VERSION ""

NS_ :

BS_:

BU_:

BO_ 2556493566 MG1IRP: 8 Vector__XXX
 SG_ MtrGnrtr1InvrtrLmtsRqstPwrCRC : 0|8@1+ (1,0) [0|255] "count" Vector__XXX
 SG_ MtrGnrtr1InvrtrLmtsRqstPwrCntr : 8|4@1+ (1,0) [0|15] "" Vector__XXX

BO_ 2556559102 PDI: 8 Vector__XXX
 SG_ PrsnnlDttAlrmRvStts : 0|3@1+ (1,0) [0|7] "" Vector__XXX
 SG_ PrsnnlDttSqnCntrEh : 8|8@1+ (1,0) [0|255] "count" Vector__XXX

BO_ 2556624638 ECCCF: 8 Vector__XXX
 SG_ CnfgrdEngnClndrMssFrtnBrndLtn1 : 0|8@1+ (0.4,0) [0|100] "%" Vector__XXX
 SG_ CnfgrdEngnClndrMssFrtnBrndLtn2 : 8|8@1+ (0.4,0) [0|100] "%" Vector__XXX

BO_ 2556690174 ECCC: 8 Vector__XXX
 SG_ EngnClndrMssFrtnBrndLtn1 : 0|8@1+ (0.4,0) [0|100] "%" Vector__XXX
 SG_ EngnClndrMssFrtnBrndLtn2 : 8|8@1+ (0.4,0) [0|100] "%" Vector__XXX

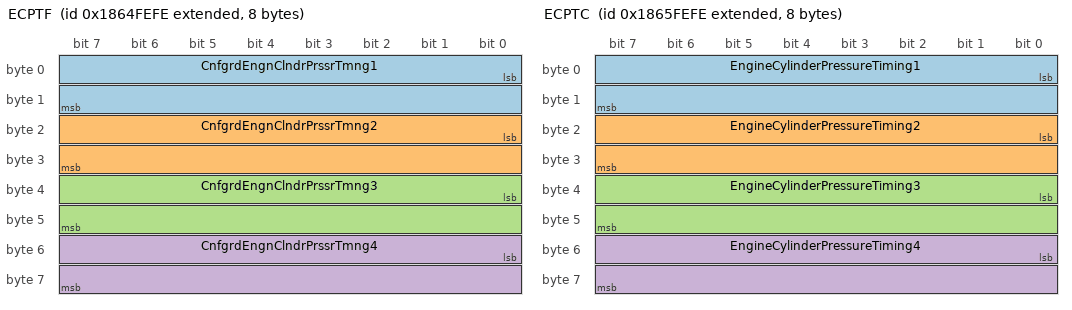
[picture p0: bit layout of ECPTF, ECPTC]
BO_ 2556755710 ECPTF: 8 Vector__XXX
 SG_ CnfgrdEngnClndrPrssrTmng1 : 0|16@1+ (0.0125,-360) [-360|443.1875] "deg" Vector__XXX
 SG_ CnfgrdEngnClndrPrssrTmng2 : 16|16@1+ (0.0125,-360) [-360|443.1875] "deg" Vector__XXX
 SG_ CnfgrdEngnClndrPrssrTmng3 : 32|16@1+ (0.0125,-360) [-360|443.1875] "deg" Vector__XXX
 SG_ CnfgrdEngnClndrPrssrTmng4 : 48|16@1+ (0.0125,-360) [-360|443.1875] "deg" Vector__XXX

BO_ 2556821246 ECPTC: 8 Vector__XXX
 SG_ EngineCylinderPressureTiming1 : 0|16@1+ (0.0125,-360) [-360|443.1875] "deg" Vector__XXX
 SG_ EngineCylinderPressureTiming2 : 16|16@1+ (0.0125,-360) [-360|443.1875] "deg" Vector__XXX
 SG_ EngineCylinderPressureTiming3 : 32|16@1+ (0.0125,-360) [-360|443.1875] "deg" Vector__XXX
 SG_ EngineCylinderPressureTiming4 : 48|16@1+ (0.0125,-360) [-360|443.1875] "deg" Vector__XXX

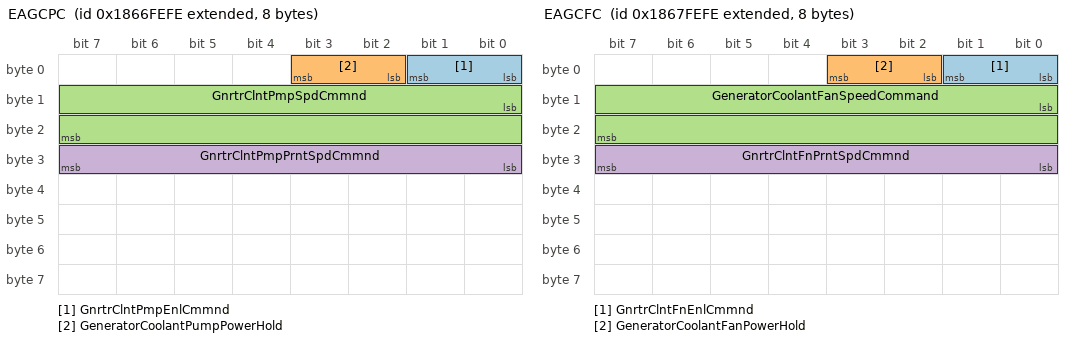
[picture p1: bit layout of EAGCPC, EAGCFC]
BO_ 2556886782 EAGCPC: 8 Vector__XXX
 SG_ GnrtrClntPmpEnlCmmnd : 0|2@1+ (1,0) [0|3] "" Vector__XXX
 SG_ GeneratorCoolantPumpPowerHold : 2|2@1+ (1,0) [0|3] "" Vector__XXX
 SG_ GnrtrClntPmpSpdCmmnd : 8|16@1+ (0.5,0) [0|32127.5] "rpm" Vector__XXX
 SG_ GnrtrClntPmpPrntSpdCmmnd : 24|8@1+ (0.5,0) [0|125] "%" Vector__XXX

BO_ 2556952318 EAGCFC: 8 Vector__XXX
 SG_ GnrtrClntFnEnlCmmnd : 0|2@1+ (1,0) [0|3] "" Vector__XXX
 SG_ GeneratorCoolantFanPowerHold : 2|2@1+ (1,0) [0|3] "" Vector__XXX
 SG_ GeneratorCoolantFanSpeedCommand : 8|16@1+ (0.5,0) [0|32127.5] "rpm" Vector__XXX
 SG_ GnrtrClntFnPrntSpdCmmnd : 24|8@1+ (0.5,0) [0|125] "%" Vector__XXX

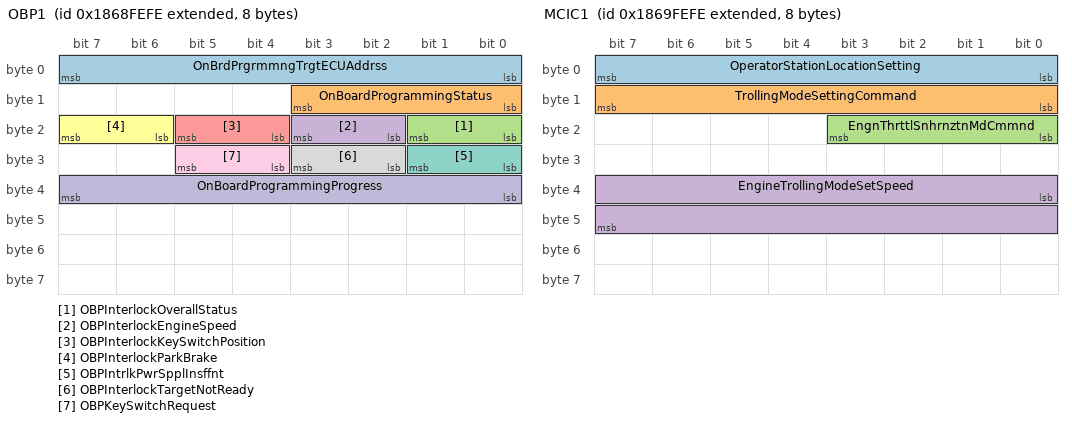
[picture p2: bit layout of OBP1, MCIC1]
BO_ 2557017854 OBP1: 8 Vector__XXX
 SG_ OnBrdPrgrmmngTrgtECUAddrss : 0|8@1+ (1,0) [0|255] "SA" Vector__XXX
 SG_ OnBoardProgrammingStatus : 8|4@1+ (1,0) [0|15] "" Vector__XXX
 SG_ OBPInterlockOverallStatus : 16|2@1+ (1,0) [0|3] "" Vector__XXX
 SG_ OBPInterlockEngineSpeed : 18|2@1+ (1,0) [0|3] "" Vector__XXX
 SG_ OBPInterlockKeySwitchPosition : 20|2@1+ (1,0) [0|3] "" Vector__XXX
 SG_ OBPInterlockParkBrake : 22|2@1+ (1,0) [0|3] "" Vector__XXX
 SG_ OBPIntrlkPwrSpplInsffnt : 24|2@1+ (1,0) [0|3] "" Vector__XXX
 SG_ OBPInterlockTargetNotReady : 26|2@1+ (1,0) [0|3] "" Vector__XXX
 SG_ OBPKeySwitchRequest : 28|2@1+ (1,0) [0|3] "" Vector__XXX
 SG_ OnBoardProgrammingProgress : 32|8@1+ (0.5,0) [0|125] "%" Vector__XXX

BO_ 2557083390 MCIC1: 8 Vector__XXX
 SG_ OperatorStationLocationSetting : 0|8@1+ (1,0) [0|250] "ID" Vector__XXX
 SG_ TrollingModeSettingCommand : 8|8@1+ (1,0) [0|255] "" Vector__XXX
 SG_ EngnThrttlSnhrnztnMdCmmnd : 16|4@1+ (1,0) [0|15] "" Vector__XXX
 SG_ EngineTrollingModeSetSpeed : 32|16@1+ (0.125,0) [0|8031.875] "rpm" Vector__XXX

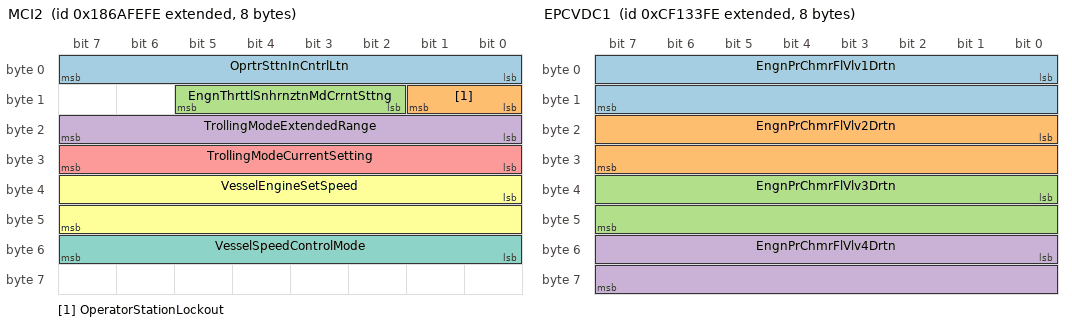
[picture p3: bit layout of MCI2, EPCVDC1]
BO_ 2557148926 MCI2: 8 Vector__XXX
 SG_ OprtrSttnInCntrlLtn : 0|8@1+ (1,0) [0|250] "ID" Vector__XXX
 SG_ OperatorStationLockout : 8|2@1+ (1,0) [0|3] "" Vector__XXX
 SG_ EngnThrttlSnhrnztnMdCrrntSttng : 10|4@1+ (1,0) [0|15] "" Vector__XXX
 SG_ TrollingModeExtendedRange : 16|8@1+ (1,0) [0|255] "" Vector__XXX
 SG_ TrollingModeCurrentSetting : 24|8@1+ (1,0) [0|255] "" Vector__XXX
 SG_ VesselEngineSetSpeed : 32|16@1+ (0.125,0) [0|8031.875] "rpm" Vector__XXX
 SG_ VesselSpeedControlMode : 48|8@1+ (1,0) [0|255] "" Vector__XXX

BO_ 2364617726 EPCVDC1: 8 Vector__XXX
 SG_ EngnPrChmrFlVlv1Drtn : 0|16@1+ (2,0) [0|128510] "micro s" Vector__XXX
 SG_ EngnPrChmrFlVlv2Drtn : 16|16@1+ (2,0) [0|128510] "micro s" Vector__XXX
 SG_ EngnPrChmrFlVlv3Drtn : 32|16@1+ (2,0) [0|128510] "micro s" Vector__XXX
 SG_ EngnPrChmrFlVlv4Drtn : 48|16@1+ (2,0) [0|128510] "micro s" Vector__XXX

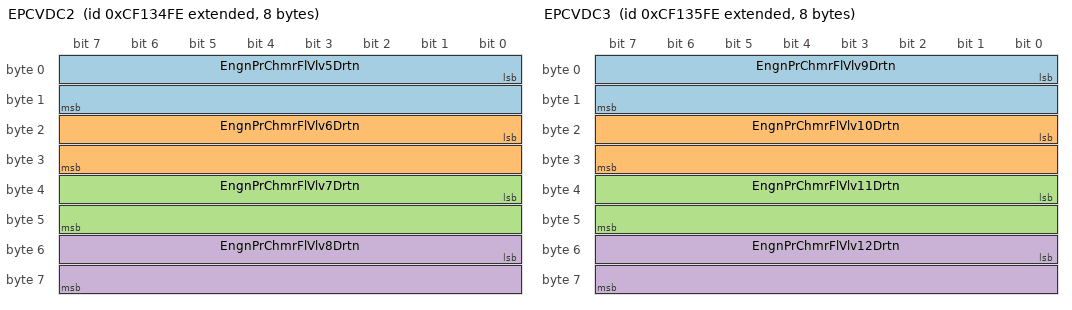
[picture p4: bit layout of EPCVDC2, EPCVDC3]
BO_ 2364617982 EPCVDC2: 8 Vector__XXX
 SG_ EngnPrChmrFlVlv5Drtn : 0|16@1+ (2,0) [0|128510] "micro s" Vector__XXX
 SG_ EngnPrChmrFlVlv6Drtn : 16|16@1+ (2,0) [0|128510] "micro s" Vector__XXX
 SG_ EngnPrChmrFlVlv7Drtn : 32|16@1+ (2,0) [0|128510] "micro s" Vector__XXX
 SG_ EngnPrChmrFlVlv8Drtn : 48|16@1+ (2,0) [0|128510] "micro s" Vector__XXX

BO_ 2364618238 EPCVDC3: 8 Vector__XXX
 SG_ EngnPrChmrFlVlv9Drtn : 0|16@1+ (2,0) [0|128510] "micro s" Vector__XXX
 SG_ EngnPrChmrFlVlv10Drtn : 16|16@1+ (2,0) [0|128510] "micro s" Vector__XXX
 SG_ EngnPrChmrFlVlv11Drtn : 32|16@1+ (2,0) [0|128510] "micro s" Vector__XXX
 SG_ EngnPrChmrFlVlv12Drtn : 48|16@1+ (2,0) [0|128510] "micro s" Vector__XXX

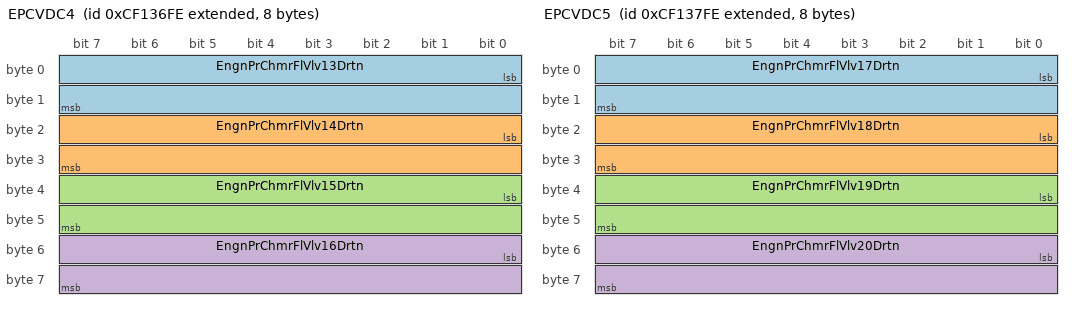
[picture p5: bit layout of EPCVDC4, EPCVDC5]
BO_ 2364618494 EPCVDC4: 8 Vector__XXX
 SG_ EngnPrChmrFlVlv13Drtn : 0|16@1+ (2,0) [0|128510] "micro s" Vector__XXX
 SG_ EngnPrChmrFlVlv14Drtn : 16|16@1+ (2,0) [0|128510] "micro s" Vector__XXX
 SG_ EngnPrChmrFlVlv15Drtn : 32|16@1+ (2,0) [0|128510] "micro s" Vector__XXX
 SG_ EngnPrChmrFlVlv16Drtn : 48|16@1+ (2,0) [0|128510] "micro s" Vector__XXX

BO_ 2364618750 EPCVDC5: 8 Vector__XXX
 SG_ EngnPrChmrFlVlv17Drtn : 0|16@1+ (2,0) [0|128510] "micro s" Vector__XXX
 SG_ EngnPrChmrFlVlv18Drtn : 16|16@1+ (2,0) [0|128510] "micro s" Vector__XXX
 SG_ EngnPrChmrFlVlv19Drtn : 32|16@1+ (2,0) [0|128510] "micro s" Vector__XXX
 SG_ EngnPrChmrFlVlv20Drtn : 48|16@1+ (2,0) [0|128510] "micro s" Vector__XXX

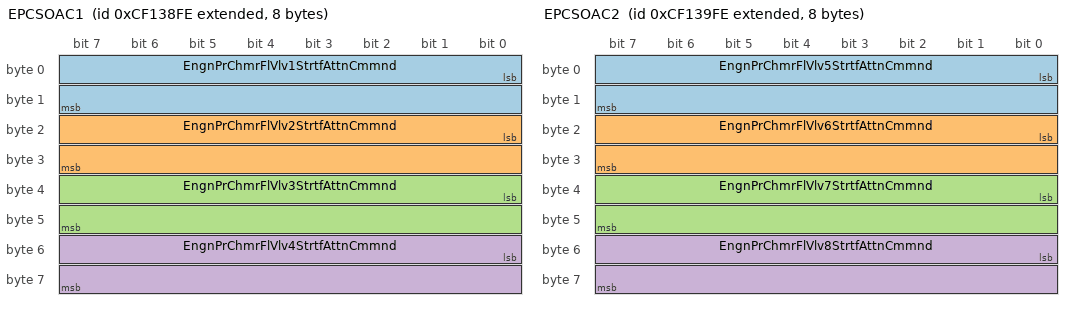
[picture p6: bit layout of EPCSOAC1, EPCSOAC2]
BO_ 2364619006 EPCSOAC1: 8 Vector__XXX
 SG_ EngnPrChmrFlVlv1StrtfAttnCmmnd : 0|16@1+ (0.0078125,-400) [-400|101.99] "deg" Vector__XXX
 SG_ EngnPrChmrFlVlv2StrtfAttnCmmnd : 16|16@1+ (0.0078125,-400) [-400|101.99] "deg" Vector__XXX
 SG_ EngnPrChmrFlVlv3StrtfAttnCmmnd : 32|16@1+ (0.0078125,-400) [-400|101.99] "deg" Vector__XXX
 SG_ EngnPrChmrFlVlv4StrtfAttnCmmnd : 48|16@1+ (0.0078125,-400) [-400|101.99] "deg" Vector__XXX

BO_ 2364619262 EPCSOAC2: 8 Vector__XXX
 SG_ EngnPrChmrFlVlv5StrtfAttnCmmnd : 0|16@1+ (0.0078125,-400) [-400|101.99] "deg" Vector__XXX
 SG_ EngnPrChmrFlVlv6StrtfAttnCmmnd : 16|16@1+ (0.0078125,-400) [-400|101.99] "deg" Vector__XXX
 SG_ EngnPrChmrFlVlv7StrtfAttnCmmnd : 32|16@1+ (0.0078125,-400) [-400|101.99] "deg" Vector__XXX
 SG_ EngnPrChmrFlVlv8StrtfAttnCmmnd : 48|16@1+ (0.0078125,-400) [-400|101.99] "deg" Vector__XXX

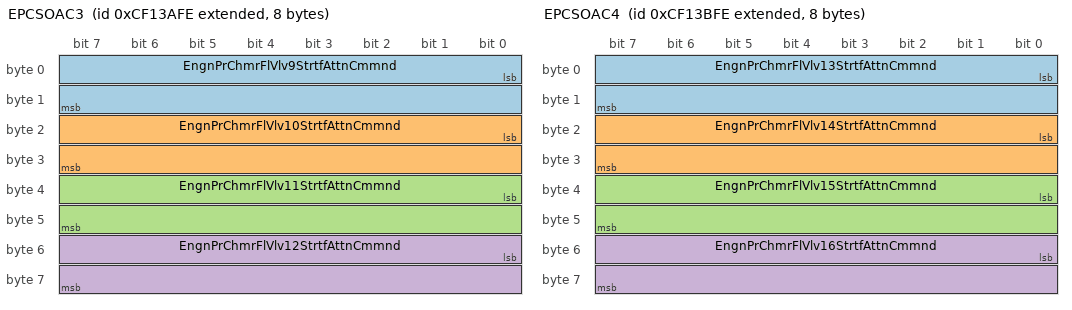
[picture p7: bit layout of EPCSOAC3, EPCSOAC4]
BO_ 2364619518 EPCSOAC3: 8 Vector__XXX
 SG_ EngnPrChmrFlVlv9StrtfAttnCmmnd : 0|16@1+ (0.0078125,-400) [-400|101.99] "deg" Vector__XXX
 SG_ EngnPrChmrFlVlv10StrtfAttnCmmnd : 16|16@1+ (0.0078125,-400) [-400|101.99] "deg" Vector__XXX
 SG_ EngnPrChmrFlVlv11StrtfAttnCmmnd : 32|16@1+ (0.0078125,-400) [-400|101.99] "deg" Vector__XXX
 SG_ EngnPrChmrFlVlv12StrtfAttnCmmnd : 48|16@1+ (0.0078125,-400) [-400|101.99] "deg" Vector__XXX

BO_ 2364619774 EPCSOAC4: 8 Vector__XXX
 SG_ EngnPrChmrFlVlv13StrtfAttnCmmnd : 0|16@1+ (0.0078125,-400) [-400|101.99] "deg" Vector__XXX
 SG_ EngnPrChmrFlVlv14StrtfAttnCmmnd : 16|16@1+ (0.0078125,-400) [-400|101.99] "deg" Vector__XXX
 SG_ EngnPrChmrFlVlv15StrtfAttnCmmnd : 32|16@1+ (0.0078125,-400) [-400|101.99] "deg" Vector__XXX
 SG_ EngnPrChmrFlVlv16StrtfAttnCmmnd : 48|16@1+ (0.0078125,-400) [-400|101.99] "deg" Vector__XXX

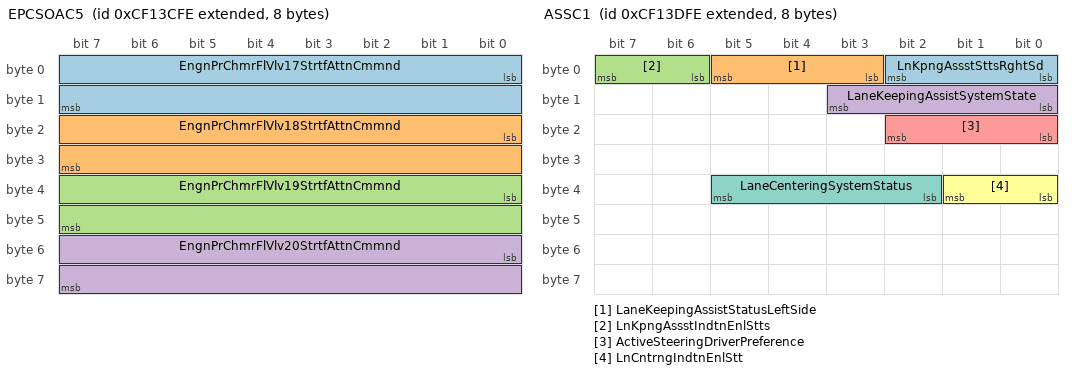
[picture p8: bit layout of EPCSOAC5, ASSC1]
BO_ 2364620030 EPCSOAC5: 8 Vector__XXX
 SG_ EngnPrChmrFlVlv17StrtfAttnCmmnd : 0|16@1+ (0.0078125,-400) [-400|101.99] "deg" Vector__XXX
 SG_ EngnPrChmrFlVlv18StrtfAttnCmmnd : 16|16@1+ (0.0078125,-400) [-400|101.99] "deg" Vector__XXX
 SG_ EngnPrChmrFlVlv19StrtfAttnCmmnd : 32|16@1+ (0.0078125,-400) [-400|101.99] "deg" Vector__XXX
 SG_ EngnPrChmrFlVlv20StrtfAttnCmmnd : 48|16@1+ (0.0078125,-400) [-400|101.99] "deg" Vector__XXX

BO_ 2364620286 ASSC1: 8 Vector__XXX
 SG_ LnKpngAssstSttsRghtSd : 0|3@1+ (1,0) [0|7] "" Vector__XXX
 SG_ LaneKeepingAssistStatusLeftSide : 3|3@1+ (1,0) [0|7] "" Vector__XXX
 SG_ LnKpngAssstIndtnEnlStts : 6|2@1+ (1,0) [0|3] "" Vector__XXX
 SG_ LaneKeepingAssistSystemState : 8|4@1+ (1,0) [0|15] "" Vector__XXX
 SG_ ActiveSteeringDriverPreference : 16|3@1+ (1,0) [0|7] "" Vector__XXX
 SG_ LnCntrngIndtnEnlStt : 32|2@1+ (1,0) [0|3] "" Vector__XXX
 SG_ LaneCenteringSystemStatus : 34|4@1+ (1,0) [0|15] "" Vector__XXX

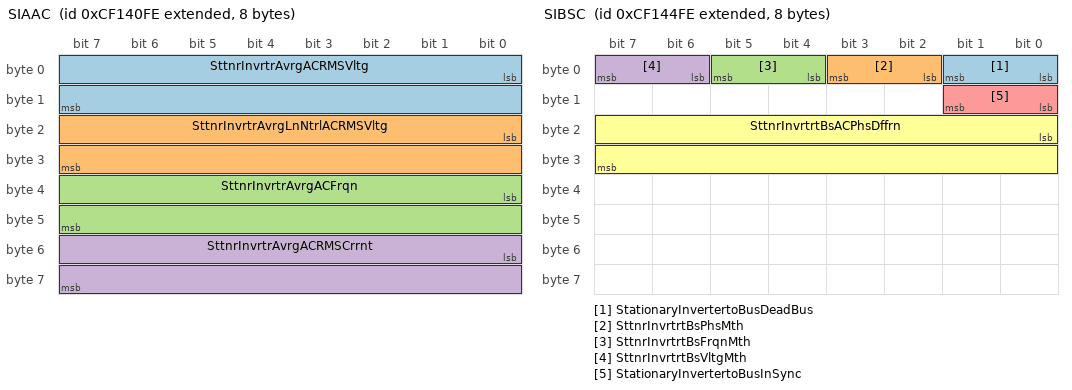
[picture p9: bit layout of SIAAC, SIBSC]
BO_ 2364621054 SIAAC: 8 Vector__XXX
 SG_ SttnrInvrtrAvrgACRMSVltg : 0|16@1+ (1,0) [0|64255] "V" Vector__XXX
 SG_ SttnrInvrtrAvrgLnNtrlACRMSVltg : 16|16@1+ (1,0) [0|64255] "V" Vector__XXX
 SG_ SttnrInvrtrAvrgACFrqn : 32|16@1+ (0.0078125,0) [0|501.9921875] "Hz" Vector__XXX
 SG_ SttnrInvrtrAvrgACRMSCrrnt : 48|16@1+ (1,0) [0|64255] "A" Vector__XXX

BO_ 2364621310 SITACR: 8 Vector__XXX
 SG_ SttnrInvrtrTtlRtvPwr : 0|32@1+ (1,-2000000000) [-2000000000|2.21108E+09] "VAr" Vector__XXX
 SG_ SttnrInvrtrOvrllPwrFtr : 32|16@1+ (0.00006103515625,-1) [-1|2.921814] "" Vector__XXX
 SG_ SttnrInvrtrOvrllPwrFtrLggng : 48|2@1+ (1,0) [0|3] "" Vector__XXX

BO_ 2364621566 SITACP: 8 Vector__XXX
 SG_ SttnrInvrtrTtlRlPwr : 0|32@1+ (1,-2000000000) [-2000000000|2.21108E+09] "W" Vector__XXX
 SG_ SttnrInvrtrTtlApprntPwr : 32|32@1+ (1,-2000000000) [-2000000000|2.21108E+09] "VA" Vector__XXX

BO_ 2364621822 SIC: 8 Vector__XXX
 SG_ SttnrInvrtrNtRdtAtmtllPrlllStt : 0|2@1+ (1,0) [0|3] "" Vector__XXX
 SG_ SttnrInvrtrAxlrShtdwnSwth : 2|2@1+ (1,0) [0|3] "" Vector__XXX

BO_ 2364622078 SIBSC: 8 Vector__XXX
 SG_ StationaryInvertertoBusDeadBus : 0|2@1+ (1,0) [0|3] "" Vector__XXX
 SG_ SttnrInvrtrtBsPhsMth : 2|2@1+ (1,0) [0|3] "" Vector__XXX
 SG_ SttnrInvrtrtBsFrqnMth : 4|2@1+ (1,0) [0|3] "" Vector__XXX
 SG_ SttnrInvrtrtBsVltgMth : 6|2@1+ (1,0) [0|3] "" Vector__XXX
 SG_ StationaryInvertertoBusInSync : 8|2@1+ (1,0) [0|3] "" Vector__XXX
 SG_ SttnrInvrtrtBsACPhsDffrn : 16|16@1+ (0.0078125,-200) [-200|301.99] "deg" Vector__XXX

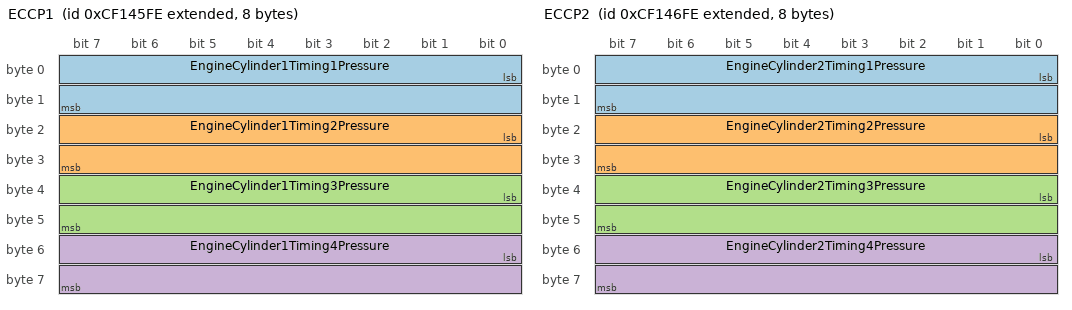
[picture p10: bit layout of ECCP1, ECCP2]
BO_ 2364622334 ECCP1: 8 Vector__XXX
 SG_ EngineCylinder1Timing1Pressure : 0|16@1+ (0.0009765625,0) [0|62.74902344] "MPa" Vector__XXX
 SG_ EngineCylinder1Timing2Pressure : 16|16@1+ (0.0009765625,0) [0|62.74902344] "MPa" Vector__XXX
 SG_ EngineCylinder1Timing3Pressure : 32|16@1+ (0.0009765625,0) [0|62.74902344] "MPa" Vector__XXX
 SG_ EngineCylinder1Timing4Pressure : 48|16@1+ (0.0009765625,0) [0|62.74902344] "MPa" Vector__XXX

BO_ 2364622590 ECCP2: 8 Vector__XXX
 SG_ EngineCylinder2Timing1Pressure : 0|16@1+ (0.0009765625,0) [0|62.74902344] "MPa" Vector__XXX
 SG_ EngineCylinder2Timing2Pressure : 16|16@1+ (0.0009765625,0) [0|62.74902344] "MPa" Vector__XXX
 SG_ EngineCylinder2Timing3Pressure : 32|16@1+ (0.0009765625,0) [0|62.74902344] "MPa" Vector__XXX
 SG_ EngineCylinder2Timing4Pressure : 48|16@1+ (0.0009765625,0) [0|62.74902344] "MPa" Vector__XXX

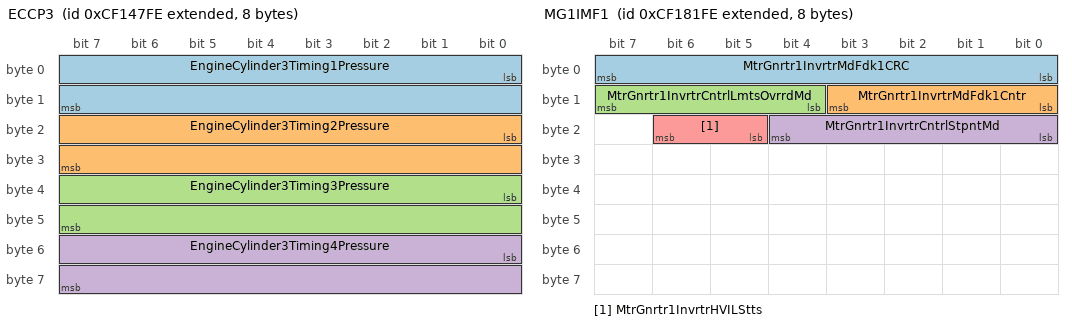
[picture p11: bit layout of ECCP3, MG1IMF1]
BO_ 2364622846 ECCP3: 8 Vector__XXX
 SG_ EngineCylinder3Timing1Pressure : 0|16@1+ (0.0009765625,0) [0|62.74902344] "MPa" Vector__XXX
 SG_ EngineCylinder3Timing2Pressure : 16|16@1+ (0.0009765625,0) [0|62.74902344] "MPa" Vector__XXX
 SG_ EngineCylinder3Timing3Pressure : 32|16@1+ (0.0009765625,0) [0|62.74902344] "MPa" Vector__XXX
 SG_ EngineCylinder3Timing4Pressure : 48|16@1+ (0.0009765625,0) [0|62.74902344] "MPa" Vector__XXX

BO_ 2364623102 ECCP4: 8 Vector__XXX
 SG_ EngineCylinder4Timing1Pressure : 0|16@1+ (0.0009765625,0) [0|62.74902344] "MPa" Vector__XXX
 SG_ EngineCylinder4Timing2Pressure : 16|16@1+ (0.0009765625,0) [0|62.74902344] "MPa" Vector__XXX
 SG_ EngineCylinder4Timing3Pressure : 32|16@1+ (0.0009765625,0) [0|62.74902344] "MPa" Vector__XXX
 SG_ EngineCylinder4Timing4Pressure : 48|16@1+ (0.0009765625,0) [0|62.74902344] "MPa" Vector__XXX

BO_ 2364623358 ECCP5: 8 Vector__XXX
 SG_ EngineCylinder5Timing1Pressure : 0|16@1+ (0.0009765625,0) [0|62.74902344] "MPa" Vector__XXX
 SG_ EngineCylinder5Timing2Pressure : 16|16@1+ (0.0009765625,0) [0|62.74902344] "MPa" Vector__XXX
 SG_ EngineCylinder5Timing3Pressure : 32|16@1+ (0.0009765625,0) [0|62.74902344] "MPa" Vector__XXX
 SG_ EngineCylinder5Timing4Pressure : 48|16@1+ (0.0009765625,0) [0|62.74902344] "MPa" Vector__XXX

BO_ 2364623614 ECCP6: 8 Vector__XXX
 SG_ EngineCylinder6Timing1Pressure : 0|16@1+ (0.0009765625,0) [0|62.74902344] "MPa" Vector__XXX
 SG_ EngineCylinder6Timing2Pressure : 16|16@1+ (0.0009765625,0) [0|62.74902344] "MPa" Vector__XXX
 SG_ EngineCylinder6Timing3Pressure : 32|16@1+ (0.0009765625,0) [0|62.74902344] "MPa" Vector__XXX
 SG_ EngineCylinder6Timing4Pressure : 48|16@1+ (0.0009765625,0) [0|62.74902344] "MPa" Vector__XXX

BO_ 2364623870 ECCP7: 8 Vector__XXX
 SG_ EngineCylinder7Timing1Pressure : 0|16@1+ (0.0009765625,0) [0|62.74902344] "MPa" Vector__XXX
 SG_ EngineCylinder7Timing2Pressure : 16|16@1+ (0.0009765625,0) [0|62.74902344] "MPa" Vector__XXX
 SG_ EngineCylinder7Timing3Pressure : 32|16@1+ (0.0009765625,0) [0|62.74902344] "MPa" Vector__XXX
 SG_ EngineCylinder7Timing4Pressure : 48|16@1+ (0.0009765625,0) [0|62.74902344] "MPa" Vector__XXX

BO_ 2364624126 ECCP8: 8 Vector__XXX
 SG_ EngineCylinder8Timing1Pressure : 0|16@1+ (0.0009765625,0) [0|62.74902344] "MPa" Vector__XXX
 SG_ EngineCylinder8Timing2Pressure : 16|16@1+ (0.0009765625,0) [0|62.74902344] "MPa" Vector__XXX
 SG_ EngineCylinder8Timing3Pressure : 32|16@1+ (0.0009765625,0) [0|62.74902344] "MPa" Vector__XXX
 SG_ EngineCylinder8Timing4Pressure : 48|16@1+ (0.0009765625,0) [0|62.74902344] "MPa" Vector__XXX

BO_ 2364624382 ECCP9: 8 Vector__XXX
 SG_ EngineCylinder9Timing1Pressure : 0|16@1+ (0.0009765625,0) [0|62.74902344] "MPa" Vector__XXX
 SG_ EngineCylinder9Timing2Pressure : 16|16@1+ (0.0009765625,0) [0|62.74902344] "MPa" Vector__XXX
 SG_ EngineCylinder9Timing3Pressure : 32|16@1+ (0.0009765625,0) [0|62.74902344] "MPa" Vector__XXX
 SG_ EngineCylinder9Timing4Pressure : 48|16@1+ (0.0009765625,0) [0|62.74902344] "MPa" Vector__XXX

BO_ 2364624638 ECCP10: 8 Vector__XXX
 SG_ EngineCylinder10Timing1Pressure : 0|16@1+ (0.0009765625,0) [0|62.74902344] "MPa" Vector__XXX
 SG_ EngineCylinder10Timing2Pressure : 16|16@1+ (0.0009765625,0) [0|62.74902344] "MPa" Vector__XXX
 SG_ EngineCylinder10Timing3Pressure : 32|16@1+ (0.0009765625,0) [0|62.74902344] "MPa" Vector__XXX
 SG_ EngineCylinder10Timing4Pressure : 48|16@1+ (0.0009765625,0) [0|62.74902344] "MPa" Vector__XXX

BO_ 2364624894 ECCP11: 8 Vector__XXX
 SG_ EngineCylinder11Timing1Pressure : 0|16@1+ (0.0009765625,0) [0|62.74902344] "MPa" Vector__XXX
 SG_ EngineCylinder11Timing2Pressure : 16|16@1+ (0.0009765625,0) [0|62.74902344] "MPa" Vector__XXX
 SG_ EngineCylinder11Timing3Pressure : 32|16@1+ (0.0009765625,0) [0|62.74902344] "MPa" Vector__XXX
 SG_ EngineCylinder11Timing4Pressure : 48|16@1+ (0.0009765625,0) [0|62.74902344] "MPa" Vector__XXX

BO_ 2364625150 ECCP12: 8 Vector__XXX
 SG_ EngineCylinder12Timing1Pressure : 0|16@1+ (0.0009765625,0) [0|62.74902344] "MPa" Vector__XXX
 SG_ EngineCylinder12Timing2Pressure : 16|16@1+ (0.0009765625,0) [0|62.74902344] "MPa" Vector__XXX
 SG_ EngineCylinder12Timing3Pressure : 32|16@1+ (0.0009765625,0) [0|62.74902344] "MPa" Vector__XXX
 SG_ EngineCylinder12Timing4Pressure : 48|16@1+ (0.0009765625,0) [0|62.74902344] "MPa" Vector__XXX

BO_ 2364625406 ECCP13: 8 Vector__XXX
 SG_ EngineCylinder13Timing1Pressure : 0|16@1+ (0.0009765625,0) [0|62.74902344] "MPa" Vector__XXX
 SG_ EngineCylinder13Timing2Pressure : 16|16@1+ (0.0009765625,0) [0|62.74902344] "MPa" Vector__XXX
 SG_ EngineCylinder13Timing3Pressure : 32|16@1+ (0.0009765625,0) [0|62.74902344] "MPa" Vector__XXX
 SG_ EngineCylinder13Timing4Pressure : 48|16@1+ (0.0009765625,0) [0|62.74902344] "MPa" Vector__XXX

BO_ 2364625662 ECCP14: 8 Vector__XXX
 SG_ EngineCylinder14Timing1Pressure : 0|16@1+ (0.0009765625,0) [0|62.74902344] "MPa" Vector__XXX
 SG_ EngineCylinder14Timing2Pressure : 16|16@1+ (0.0009765625,0) [0|62.74902344] "MPa" Vector__XXX
 SG_ EngineCylinder14Timing3Pressure : 32|16@1+ (0.0009765625,0) [0|62.74902344] "MPa" Vector__XXX
 SG_ EngineCylinder14Timing4Pressure : 48|16@1+ (0.0009765625,0) [0|62.74902344] "MPa" Vector__XXX

BO_ 2364625918 ECCP15: 8 Vector__XXX
 SG_ EngineCylinder15Timing1Pressure : 0|16@1+ (0.0009765625,0) [0|62.74902344] "MPa" Vector__XXX
 SG_ EngineCylinder15Timing2Pressure : 16|16@1+ (0.0009765625,0) [0|62.74902344] "MPa" Vector__XXX
 SG_ EngineCylinder15Timing3Pressure : 32|16@1+ (0.0009765625,0) [0|62.74902344] "MPa" Vector__XXX
 SG_ EngineCylinder15Timing4Pressure : 48|16@1+ (0.0009765625,0) [0|62.74902344] "MPa" Vector__XXX

BO_ 2364626174 ECCP16: 8 Vector__XXX
 SG_ EngineCylinder16Timing1Pressure : 0|16@1+ (0.0009765625,0) [0|62.74902344] "MPa" Vector__XXX
 SG_ EngineCylinder16Timing2Pressure : 16|16@1+ (0.0009765625,0) [0|62.74902344] "MPa" Vector__XXX
 SG_ EngineCylinder16Timing3Pressure : 32|16@1+ (0.0009765625,0) [0|62.74902344] "MPa" Vector__XXX
 SG_ EngineCylinder16Timing4Pressure : 48|16@1+ (0.0009765625,0) [0|62.74902344] "MPa" Vector__XXX

BO_ 2364626430 ECCP17: 8 Vector__XXX
 SG_ EngineCylinder17Timing1Pressure : 0|16@1+ (0.0009765625,0) [0|62.74902344] "MPa" Vector__XXX
 SG_ EngineCylinder17Timing2Pressure : 16|16@1+ (0.0009765625,0) [0|62.74902344] "MPa" Vector__XXX
 SG_ EngineCylinder17Timing3Pressure : 32|16@1+ (0.0009765625,0) [0|62.74902344] "MPa" Vector__XXX
 SG_ EngineCylinder17Timing4Pressure : 48|16@1+ (0.0009765625,0) [0|62.74902344] "MPa" Vector__XXX

BO_ 2364626686 ECCP18: 8 Vector__XXX
 SG_ EngineCylinder18Timing1Pressure : 0|16@1+ (0.0009765625,0) [0|62.74902344] "MPa" Vector__XXX
 SG_ EngineCylinder18Timing2Pressure : 16|16@1+ (0.0009765625,0) [0|62.74902344] "MPa" Vector__XXX
 SG_ EngineCylinder18Timing3Pressure : 32|16@1+ (0.0009765625,0) [0|62.74902344] "MPa" Vector__XXX
 SG_ EngineCylinder18Timing4Pressure : 48|16@1+ (0.0009765625,0) [0|62.74902344] "MPa" Vector__XXX

BO_ 2364626942 ECCP19: 8 Vector__XXX
 SG_ EngineCylinder19Timing1Pressure : 0|16@1+ (0.0009765625,0) [0|62.74902344] "MPa" Vector__XXX
 SG_ EngineCylinder19Timing2Pressure : 16|16@1+ (0.0009765625,0) [0|62.74902344] "MPa" Vector__XXX
 SG_ EngineCylinder19Timing3Pressure : 32|16@1+ (0.0009765625,0) [0|62.74902344] "MPa" Vector__XXX
 SG_ EngineCylinder19Timing4Pressure : 48|16@1+ (0.0009765625,0) [0|62.74902344] "MPa" Vector__XXX

BO_ 2364627198 ECCP20: 8 Vector__XXX
 SG_ EngineCylinder20Timing1Pressure : 0|16@1+ (0.0009765625,0) [0|62.74902344] "MPa" Vector__XXX
 SG_ EngineCylinder20Timing2Pressure : 16|16@1+ (0.0009765625,0) [0|62.74902344] "MPa" Vector__XXX
 SG_ EngineCylinder20Timing3Pressure : 32|16@1+ (0.0009765625,0) [0|62.74902344] "MPa" Vector__XXX
 SG_ EngineCylinder20Timing4Pressure : 48|16@1+ (0.0009765625,0) [0|62.74902344] "MPa" Vector__XXX

BO_ 2364627454 ECCT1: 8 Vector__XXX
 SG_ ECd1IsttsSttCstT : 0|16@1+ (0.00390625,-125) [-125|125] "deg" Vector__XXX
 SG_ ECd1IsttsCtCstT : 16|16@1+ (0.00390625,-125) [-125|125] "deg" Vector__XXX
 SG_ EngnClndr1InstntnsCmstnTmngPnt1 : 32|16@1+ (0.00390625,-125) [-125|125] "deg" Vector__XXX
 SG_ EngnClndr1InstntnsCmstnTmngPnt2 : 48|16@1+ (0.00390625,-125) [-125|125] "deg" Vector__XXX

BO_ 2364627710 ECCT2: 8 Vector__XXX
 SG_ ECd2IsttsSttCstT : 0|16@1+ (0.00390625,-125) [-125|125] "deg" Vector__XXX
 SG_ ECd2IsttsCtCstT : 16|16@1+ (0.00390625,-125) [-125|125] "deg" Vector__XXX
 SG_ EngnClndr2InstntnsCmstnTmngPnt1 : 32|16@1+ (0.00390625,-125) [-125|125] "deg" Vector__XXX
 SG_ EngnClndr2InstntnsCmstnTmngPnt2 : 48|16@1+ (0.00390625,-125) [-125|125] "deg" Vector__XXX

BO_ 2364627966 ECCT3: 8 Vector__XXX
 SG_ ECd3IsttsSttCstT : 0|16@1+ (0.00390625,-125) [-125|125] "deg" Vector__XXX
 SG_ ECd3IsttsCtCstT : 16|16@1+ (0.00390625,-125) [-125|125] "deg" Vector__XXX
 SG_ EngnClndr3InstntnsCmstnTmngPnt1 : 32|16@1+ (0.00390625,-125) [-125|125] "deg" Vector__XXX
 SG_ EngnClndr3InstntnsCmstnTmngPnt2 : 48|16@1+ (0.00390625,-125) [-125|125] "deg" Vector__XXX

BO_ 2364628222 ECCT4: 8 Vector__XXX
 SG_ ECd4IsttsSttCstT : 0|16@1+ (0.00390625,-125) [-125|125] "deg" Vector__XXX
 SG_ ECd4IsttsCtCstT : 16|16@1+ (0.00390625,-125) [-125|125] "deg" Vector__XXX
 SG_ EngnClndr4InstntnsCmstnTmngPnt1 : 32|16@1+ (0.00390625,-125) [-125|125] "deg" Vector__XXX
 SG_ EngnClndr4InstntnsCmstnTmngPnt2 : 48|16@1+ (0.00390625,-125) [-125|125] "deg" Vector__XXX

BO_ 2364628478 ECCT5: 8 Vector__XXX
 SG_ ECd5IsttsSttCstT : 0|16@1+ (0.00390625,-125) [-125|125] "deg" Vector__XXX
 SG_ ECd5IsttsCtCstT : 16|16@1+ (0.00390625,-125) [-125|125] "deg" Vector__XXX
 SG_ EngnClndr5InstntnsCmstnTmngPnt1 : 32|16@1+ (0.00390625,-125) [-125|125] "deg" Vector__XXX
 SG_ EngnClndr5InstntnsCmstnTmngPnt2 : 48|16@1+ (0.00390625,-125) [-125|125] "deg" Vector__XXX

BO_ 2364628734 ECCT6: 8 Vector__XXX
 SG_ ECd6IsttsSttCstT : 0|16@1+ (0.00390625,-125) [-125|125] "deg" Vector__XXX
 SG_ ECd6IsttsCtCstT : 16|16@1+ (0.00390625,-125) [-125|125] "deg" Vector__XXX
 SG_ EngnClndr6InstntnsCmstnTmngPnt1 : 32|16@1+ (0.00390625,-125) [-125|125] "deg" Vector__XXX
 SG_ EngnClndr6InstntnsCmstnTmngPnt2 : 48|16@1+ (0.00390625,-125) [-125|125] "deg" Vector__XXX

BO_ 2364628990 ECCT7: 8 Vector__XXX
 SG_ ECd7IsttsSttCstT : 0|16@1+ (0.00390625,-125) [-125|125] "deg" Vector__XXX
 SG_ ECd7IsttsCtCstT : 16|16@1+ (0.00390625,-125) [-125|125] "deg" Vector__XXX
 SG_ EngnClndr7InstntnsCmstnTmngPnt1 : 32|16@1+ (0.00390625,-125) [-125|125] "deg" Vector__XXX
 SG_ EngnClndr7InstntnsCmstnTmngPnt2 : 48|16@1+ (0.00390625,-125) [-125|125] "deg" Vector__XXX

BO_ 2364629246 ECCT8: 8 Vector__XXX
 SG_ ECd8IsttsSttCstT : 0|16@1+ (0.00390625,-125) [-125|125] "deg" Vector__XXX
 SG_ ECd8IsttsCtCstT : 16|16@1+ (0.00390625,-125) [-125|125] "deg" Vector__XXX
 SG_ EngnClndr8InstntnsCmstnTmngPnt1 : 32|16@1+ (0.00390625,-125) [-125|125] "deg" Vector__XXX
 SG_ EngnClndr8InstntnsCmstnTmngPnt2 : 48|16@1+ (0.00390625,-125) [-125|125] "deg" Vector__XXX

BO_ 2364629502 ECCT9: 8 Vector__XXX
 SG_ ECd9IsttsSttCstT : 0|16@1+ (0.00390625,-125) [-125|125] "deg" Vector__XXX
 SG_ ECd9IsttsCtCstT : 16|16@1+ (0.00390625,-125) [-125|125] "deg" Vector__XXX
 SG_ EngnClndr9InstntnsCmstnTmngPnt1 : 32|16@1+ (0.00390625,-125) [-125|125] "deg" Vector__XXX
 SG_ EngnClndr9InstntnsCmstnTmngPnt2 : 48|16@1+ (0.00390625,-125) [-125|125] "deg" Vector__XXX

BO_ 2364629758 ECCT10: 8 Vector__XXX
 SG_ ECd10IsttsSttCstT : 0|16@1+ (0.00390625,-125) [-125|125] "deg" Vector__XXX
 SG_ ECd10IsttsCtCstT : 16|16@1+ (0.00390625,-125) [-125|125] "deg" Vector__XXX
 SG_ ECd10IsttsCstTPt1 : 32|16@1+ (0.00390625,-125) [-125|125] "deg" Vector__XXX
 SG_ ECd10IsttsCstTPt2 : 48|16@1+ (0.00390625,-125) [-125|125] "deg" Vector__XXX

BO_ 2364630014 ECCT11: 8 Vector__XXX
 SG_ ECd11IsttsSttCstT : 0|16@1+ (0.00390625,-125) [-125|125] "deg" Vector__XXX
 SG_ ECd11IsttsCtCstT : 16|16@1+ (0.00390625,-125) [-125|125] "deg" Vector__XXX
 SG_ ECd11IsttsCstTPt1 : 32|16@1+ (0.00390625,-125) [-125|125] "deg" Vector__XXX
 SG_ ECd11IsttsCstTPt2 : 48|16@1+ (0.00390625,-125) [-125|125] "deg" Vector__XXX

BO_ 2364630270 ECCT12: 8 Vector__XXX
 SG_ ECd12IsttsSttCstT : 0|16@1+ (0.00390625,-125) [-125|125] "deg" Vector__XXX
 SG_ ECd12IsttsCtCstT : 16|16@1+ (0.00390625,-125) [-125|125] "deg" Vector__XXX
 SG_ ECd12IsttsCstTPt1 : 32|16@1+ (0.00390625,-125) [-125|125] "deg" Vector__XXX
 SG_ ECd12IsttsCstTPt2 : 48|16@1+ (0.00390625,-125) [-125|125] "deg" Vector__XXX

BO_ 2364630526 ECCT13: 8 Vector__XXX
 SG_ ECd13IsttsSttCstT : 0|16@1+ (0.00390625,-125) [-125|125] "deg" Vector__XXX
 SG_ ECd13IsttsCtCstT : 16|16@1+ (0.00390625,-125) [-125|125] "deg" Vector__XXX
 SG_ ECd13IsttsCstTPt1 : 32|16@1+ (0.00390625,-125) [-125|125] "deg" Vector__XXX
 SG_ ECd13IsttsCstTPt2 : 48|16@1+ (0.00390625,-125) [-125|125] "deg" Vector__XXX

BO_ 2364630782 ECCT14: 8 Vector__XXX
 SG_ ECd14IsttsSttCstT : 0|16@1+ (0.00390625,-125) [-125|125] "deg" Vector__XXX
 SG_ ECd14IsttsCtCstT : 16|16@1+ (0.00390625,-125) [-125|125] "deg" Vector__XXX
 SG_ ECd14IsttsCstTPt1 : 32|16@1+ (0.00390625,-125) [-125|125] "deg" Vector__XXX
 SG_ ECd14IsttsCstTPt2 : 48|16@1+ (0.00390625,-125) [-125|125] "deg" Vector__XXX

BO_ 2364631038 ECCT15: 8 Vector__XXX
 SG_ ECd15IsttsSttCstT : 0|16@1+ (0.00390625,-125) [-125|125] "deg" Vector__XXX
 SG_ ECd15IsttsCtCstT : 16|16@1+ (0.00390625,-125) [-125|125] "deg" Vector__XXX
 SG_ ECd15IsttsCstTPt1 : 32|16@1+ (0.00390625,-125) [-125|125] "deg" Vector__XXX
 SG_ ECd15IsttsCstTPt2 : 48|16@1+ (0.00390625,-125) [-125|125] "deg" Vector__XXX

BO_ 2364631294 ECCT16: 8 Vector__XXX
 SG_ ECd16IsttsSttCstT : 0|16@1+ (0.00390625,-125) [-125|125] "deg" Vector__XXX
 SG_ ECd16IsttsCtCstT : 16|16@1+ (0.00390625,-125) [-125|125] "deg" Vector__XXX
 SG_ ECd16IsttsCstTPt1 : 32|16@1+ (0.00390625,-125) [-125|125] "deg" Vector__XXX
 SG_ ECd16IsttsCstTPt2 : 48|16@1+ (0.00390625,-125) [-125|125] "deg" Vector__XXX

BO_ 2364631550 ECCT17: 8 Vector__XXX
 SG_ ECd17IsttsSttCstT : 0|16@1+ (0.00390625,-125) [-125|125] "deg" Vector__XXX
 SG_ ECd17IsttsCtCstT : 16|16@1+ (0.00390625,-125) [-125|125] "deg" Vector__XXX
 SG_ ECd17IsttsCstTPt1 : 32|16@1+ (0.00390625,-125) [-125|125] "deg" Vector__XXX
 SG_ ECd17IsttsCstTPt2 : 48|16@1+ (0.00390625,-125) [-125|125] "deg" Vector__XXX

BO_ 2364631806 ECCT18: 8 Vector__XXX
 SG_ ECd18IsttsSttCstT : 0|16@1+ (0.00390625,-125) [-125|125] "deg" Vector__XXX
 SG_ ECd18IsttsCtCstT : 16|16@1+ (0.00390625,-125) [-125|125] "deg" Vector__XXX
 SG_ ECd18IsttsCstTPt1 : 32|16@1+ (0.00390625,-125) [-125|125] "deg" Vector__XXX
 SG_ ECd18IsttsCstTPt2 : 48|16@1+ (0.00390625,-125) [-125|125] "deg" Vector__XXX

BO_ 2364632062 ECCT19: 8 Vector__XXX
 SG_ ECd19IsttsSttCstT : 0|16@1+ (0.00390625,-125) [-125|125] "deg" Vector__XXX
 SG_ ECd19IsttsCtCstT : 16|16@1+ (0.00390625,-125) [-125|125] "deg" Vector__XXX
 SG_ ECd19IsttsCstTPt1 : 32|16@1+ (0.00390625,-125) [-125|125] "deg" Vector__XXX
 SG_ ECd19IsttsCstTPt2 : 48|16@1+ (0.00390625,-125) [-125|125] "deg" Vector__XXX

BO_ 2364632318 ECCT20: 8 Vector__XXX
 SG_ ECd20IsttsSttCstT : 0|16@1+ (0.00390625,-125) [-125|125] "deg" Vector__XXX
 SG_ ECd20IsttsCtCstT : 16|16@1+ (0.00390625,-125) [-125|125] "deg" Vector__XXX
 SG_ ECd20IsttsCstTPt1 : 32|16@1+ (0.00390625,-125) [-125|125] "deg" Vector__XXX
 SG_ ECd20IsttsCstTPt2 : 48|16@1+ (0.00390625,-125) [-125|125] "deg" Vector__XXX

BO_ 2364632574 EECM1: 8 Vector__XXX
 SG_ ECd1IsttsPCstPssT : 0|16@1+ (0.00390625,-125) [-125|125] "deg" Vector__XXX
 SG_ ECd1IsttsIdtdMEtvPss : 16|16@1+ (0.0001220703125,-1) [-1|6.84362793] "MPa" Vector__XXX
 SG_ ECd1IdtdMEtvPssCtV : 32|8@1+ (0.04,0) [0|10] "%" Vector__XXX
 SG_ EngineCylinder1MisfireRate : 40|8@1+ (0.4,0) [0|100] "%" Vector__XXX

BO_ 2364632830 EECM2: 8 Vector__XXX
 SG_ ECd2IsttsPCstPssT : 0|16@1+ (0.00390625,-125) [-125|125] "deg" Vector__XXX
 SG_ ECd2IsttsIdtdMEtvPss : 16|16@1+ (0.0001220703125,-1) [-1|6.84362793] "MPa" Vector__XXX
 SG_ ECd2IdtdMEtvPssCtV : 32|8@1+ (0.04,0) [0|10] "%" Vector__XXX
 SG_ EngineCylinder2MisfireRate : 40|8@1+ (0.4,0) [0|100] "%" Vector__XXX

BO_ 2364633086 EECM3: 8 Vector__XXX
 SG_ ECd3IsttsPCstPssT : 0|16@1+ (0.00390625,-125) [-125|125] "deg" Vector__XXX
 SG_ ECd3IsttsIdtdMEtvPss : 16|16@1+ (0.0001220703125,-1) [-1|6.84362793] "MPa" Vector__XXX
 SG_ ECd3IdtdMEtvPssCtV : 32|8@1+ (0.04,0) [0|10] "%" Vector__XXX
 SG_ EngineCylinder3MisfireRate : 40|8@1+ (0.4,0) [0|100] "%" Vector__XXX

BO_ 2364633342 EECM4: 8 Vector__XXX
 SG_ ECd4IsttsPCstPssT : 0|16@1+ (0.00390625,-125) [-125|125] "deg" Vector__XXX
 SG_ ECd4IsttsIdtdMEtvPss : 16|16@1+ (0.0001220703125,-1) [-1|6.84362793] "MPa" Vector__XXX
 SG_ ECd4IdtdMEtvPssCtV : 32|8@1+ (0.04,0) [0|10] "%" Vector__XXX
 SG_ EngineCylinder4MisfireRate : 40|8@1+ (0.4,0) [0|100] "%" Vector__XXX

BO_ 2364633598 EECM5: 8 Vector__XXX
 SG_ ECd5IsttsPCstPssT : 0|16@1+ (0.00390625,-125) [-125|125] "deg" Vector__XXX
 SG_ ECd5IsttsIdtdMEtvPss : 16|16@1+ (0.0001220703125,-1) [-1|6.84362793] "MPa" Vector__XXX
 SG_ ECd5IdtdMEtvPssCtV : 32|8@1+ (0.04,0) [0|10] "%" Vector__XXX
 SG_ EngineCylinder5MisfireRate : 40|8@1+ (0.4,0) [0|100] "%" Vector__XXX

BO_ 2364633854 EECM6: 8 Vector__XXX
 SG_ ECd6IsttsPCstPssT : 0|16@1+ (0.00390625,-125) [-125|125] "deg" Vector__XXX
 SG_ ECd6IsttsIdtdMEtvPss : 16|16@1+ (0.0001220703125,-1) [-1|6.84362793] "MPa" Vector__XXX
 SG_ ECd6IdtdMEtvPssCtV : 32|8@1+ (0.04,0) [0|10] "%" Vector__XXX
 SG_ EngineCylinder6MisfireRate : 40|8@1+ (0.4,0) [0|100] "%" Vector__XXX

BO_ 2364634110 EECM7: 8 Vector__XXX
 SG_ ECd7IsttsPCstPssT : 0|16@1+ (0.00390625,-125) [-125|125] "deg" Vector__XXX
 SG_ ECd7IsttsIdtdMEtvPss : 16|16@1+ (0.0001220703125,-1) [-1|6.84362793] "MPa" Vector__XXX
 SG_ ECd7IdtdMEtvPssCtV : 32|8@1+ (0.04,0) [0|10] "%" Vector__XXX
 SG_ EngineCylinder7MisfireRate : 40|8@1+ (0.4,0) [0|100] "%" Vector__XXX

BO_ 2364634366 EECM8: 8 Vector__XXX
 SG_ ECd8IsttsPCstPssT : 0|16@1+ (0.00390625,-125) [-125|125] "deg" Vector__XXX
 SG_ ECd8IsttsIdtdMEtvPss : 16|16@1+ (0.0001220703125,-1) [-1|6.84362793] "MPa" Vector__XXX
 SG_ ECd8IdtdMEtvPssCtV : 32|8@1+ (0.04,0) [0|10] "%" Vector__XXX
 SG_ EngineCylinder8MisfireRate : 40|8@1+ (0.4,0) [0|100] "%" Vector__XXX

BO_ 2364634622 EECM9: 8 Vector__XXX
 SG_ ECd9IsttsPCstPssT : 0|16@1+ (0.00390625,-125) [-125|125] "deg" Vector__XXX
 SG_ ECd9IsttsIdtdMEtvPss : 16|16@1+ (0.0001220703125,-1) [-1|6.84362793] "MPa" Vector__XXX
 SG_ ECd9IdtdMEtvPssCtV : 32|8@1+ (0.04,0) [0|10] "%" Vector__XXX
 SG_ EngineCylinder9MisfireRate : 40|8@1+ (0.4,0) [0|100] "%" Vector__XXX

BO_ 2364634878 EECM10: 8 Vector__XXX
 SG_ ECd10IsttsPCstPssT : 0|16@1+ (0.00390625,-125) [-125|125] "deg" Vector__XXX
 SG_ ECd10IsttsIdtdMEtvPss : 16|16@1+ (0.0001220703125,-1) [-1|6.84362793] "MPa" Vector__XXX
 SG_ ECd10IdtdMEtvPssCtV : 32|8@1+ (0.04,0) [0|10] "%" Vector__XXX
 SG_ EngineCylinder10MisfireRate : 40|8@1+ (0.4,0) [0|100] "%" Vector__XXX

BO_ 2364635134 EECM11: 8 Vector__XXX
 SG_ ECd11IsttsPCstPssT : 0|16@1+ (0.00390625,-125) [-125|125] "deg" Vector__XXX
 SG_ ECd11IsttsIdtdMEtvPss : 16|16@1+ (0.0001220703125,-1) [-1|6.84362793] "MPa" Vector__XXX
 SG_ ECd11IdtdMEtvPssCtV : 32|8@1+ (0.04,0) [0|10] "%" Vector__XXX
 SG_ EngineCylinder11MisfireRate : 40|8@1+ (0.4,0) [0|100] "%" Vector__XXX

BO_ 2364635390 EECM12: 8 Vector__XXX
 SG_ ECd12IsttsPCstPssT : 0|16@1+ (0.00390625,-125) [-125|125] "deg" Vector__XXX
 SG_ ECd12IsttsIdtdMEtvPss : 16|16@1+ (0.0001220703125,-1) [-1|6.84362793] "MPa" Vector__XXX
 SG_ ECd12IdtdMEtvPssCtV : 32|8@1+ (0.04,0) [0|10] "%" Vector__XXX
 SG_ EngineCylinder12MisfireRate : 40|8@1+ (0.4,0) [0|100] "%" Vector__XXX

BO_ 2364635646 EECM13: 8 Vector__XXX
 SG_ ECd13IsttsPCstPssT : 0|16@1+ (0.00390625,-125) [-125|125] "deg" Vector__XXX
 SG_ ECd13IsttsIdtdMEtvPss : 16|16@1+ (0.0001220703125,-1) [-1|6.84362793] "MPa" Vector__XXX
 SG_ ECd13IdtdMEtvPssCtV : 32|8@1+ (0.04,0) [0|10] "%" Vector__XXX
 SG_ EngineCylinder13MisfireRate : 40|8@1+ (0.4,0) [0|100] "%" Vector__XXX

BO_ 2364635902 EECM14: 8 Vector__XXX
 SG_ ECd14IsttsPCstPssT : 0|16@1+ (0.00390625,-125) [-125|125] "deg" Vector__XXX
 SG_ ECd14IsttsIdtdMEtvPss : 16|16@1+ (0.0001220703125,-1) [-1|6.84362793] "MPa" Vector__XXX
 SG_ ECd14IdtdMEtvPssCtV : 32|8@1+ (0.04,0) [0|10] "%" Vector__XXX
 SG_ EngineCylinder14MisfireRate : 40|8@1+ (0.4,0) [0|100] "%" Vector__XXX

BO_ 2364636158 EECM15: 8 Vector__XXX
 SG_ ECd15IsttsPCstPssT : 0|16@1+ (0.00390625,-125) [-125|125] "deg" Vector__XXX
 SG_ ECd15IsttsIdtdMEtvPss : 16|16@1+ (0.0001220703125,-1) [-1|6.84362793] "MPa" Vector__XXX
 SG_ ECd15IdtdMEtvPssCtV : 32|8@1+ (0.04,0) [0|10] "%" Vector__XXX
 SG_ EngineCylinder15MisfireRate : 40|8@1+ (0.4,0) [0|100] "%" Vector__XXX

BO_ 2364636414 EECM16: 8 Vector__XXX
 SG_ ECd16IsttsPCstPssT : 0|16@1+ (0.00390625,-125) [-125|125] "deg" Vector__XXX
 SG_ ECd16IsttsIdtdMEtvPss : 16|16@1+ (0.0001220703125,-1) [-1|6.84362793] "MPa" Vector__XXX
 SG_ ECd16IdtdMEtvPssCtV : 32|8@1+ (0.04,0) [0|10] "%" Vector__XXX
 SG_ EngineCylinder16MisfireRate : 40|8@1+ (0.4,0) [0|100] "%" Vector__XXX

BO_ 2364636670 EECM17: 8 Vector__XXX
 SG_ ECd17IsttsPCstPssT : 0|16@1+ (0.00390625,-125) [-125|125] "deg" Vector__XXX
 SG_ ECd17IsttsIdtdMEtvPss : 16|16@1+ (0.0001220703125,-1) [-1|6.84362793] "MPa" Vector__XXX
 SG_ ECd17IdtdMEtvPssCtV : 32|8@1+ (0.04,0) [0|10] "%" Vector__XXX
 SG_ EngineCylinder17MisfireRate : 40|8@1+ (0.4,0) [0|100] "%" Vector__XXX

BO_ 2364636926 EECM18: 8 Vector__XXX
 SG_ ECd18IsttsPCstPssT : 0|16@1+ (0.00390625,-125) [-125|125] "deg" Vector__XXX
 SG_ ECd18IsttsIdtdMEtvPss : 16|16@1+ (0.0001220703125,-1) [-1|6.84362793] "MPa" Vector__XXX
 SG_ ECd18IdtdMEtvPssCtV : 32|8@1+ (0.04,0) [0|10] "%" Vector__XXX
 SG_ EngineCylinder18MisfireRate : 40|8@1+ (0.4,0) [0|100] "%" Vector__XXX

BO_ 2364637182 EECM19: 8 Vector__XXX
 SG_ ECd19IsttsPCstPssT : 0|16@1+ (0.00390625,-125) [-125|125] "deg" Vector__XXX
 SG_ ECd19IsttsIdtdMEtvPss : 16|16@1+ (0.0001220703125,-1) [-1|6.84362793] "MPa" Vector__XXX
 SG_ ECd19IdtdMEtvPssCtV : 32|8@1+ (0.04,0) [0|10] "%" Vector__XXX
 SG_ EngineCylinder19MisfireRate : 40|8@1+ (0.4,0) [0|100] "%" Vector__XXX

BO_ 2364637438 EECM20: 8 Vector__XXX
 SG_ ECd20IsttsPCstPssT : 0|16@1+ (0.00390625,-125) [-125|125] "deg" Vector__XXX
 SG_ ECd20IsttsIdtdMEtvPss : 16|16@1+ (0.0001220703125,-1) [-1|6.84362793] "MPa" Vector__XXX
 SG_ ECd20IdtdMEtvPssCtV : 32|8@1+ (0.04,0) [0|10] "%" Vector__XXX
 SG_ EngineCylinder20MisfireRate : 40|8@1+ (0.4,0) [0|100] "%" Vector__XXX

BO_ 2364637694 MG1IMF1: 8 Vector__XXX
 SG_ MtrGnrtr1InvrtrMdFdk1CRC : 0|8@1+ (1,0) [0|255] "count" Vector__XXX
 SG_ MtrGnrtr1InvrtrMdFdk1Cntr : 8|4@1+ (1,0) [0|15] "" Vector__XXX
 SG_ MtrGnrtr1InvrtrCntrlLmtsOvrrdMd : 12|4@1+ (1,0) [0|15] "" Vector__XXX
 SG_ MtrGnrtr1InvrtrCntrlStpntMd : 16|5@1+ (1,0) [0|31] "" Vector__XXX
 SG_ MtrGnrtr1InvrtrHVILStts : 21|2@1+ (1,0) [0|3] "" Vector__XXX

BO_ 2565964542 MG1ILAP: 8 Vector__XXX
 SG_ MtrGnrtr1InvrtrLmtsAtvPwrCRC : 0|8@1+ (1,0) [0|255] "count" Vector__XXX
 SG_ MtrGnrtr1InvrtrLmtsAtvPwrCntr : 8|4@1+ (1,0) [0|15] "" Vector__XXX

BO_ 2565964798 MG1ILAM: 8 Vector__XXX
 SG_ MtrGnrtr1InvrtrLmtsAtvMhnlCRC : 0|8@1+ (1,0) [0|255] "count" Vector__XXX
 SG_ MtrGnrtr1InvrtrLmtsAtvMhnlCntr : 8|4@1+ (1,0) [0|15] "" Vector__XXX

BO_ 2565965054 MG1ILADC: 8 Vector__XXX
 SG_ MtrGnrtr1InvrtrLmtsAtvDCSdCRC : 0|8@1+ (1,0) [0|255] "count" Vector__XXX
 SG_ MtrGnrtr1InvrtrLmtsAtvDCSdCntr : 8|4@1+ (1,0) [0|15] "" Vector__XXX

BO_ 2565965310 MG1ILV: 8 Vector__XXX
 SG_ MtrGnrtr1InvrtrSwthdIgntnVltg : 0|16@1+ (0.05,0) [0|3212.75] "V" Vector__XXX
 SG_ MtrGnrtr1InvrtrUnswthdSLIVltg : 16|16@1+ (0.05,0) [0|3212.75] "V" Vector__XXX

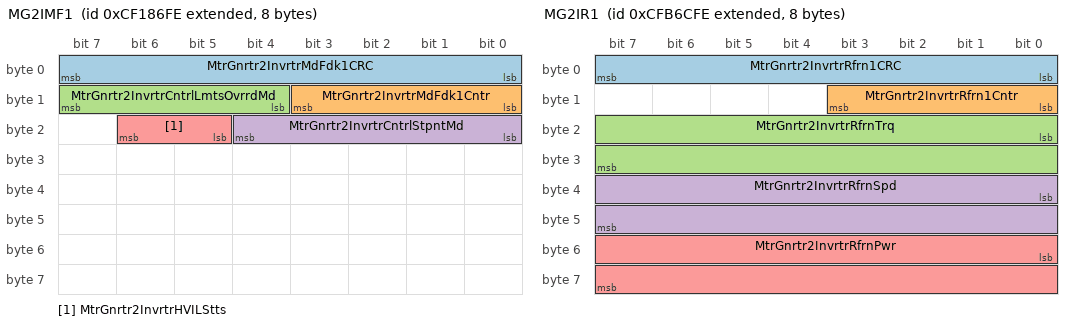
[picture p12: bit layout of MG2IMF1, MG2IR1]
BO_ 2364638974 MG2IMF1: 8 Vector__XXX
 SG_ MtrGnrtr2InvrtrMdFdk1CRC : 0|8@1+ (1,0) [0|255] "count" Vector__XXX
 SG_ MtrGnrtr2InvrtrMdFdk1Cntr : 8|4@1+ (1,0) [0|15] "" Vector__XXX
 SG_ MtrGnrtr2InvrtrCntrlLmtsOvrrdMd : 12|4@1+ (1,0) [0|15] "" Vector__XXX
 SG_ MtrGnrtr2InvrtrCntrlStpntMd : 16|5@1+ (1,0) [0|31] "" Vector__XXX
 SG_ MtrGnrtr2InvrtrHVILStts : 21|2@1+ (1,0) [0|3] "" Vector__XXX

BO_ 2565965822 MG2ILAP: 8 Vector__XXX
 SG_ MtrGnrtr2InvrtrLmtsAtvPwrCRC : 0|8@1+ (1,0) [0|255] "count" Vector__XXX
 SG_ MtrGnrtr2InvrtrLmtsAtvPwrCntr : 8|4@1+ (1,0) [0|15] "" Vector__XXX

BO_ 2565966078 MG2ILAM: 8 Vector__XXX
 SG_ MtrGnrtr2InvrtrLmtsAtvMhnlCRC : 0|8@1+ (1,0) [0|255] "count" Vector__XXX
 SG_ MtrGnrtr2InvrtrLmtsAtvMhnlCntr : 8|4@1+ (1,0) [0|15] "" Vector__XXX

BO_ 2565966334 MG2ILADC: 8 Vector__XXX
 SG_ MtrGnrtr2InvrtrLmtsAtvDCSdCRC : 0|8@1+ (1,0) [0|255] "count" Vector__XXX
 SG_ MtrGnrtr2InvrtrLmtsAtvDCSdCntr : 8|4@1+ (1,0) [0|15] "" Vector__XXX

BO_ 2565966590 MG2ILV: 8 Vector__XXX
 SG_ MtrGnrtr2InvrtrSwthdIgntnVltg : 0|16@1+ (0.05,0) [0|3212.75] "V" Vector__XXX
 SG_ MtrGnrtr2InvrtrUnswthdSLIVltg : 16|16@1+ (0.05,0) [0|3212.75] "V" Vector__XXX

BO_ 2365287678 MG2IR1: 8 Vector__XXX
 SG_ MtrGnrtr2InvrtrRfrn1CRC : 0|8@1+ (1,0) [0|255] "count" Vector__XXX
 SG_ MtrGnrtr2InvrtrRfrn1Cntr : 8|4@1+ (1,0) [0|15] "" Vector__XXX
 SG_ MtrGnrtr2InvrtrRfrnTrq : 16|16@1+ (0.5,0) [0|32127.5] "Nm" Vector__XXX
 SG_ MtrGnrtr2InvrtrRfrnSpd : 32|16@1+ (4,0) [0|257020] "rpm" Vector__XXX
 SG_ MtrGnrtr2InvrtrRfrnPwr : 48|16@1+ (0.0625,0) [0|4015.9375] "kW" Vector__XXX

BO_ 2365287934 MG2IS1: 8 Vector__XXX
 SG_ MtrGnrtr2InvrtrStts1CRC : 0|8@1+ (1,0) [0|255] "count" Vector__XXX
 SG_ MtrGnrtr2InvrtrStts1Cntr : 8|4@1+ (1,0) [0|15] "" Vector__XXX
 SG_ MotorGenerator2Speed : 24|16@1+ (0.00390625,-125) [-125|125.99609375] "%" Vector__XXX

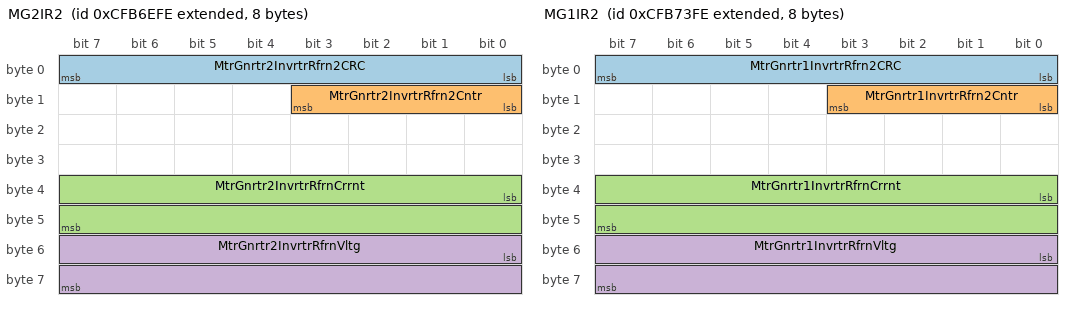
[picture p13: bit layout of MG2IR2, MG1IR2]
BO_ 2365288190 MG2IR2: 8 Vector__XXX
 SG_ MtrGnrtr2InvrtrRfrn2CRC : 0|8@1+ (1,0) [0|255] "count" Vector__XXX
 SG_ MtrGnrtr2InvrtrRfrn2Cntr : 8|4@1+ (1,0) [0|15] "" Vector__XXX
 SG_ MtrGnrtr2InvrtrRfrnCrrnt : 32|16@1+ (0.125,0) [0|8031.875] "A" Vector__XXX
 SG_ MtrGnrtr2InvrtrRfrnVltg : 48|16@1+ (0.125,0) [0|8031.875] "V" Vector__XXX

BO_ 2566615038 MG2IT: 8 Vector__XXX
 SG_ MtrGnrtr2InvrtrTmprtr1 : 0|8@1+ (1,-40) [-40|210] "degC" Vector__XXX
 SG_ MtrGnrtr2InvrtrTmprtr2 : 8|8@1+ (1,-40) [-40|210] "degC" Vector__XXX
 SG_ MtrGnrtr2InvrtrTmprtr3 : 16|8@1+ (1,-40) [-40|210] "degC" Vector__XXX
 SG_ MtrGnrtr2InvrtrTmprtr4 : 24|8@1+ (1,-40) [-40|210] "degC" Vector__XXX

BO_ 2566615294 MG2IMT: 8 Vector__XXX
 SG_ MotorGenerator2Temperature1 : 0|8@1+ (1,-40) [-40|210] "degC" Vector__XXX
 SG_ MotorGenerator2Temperature2 : 8|8@1+ (1,-40) [-40|210] "degC" Vector__XXX
 SG_ MotorGenerator2Temperature3 : 16|8@1+ (1,-40) [-40|210] "degC" Vector__XXX
 SG_ MotorGenerator2Temperature4 : 24|8@1+ (1,-40) [-40|210] "degC" Vector__XXX

BO_ 2566615550 MG1IMT: 8 Vector__XXX
 SG_ MotorGenerator1Temperature1 : 0|8@1+ (1,-40) [-40|210] "degC" Vector__XXX
 SG_ MotorGenerator1Temperature2 : 8|8@1+ (1,-40) [-40|210] "degC" Vector__XXX
 SG_ MotorGenerator1Temperature3 : 16|8@1+ (1,-40) [-40|210] "degC" Vector__XXX
 SG_ MotorGenerator1Temperature4 : 24|8@1+ (1,-40) [-40|210] "degC" Vector__XXX

BO_ 2566615806 MG1IT: 8 Vector__XXX
 SG_ MtrGnrtr1InvrtrTmprtr1 : 0|8@1+ (1,-40) [-40|210] "degC" Vector__XXX
 SG_ MtrGnrtr1InvrtrTmprtr2 : 8|8@1+ (1,-40) [-40|210] "degC" Vector__XXX
 SG_ MtrGnrtr1InvrtrTmprtr3 : 16|8@1+ (1,-40) [-40|210] "degC" Vector__XXX
 SG_ MtrGnrtr1InvrtrTmprtr4 : 24|8@1+ (1,-40) [-40|210] "degC" Vector__XXX

BO_ 2365289470 MG1IR2: 8 Vector__XXX
 SG_ MtrGnrtr1InvrtrRfrn2CRC : 0|8@1+ (1,0) [0|255] "count" Vector__XXX
 SG_ MtrGnrtr1InvrtrRfrn2Cntr : 8|4@1+ (1,0) [0|15] "" Vector__XXX
 SG_ MtrGnrtr1InvrtrRfrnCrrnt : 32|16@1+ (0.125,0) [0|8031.875] "A" Vector__XXX
 SG_ MtrGnrtr1InvrtrRfrnVltg : 48|16@1+ (0.125,0) [0|8031.875] "V" Vector__XXX

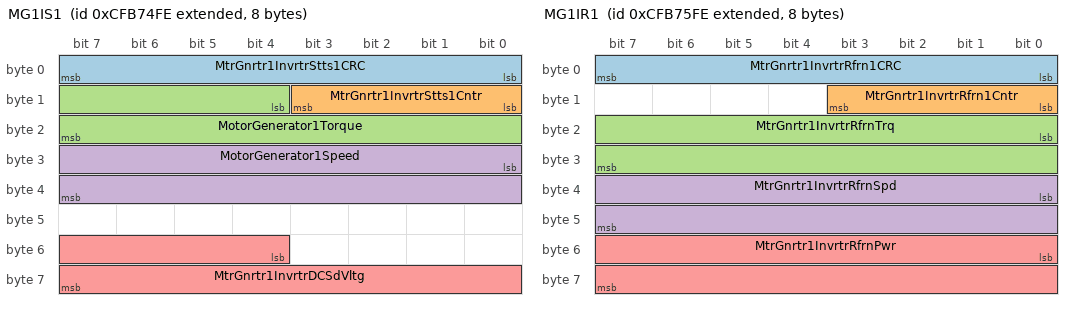
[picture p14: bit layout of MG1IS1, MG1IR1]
BO_ 2365289726 MG1IS1: 8 Vector__XXX
 SG_ MtrGnrtr1InvrtrStts1CRC : 0|8@1+ (1,0) [0|255] "count" Vector__XXX
 SG_ MtrGnrtr1InvrtrStts1Cntr : 8|4@1+ (1,0) [0|15] "" Vector__XXX
 SG_ MotorGenerator1Torque : 12|12@1+ (42370,-125) [-125|125.9375] "%" Vector__XXX
 SG_ MotorGenerator1Speed : 24|16@1+ (0.00390625,-125) [-125|125.99609375] "%" Vector__XXX
 SG_ MtrGnrtr1InvrtrDCSdVltg : 52|12@1+ (42370,-125) [-125|125.9375] "%" Vector__XXX

BO_ 2365289982 MG1IR1: 8 Vector__XXX
 SG_ MtrGnrtr1InvrtrRfrn1CRC : 0|8@1+ (1,0) [0|255] "count" Vector__XXX
 SG_ MtrGnrtr1InvrtrRfrn1Cntr : 8|4@1+ (1,0) [0|15] "" Vector__XXX
 SG_ MtrGnrtr1InvrtrRfrnTrq : 16|16@1+ (0.5,0) [0|32127.5] "Nm" Vector__XXX
 SG_ MtrGnrtr1InvrtrRfrnSpd : 32|16@1+ (4,0) [0|257020] "rpm" Vector__XXX
 SG_ MtrGnrtr1InvrtrRfrnPwr : 48|16@1+ (0.0625,0) [0|4015.9375] "kW" Vector__XXX

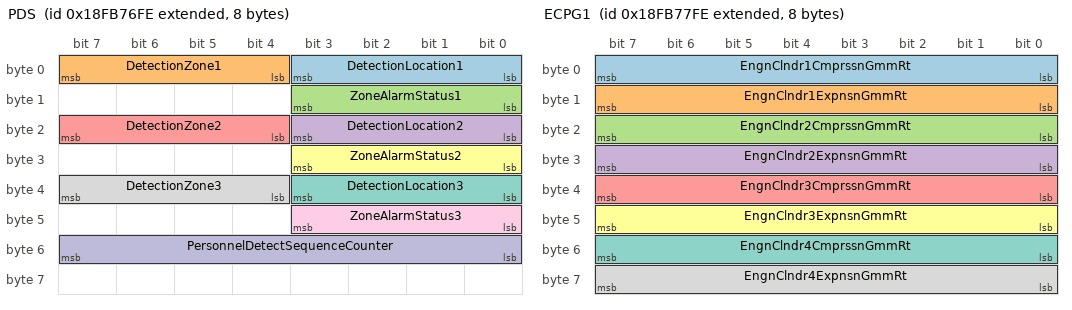
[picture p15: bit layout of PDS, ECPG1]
BO_ 2566616830 PDS: 8 Vector__XXX
 SG_ DetectionLocation1 : 0|4@1+ (1,0) [0|13] "count" Vector__XXX
 SG_ DetectionZone1 : 4|4@1+ (1,0) [0|13] "count" Vector__XXX
 SG_ ZoneAlarmStatus1 : 8|4@1+ (1,0) [0|15] "" Vector__XXX
 SG_ DetectionLocation2 : 16|4@1+ (1,0) [0|13] "count" Vector__XXX
 SG_ DetectionZone2 : 20|4@1+ (1,0) [0|13] "count" Vector__XXX
 SG_ ZoneAlarmStatus2 : 24|4@1+ (1,0) [0|15] "" Vector__XXX
 SG_ DetectionLocation3 : 32|4@1+ (1,0) [0|13] "count" Vector__XXX
 SG_ DetectionZone3 : 36|4@1+ (1,0) [0|13] "count" Vector__XXX
 SG_ ZoneAlarmStatus3 : 40|4@1+ (1,0) [0|15] "" Vector__XXX
 SG_ PersonnelDetectSequenceCounter : 48|8@1+ (1,0) [0|255] "count" Vector__XXX

BO_ 2566617086 ECPG1: 8 Vector__XXX
 SG_ EngnClndr1CmprssnGmmRt : 0|8@1+ (0.004,1) [1|2] "Ratio" Vector__XXX
 SG_ EngnClndr1ExpnsnGmmRt : 8|8@1+ (0.004,1) [1|2] "Ratio" Vector__XXX
 SG_ EngnClndr2CmprssnGmmRt : 16|8@1+ (0.004,1) [1|2] "Ratio" Vector__XXX
 SG_ EngnClndr2ExpnsnGmmRt : 24|8@1+ (0.004,1) [1|2] "Ratio" Vector__XXX
 SG_ EngnClndr3CmprssnGmmRt : 32|8@1+ (0.004,1) [1|2] "Ratio" Vector__XXX
 SG_ EngnClndr3ExpnsnGmmRt : 40|8@1+ (0.004,1) [1|2] "Ratio" Vector__XXX
 SG_ EngnClndr4CmprssnGmmRt : 48|8@1+ (0.004,1) [1|2] "Ratio" Vector__XXX
 SG_ EngnClndr4ExpnsnGmmRt : 56|8@1+ (0.004,1) [1|2] "Ratio" Vector__XXX

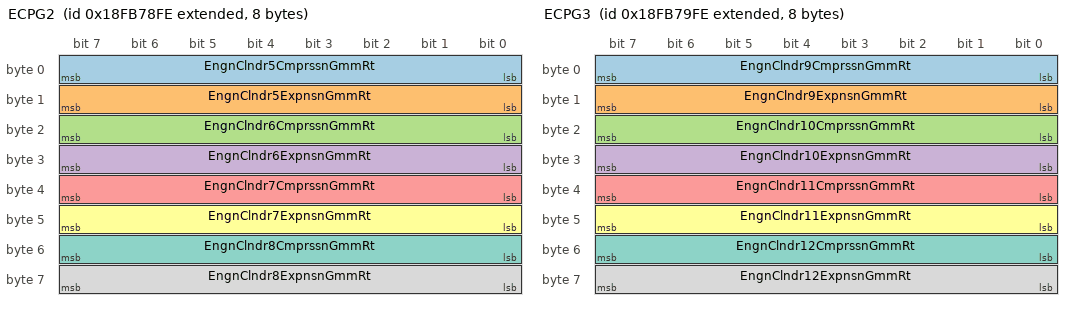
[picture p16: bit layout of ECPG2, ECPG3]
BO_ 2566617342 ECPG2: 8 Vector__XXX
 SG_ EngnClndr5CmprssnGmmRt : 0|8@1+ (0.004,1) [1|2] "Ratio" Vector__XXX
 SG_ EngnClndr5ExpnsnGmmRt : 8|8@1+ (0.004,1) [1|2] "Ratio" Vector__XXX
 SG_ EngnClndr6CmprssnGmmRt : 16|8@1+ (0.004,1) [1|2] "Ratio" Vector__XXX
 SG_ EngnClndr6ExpnsnGmmRt : 24|8@1+ (0.004,1) [1|2] "Ratio" Vector__XXX
 SG_ EngnClndr7CmprssnGmmRt : 32|8@1+ (0.004,1) [1|2] "Ratio" Vector__XXX
 SG_ EngnClndr7ExpnsnGmmRt : 40|8@1+ (0.004,1) [1|2] "Ratio" Vector__XXX
 SG_ EngnClndr8CmprssnGmmRt : 48|8@1+ (0.004,1) [1|2] "Ratio" Vector__XXX
 SG_ EngnClndr8ExpnsnGmmRt : 56|8@1+ (0.004,1) [1|2] "Ratio" Vector__XXX

BO_ 2566617598 ECPG3: 8 Vector__XXX
 SG_ EngnClndr9CmprssnGmmRt : 0|8@1+ (0.004,1) [1|2] "Ratio" Vector__XXX
 SG_ EngnClndr9ExpnsnGmmRt : 8|8@1+ (0.004,1) [1|2] "Ratio" Vector__XXX
 SG_ EngnClndr10CmprssnGmmRt : 16|8@1+ (0.004,1) [1|2] "Ratio" Vector__XXX
 SG_ EngnClndr10ExpnsnGmmRt : 24|8@1+ (0.004,1) [1|2] "Ratio" Vector__XXX
 SG_ EngnClndr11CmprssnGmmRt : 32|8@1+ (0.004,1) [1|2] "Ratio" Vector__XXX
 SG_ EngnClndr11ExpnsnGmmRt : 40|8@1+ (0.004,1) [1|2] "Ratio" Vector__XXX
 SG_ EngnClndr12CmprssnGmmRt : 48|8@1+ (0.004,1) [1|2] "Ratio" Vector__XXX
 SG_ EngnClndr12ExpnsnGmmRt : 56|8@1+ (0.004,1) [1|2] "Ratio" Vector__XXX

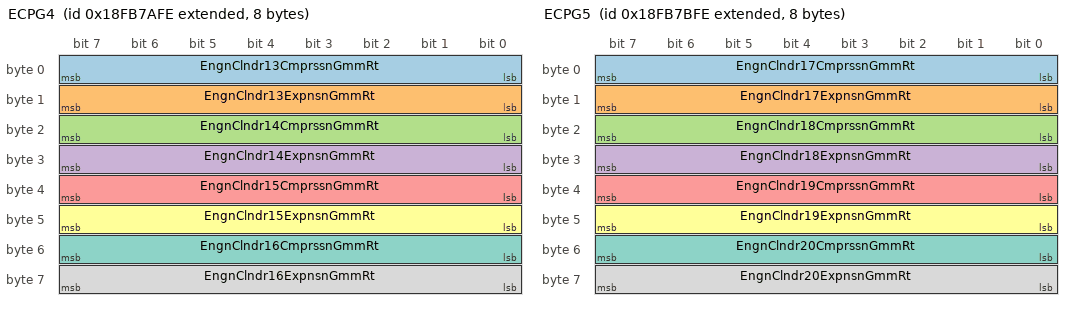
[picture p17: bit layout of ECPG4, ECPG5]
BO_ 2566617854 ECPG4: 8 Vector__XXX
 SG_ EngnClndr13CmprssnGmmRt : 0|8@1+ (0.004,1) [1|2] "Ratio" Vector__XXX
 SG_ EngnClndr13ExpnsnGmmRt : 8|8@1+ (0.004,1) [1|2] "Ratio" Vector__XXX
 SG_ EngnClndr14CmprssnGmmRt : 16|8@1+ (0.004,1) [1|2] "Ratio" Vector__XXX
 SG_ EngnClndr14ExpnsnGmmRt : 24|8@1+ (0.004,1) [1|2] "Ratio" Vector__XXX
 SG_ EngnClndr15CmprssnGmmRt : 32|8@1+ (0.004,1) [1|2] "Ratio" Vector__XXX
 SG_ EngnClndr15ExpnsnGmmRt : 40|8@1+ (0.004,1) [1|2] "Ratio" Vector__XXX
 SG_ EngnClndr16CmprssnGmmRt : 48|8@1+ (0.004,1) [1|2] "Ratio" Vector__XXX
 SG_ EngnClndr16ExpnsnGmmRt : 56|8@1+ (0.004,1) [1|2] "Ratio" Vector__XXX

BO_ 2566618110 ECPG5: 8 Vector__XXX
 SG_ EngnClndr17CmprssnGmmRt : 0|8@1+ (0.004,1) [1|2] "Ratio" Vector__XXX
 SG_ EngnClndr17ExpnsnGmmRt : 8|8@1+ (0.004,1) [1|2] "Ratio" Vector__XXX
 SG_ EngnClndr18CmprssnGmmRt : 16|8@1+ (0.004,1) [1|2] "Ratio" Vector__XXX
 SG_ EngnClndr18ExpnsnGmmRt : 24|8@1+ (0.004,1) [1|2] "Ratio" Vector__XXX
 SG_ EngnClndr19CmprssnGmmRt : 32|8@1+ (0.004,1) [1|2] "Ratio" Vector__XXX
 SG_ EngnClndr19ExpnsnGmmRt : 40|8@1+ (0.004,1) [1|2] "Ratio" Vector__XXX
 SG_ EngnClndr20CmprssnGmmRt : 48|8@1+ (0.004,1) [1|2] "Ratio" Vector__XXX
 SG_ EngnClndr20ExpnsnGmmRt : 56|8@1+ (0.004,1) [1|2] "Ratio" Vector__XXX

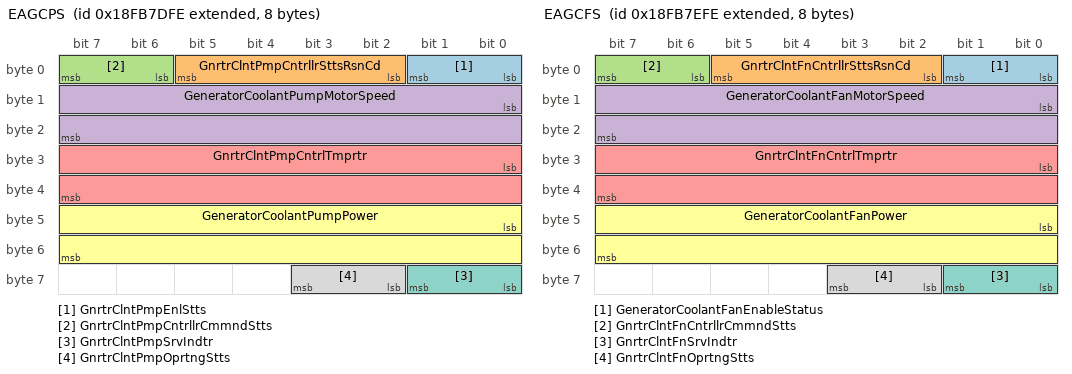
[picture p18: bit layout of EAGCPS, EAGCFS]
BO_ 2566618622 EAGCPS: 8 Vector__XXX
 SG_ GnrtrClntPmpEnlStts : 0|2@1+ (1,0) [0|3] "" Vector__XXX
 SG_ GnrtrClntPmpCntrllrSttsRsnCd : 2|4@1+ (1,0) [0|15] "" Vector__XXX
 SG_ GnrtrClntPmpCntrllrCmmndStts : 6|2@1+ (1,0) [0|3] "" Vector__XXX
 SG_ GeneratorCoolantPumpMotorSpeed : 8|16@1+ (0.5,0) [0|32127.5] "rpm" Vector__XXX
 SG_ GnrtrClntPmpCntrlTmprtr : 24|16@1+ (0.03125,-273) [-273|1734.96875] "degC" Vector__XXX
 SG_ GeneratorCoolantPumpPower : 40|16@1+ (0.5,0) [0|32127.5] "W" Vector__XXX
 SG_ GnrtrClntPmpSrvIndtr : 56|2@1+ (1,0) [0|3] "" Vector__XXX
 SG_ GnrtrClntPmpOprtngStts : 58|2@1+ (1,0) [0|3] "" Vector__XXX

BO_ 2566618878 EAGCFS: 8 Vector__XXX
 SG_ GeneratorCoolantFanEnableStatus : 0|2@1+ (1,0) [0|3] "" Vector__XXX
 SG_ GnrtrClntFnCntrllrSttsRsnCd : 2|4@1+ (1,0) [0|15] "" Vector__XXX
 SG_ GnrtrClntFnCntrllrCmmndStts : 6|2@1+ (1,0) [0|3] "" Vector__XXX
 SG_ GeneratorCoolantFanMotorSpeed : 8|16@1+ (0.5,0) [0|32127.5] "rpm" Vector__XXX
 SG_ GnrtrClntFnCntrlTmprtr : 24|16@1+ (0.03125,-273) [-273|1734.96875] "degC" Vector__XXX
 SG_ GeneratorCoolantFanPower : 40|16@1+ (0.5,0) [0|32127.5] "W" Vector__XXX
 SG_ GnrtrClntFnSrvIndtr : 56|2@1+ (1,0) [0|3] "" Vector__XXX
 SG_ GnrtrClntFnOprtngStts : 58|2@1+ (1,0) [0|3] "" Vector__XXX

BO_ 2566619134 WSPF: 8 Vector__XXX
 SG_ WllStmltnPmpOlFltrDffrntlPrssr : 0|8@1+ (4,0) [0|1000] "kPa" Vector__XXX
 SG_ WllStmltnPmpOlFltrOtltPrssr : 8|16@1+ (0.1,0) [0|6425.5] "kPa" Vector__XXX
 SG_ WllStmltnPmpOlFltrBpssSwthStts : 24|2@1+ (1,0) [0|3] "" Vector__XXX

BO_ 2566619390 PTOGC: 22 Vector__XXX
 SG_ PrprgrmmdPTOGvrnrStSpd1 : 0|16@1+ (0.125,0) [0|8031.875] "rpm" Vector__XXX
 SG_ PrprgrmmdPTOGvrnrStSpd2 : 16|16@1+ (0.125,0) [0|8031.875] "rpm" Vector__XXX
 SG_ PrprgrmmdPTOGvrnrStSpd3 : 32|16@1+ (0.125,0) [0|8031.875] "rpm" Vector__XXX
 SG_ PrprgrmmdPTOGvrnrStSpd4 : 48|16@1+ (0.125,0) [0|8031.875] "rpm" Vector__XXX
 SG_ PrprgrmmdPTOGvrnrStSpd5 : 64|16@1+ (0.125,0) [0|8031.875] "rpm" Vector__XXX
 SG_ PrprgrmmdPTOGvrnrStSpd6 : 80|16@1+ (0.125,0) [0|8031.875] "rpm" Vector__XXX
 SG_ PrprgrmmdPTOGvrnrStSpd7 : 96|16@1+ (0.125,0) [0|8031.875] "rpm" Vector__XXX
 SG_ PrprgrmmdPTOGvrnrStSpd8 : 112|16@1+ (0.125,0) [0|8031.875] "rpm" Vector__XXX
 SG_ MinimumPTOGovernorSetSpeed : 128|16@1+ (0.125,0) [0|8031.875] "rpm" Vector__XXX
 SG_ MaximumPTOGovernorSetSpeed : 144|16@1+ (0.125,0) [0|8031.875] "rpm" Vector__XXX
 SG_ PTOGvrnrAlrtrOvrrdMxmmSpd : 160|16@1+ (0.125,0) [0|8031.875] "rpm" Vector__XXX

BO_ 2566619646 OBP2: 8 Vector__XXX
 SG_ OnBrdPrgrmmngInttECUAddrss : 0|8@1+ (1,0) [0|255] "SA" Vector__XXX
 SG_ OnBrdPrgrmmngInttRqst : 8|2@1+ (1,0) [0|3] "" Vector__XXX
 SG_ OnBrdPrgrmmngInttInht : 10|2@1+ (1,0) [0|3] "" Vector__XXX

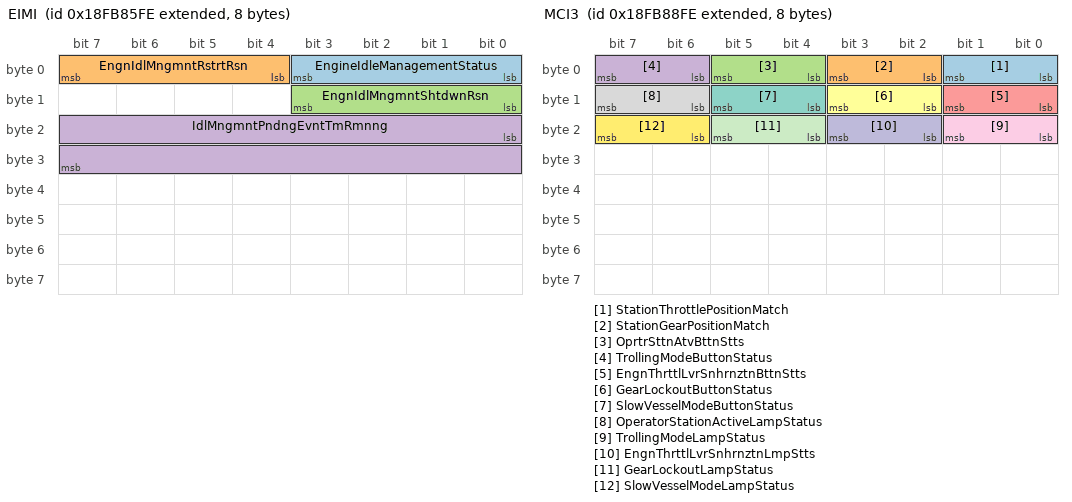
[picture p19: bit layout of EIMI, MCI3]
BO_ 2566620670 EIMI: 8 Vector__XXX
 SG_ EngineIdleManagementStatus : 0|4@1+ (1,0) [0|15] "" Vector__XXX
 SG_ EngnIdlMngmntRstrtRsn : 4|4@1+ (1,0) [0|15] "" Vector__XXX
 SG_ EngnIdlMngmntShtdwnRsn : 8|4@1+ (1,0) [0|15] "" Vector__XXX
 SG_ IdlMngmntPndngEvntTmRmnng : 16|16@1+ (1,0) [0|64255] "s" Vector__XXX

BO_ 2566621438 MCI3: 8 Vector__XXX
 SG_ StationThrottlePositionMatch : 0|2@1+ (1,0) [0|3] "" Vector__XXX
 SG_ StationGearPositionMatch : 2|2@1+ (1,0) [0|3] "" Vector__XXX
 SG_ OprtrSttnAtvBttnStts : 4|2@1+ (1,0) [0|3] "" Vector__XXX
 SG_ TrollingModeButtonStatus : 6|2@1+ (1,0) [0|3] "" Vector__XXX
 SG_ EngnThrttlLvrSnhrnztnBttnStts : 8|2@1+ (1,0) [0|3] "" Vector__XXX
 SG_ GearLockoutButtonStatus : 10|2@1+ (1,0) [0|3] "" Vector__XXX
 SG_ SlowVesselModeButtonStatus : 12|2@1+ (1,0) [0|3] "" Vector__XXX
 SG_ OperatorStationActiveLampStatus : 14|2@1+ (1,0) [0|3] "" Vector__XXX
 SG_ TrollingModeLampStatus : 16|2@1+ (1,0) [0|3] "" Vector__XXX
 SG_ EngnThrttlLvrSnhrnztnLmpStts : 18|2@1+ (1,0) [0|3] "" Vector__XXX
 SG_ GearLockoutLampStatus : 20|2@1+ (1,0) [0|3] "" Vector__XXX
 SG_ SlowVesselModeLampStatus : 22|2@1+ (1,0) [0|3] "" Vector__XXX

BO_ 2566621694 EFLP13: 8 Vector__XXX
 SG_ EngineOilPressure2 : 0|8@1+ (4,0) [0|1000] "kPa" Vector__XXX

BO_ 2365295358 HVES1D11: 8 Vector__XXX
 SG_ HVES1BsVltgNgtvtChsssGrndVltg : 0|16@1+ (0.05,0) [0|3212.75] "V" Vector__XXX
 SG_ HVES1VltgLvlNgtvtChsssGrndVltg : 16|16@1+ (0.05,0) [0|3212.75] "V" Vector__XXX

BO_ 2566622206 EMIH: 8 Vector__XXX
 SG_ EconomyModeTotalHoursInactive : 0|32@1+ (0.05,0) [0|210554060.75] "h" Vector__XXX
 SG_ EconomyModeTripHoursInactive : 32|32@1+ (0.05,0) [0|210554060.75] "h" Vector__XXX

BO_ 2566622462 EMEIFSR: 8 Vector__XXX
 SG_ EnmMdEstmtdInstntnsFlSvngsRt : 0|16@1+ (0.05,0) [0|3212.75] "l/h" Vector__XXX
 SG_ EMdEsttdIsttsFSvsRtPt : 16|16@1+ (0.0025,0) [0|160.6375] "%" Vector__XXX

BO_ 2566622718 EMAH: 8 Vector__XXX
 SG_ EconomyModeTotalHoursActive : 0|32@1+ (0.05,0) [0|210554060.75] "h" Vector__XXX
 SG_ EconomyModeTripHoursActive : 32|32@1+ (0.05,0) [0|210554060.75] "h" Vector__XXX

BO_ 2566622974 EMFU: 8 Vector__XXX
 SG_ EconomyModeTotalFuelUsed : 0|32@1+ (0.5,0) [0|2105540607.5] "l" Vector__XXX
 SG_ EconomyModeTripFuelUsed : 32|32@1+ (0.5,0) [0|2105540607.5] "l" Vector__XXX

BO_ 2566623230 EMEFS: 8 Vector__XXX
 SG_ EnmMdTtlEstmtdFlSvd : 0|32@1+ (0.5,0) [0|2105540607.5] "l" Vector__XXX
 SG_ EnmMdTrpEstmtdFlSvd : 32|32@1+ (0.5,0) [0|2105540607.5] "l" Vector__XXX

CM_ BO_ 2556493566 "Motor/Generator 1 Inverter Limits Request Power";
CM_ SG_ 2556493566 MtrGnrtr1InvrtrLmtsRqstPwrCRC "The CRC is defined as follows: • Length: 8 bits • Polynomial: x^8+x^5+x^3+x^2+x+1 • Initial Value: FFh • Input Data Reflection: Not reflected • Result Data Refl…";
CM_ SG_ 2556493566 MtrGnrtr1InvrtrLmtsRqstPwrCntr "The message counter is used to detect situations where the transmitting ECU malfunction repeats the same frame all the time. The receiver of the information may…";
CM_ BO_ 2556559102 "Personnel Detect Interlock";
CM_ SG_ 2556559102 PrsnnlDttAlrmRvStts "Indicates status of receiving the personnel detect alarm status information.000b = Alarm Status Data Not Received001b = Alarm Status Data Received010b = Reserve…";
CM_ SG_ 2556559102 PrsnnlDttSqnCntrEh "Indicates the sequence counter value of the Personnel Detect Status message or group acknowledged.…";
CM_ BO_ 2556624638 "Engine Cylinder Combustion Configuration Feedback";
CM_ SG_ 2556624638 CnfgrdEngnClndrMssFrtnBrndLtn1 "Configured value in use for x% mass fraction burned when reporting Engine Cylinder Instantaneous Combustion Timing, Location 1 in ECCT1-20.…";
CM_ SG_ 2556624638 CnfgrdEngnClndrMssFrtnBrndLtn2 "Configured value in use for y% mass fraction burned when reporting Engine Cylinder Instantaneous Combustion Timing, Location 2 in ECCT1-20.…";
CM_ BO_ 2556690174 "Engine Cylinder Combustion Configuration";
CM_ SG_ 2556690174 EngnClndrMssFrtnBrndLtn1 "Commanded value to use for x% mass fraction burned when reporting Engine Cylinder Instantaneous Combustion Timing, Location 1 in ECCT1-20.…";
CM_ SG_ 2556690174 EngnClndrMssFrtnBrndLtn2 "Commanded value to use for y% mass fraction burned when reporting Engine Cylinder Instantaneous Combustion Timing, Location 2 in ECCT1-20.…";
CM_ BO_ 2556755710 "Engine Cylinder Pressure Timing Feedback";
CM_ SG_ 2556755710 CnfgrdEngnClndrPrssrTmng1 "Configured timing location #1 for combustion pressure reporting in ECCP1-20.  When the combustion happens after the TDC (Top Dead Center) of this cylinder, the …";
CM_ SG_ 2556755710 CnfgrdEngnClndrPrssrTmng2 "Configured timing location #2 for combustion pressure reporting in ECCP1-20.  When the combustion happens after the TDC (Top Dead Center) of this cylinder, the …";
CM_ SG_ 2556755710 CnfgrdEngnClndrPrssrTmng3 "Configured timing location #3 for combustion pressure reporting in ECCP1-20. When the combustion happens after the TDC (Top Dead Center) of this cylinder, the t…";
CM_ SG_ 2556755710 CnfgrdEngnClndrPrssrTmng4 "Configured timing location #4 for combustion pressure reporting in ECCP1-20.  When the combustion happens after the TDC (Top Dead Center) of this cylinder, the …";
CM_ BO_ 2556821246 "Engine Cylinder Pressure Timing Configuration";
CM_ SG_ 2556821246 EngineCylinderPressureTiming1 "Commanded timing location #1 for in-cylinder pressure reports in ECCP1-20.  When the combustion happens after the TDC (Top Dead Center) of this cylinder, the ti…";
CM_ SG_ 2556821246 EngineCylinderPressureTiming2 "Commanded timing location #2 for in-cylinder pressure reports in ECCP1-20. When the combustion happens after the TDC (Top Dead Center) of this cylinder, the tim…";
CM_ SG_ 2556821246 EngineCylinderPressureTiming3 "Commanded timing location #3 for in-cylinder pressure reports in ECCP1-20. When the combustion happens after the TDC (Top Dead Center) of this cylinder, the tim…";
CM_ SG_ 2556821246 EngineCylinderPressureTiming4 "Commanded timing location #4 for in-cylinder pressure reports in ECCP1-20. When the combustion happens after the TDC (Top Dead Center) of this cylinder, the tim…";
CM_ BO_ 2556886782 "Electrified Accessory Generator Coolant Pump Command ";
CM_ SG_ 2556886782 GnrtrClntPmpEnlCmmnd "Enable and direction command to the Generator Coolant Pump.00b = Accessory Motor Off01b = Accessory Motor On Normal/Default Direction10b = Accessory Motor On Re…";
CM_ SG_ 2556886782 GeneratorCoolantPumpPowerHold "Command to allow the Generator Coolant Pump to remain alive independently of the electrical enable input to the Accessory Motor.  For example, this could allow …";
CM_ SG_ 2556886782 GnrtrClntPmpSpdCmmnd "Speed command to the Generator Coolant Pump.Note: Both Speed Command and Percent Speed Command cannot be used at the same time.  Always set the unused speed com…";
CM_ SG_ 2556886782 GnrtrClntPmpPrntSpdCmmnd "Speed command to the Generator Coolant Pump in percentage of maximum speed.Note: Both Speed Command and Percent Speed Command cannot be used at the same time.  …";
CM_ BO_ 2556952318 "Electrified Accessory Generator Coolant Fan Command ";
CM_ SG_ 2556952318 GnrtrClntFnEnlCmmnd "Enable and direction command to the Generator Coolant Fan.00b = Accessory Motor Off01b = Accessory Motor On Normal/Default Direction10b = Accessory Motor On Rev…";
CM_ SG_ 2556952318 GeneratorCoolantFanPowerHold "Command to allow the Generator Coolant Fan to remain alive independently of the electrical enable input to the Accessory Motor.  For example, this could allow c…";
CM_ SG_ 2556952318 GeneratorCoolantFanSpeedCommand "Speed command to the Generator Coolant Fan.Note: Both Speed Command and Percent Speed Command cannot be used at the same time.  Always set the unused speed comm…";
CM_ SG_ 2556952318 GnrtrClntFnPrntSpdCmmnd "Speed command to the Generator Coolant Fan in percentage of maximum speed.Note: Both Speed Command and Percent Speed Command cannot be used at the same time.  A…";
CM_ BO_ 2557017854 "On Board Programming 1";
CM_ SG_ 2557017854 OnBrdPrgrmmngTrgtECUAddrss "Source address of target device to be programmed, for which the message parameters apply.When SPN 9767 (On Board Programming Status) parameter indicates no upda…";
CM_ SG_ 2557017854 OnBoardProgrammingStatus "Status of a software update.0000b = Software Up to Date: no new software is available0001b = Available for Installation: updated software is available0010b = In…";
CM_ SG_ 2557017854 OBPInterlockOverallStatus "Indicates whether all interlocks for on board programming (OBP) have been satisfied. This parameter should be set to On whever any of the other OBP Interlocks a…";
CM_ SG_ 2557017854 OBPInterlockEngineSpeed "Engine speed requirement is not met to allow initiation of on board programming (OBP).00b = Off: Engine speed is permitting on board programming01b = On: On boa…";
CM_ SG_ 2557017854 OBPInterlockKeySwitchPosition "Key switch position requirement is not met to allow initiation of on board programming (OBP).00b = Off: Key switch position is permitting on board programming01…";
CM_ SG_ 2557017854 OBPInterlockParkBrake "Park brake requirement is not met to allow initiation of on board programming (OBP).00b = Off: Park brake is permitting on board programming01b = On: On board p…";
CM_ SG_ 2557017854 OBPIntrlkPwrSpplInsffnt "Power supply (e.g. SLI battery state of charge) is not sufficient to allow initiation of on board programming (OBP).00b = Off: Power supply is sufficient to per…";
CM_ SG_ 2557017854 OBPInterlockTargetNotReady "Indicates whether the target is not ready to accept on board programming (OBP).00b = Off: Target is not inhibiting on board programming01b = On: Target has indi…";
CM_ SG_ 2557017854 OBPKeySwitchRequest "Request to turn the key switch to the ignition or run position and/or prevent the ignition bus from turning off during on board programming (OBP).00b = On board…";
CM_ SG_ 2557017854 OnBoardProgrammingProgress "Amount of programming progress completed in relation to the total expected duration of the programming event.…";
CM_ BO_ 2557083390 "Marine Control Information Configuration 1";
CM_ SG_ 2557083390 OperatorStationLocationSetting "Configurable location of the selected operator station.00h = Bridge01h = Port Wing02h = Starboard Wing03h = Tower04h = Engine Room05h = Aft. Station06h = Fly Br…";
CM_ SG_ 2557083390 TrollingModeSettingCommand "The commanded setting of the Trolling Mode.  In traditional trolling mode, engine speed remains constant while the throttle lever changes the amount of slip wit…";
CM_ SG_ 2557083390 EngnThrttlSnhrnztnMdCmmnd "The setting of the throttle synchronization mode. Throttle synchronization mode is used to indicate which throttle, if any, is used to be used for the synchroni…";
CM_ SG_ 2557083390 EngineTrollingModeSetSpeed "The (chosen) vessel trolling speed that has been selected by the operator…";
CM_ BO_ 2557148926 "Marine Control Information 2";
CM_ SG_ 2557148926 OprtrSttnInCntrlLtn "Identifies the location of the operator station that is currently in control of the system.00h = Bridge01h = Port Wing02h = Starboard Wing03h = Tower04h = Engin…";
CM_ SG_ 2557148926 OperatorStationLockout "Indicates the status of a lockout to prevent changing the active control station. Lockout active indicates a change is not permitted to the active control stati…";
CM_ SG_ 2557148926 EngnThrttlSnhrnztnMdCrrntSttng "The current setting of the engine throttle synchronization mode. Throttle synchronization mode indicates which throttle, if any, is to be used for the synchroni…";
CM_ SG_ 2557148926 TrollingModeExtendedRange "The active status of the Trolling Mode (Extended Range). In traditional trolling mode, engine speed remains constant while the throttle lever changes the amount…";
CM_ SG_ 2557148926 TrollingModeCurrentSetting "The current setting of the Trolling Mode.  In traditional trolling mode, engine speed remains constant while the throttle lever changes the amount of slip withi…";
CM_ SG_ 2557148926 VesselEngineSetSpeed "The (chosen) vessel speed that has been selected by the operator.…";
CM_ SG_ 2557148926 VesselSpeedControlMode "The vessel set speed type that is selected by the operator.00h = No Set Speed01h = Slow Vessel Mode02h = Synchronization Mode03h = Trolling Mode04h to FDh = Res…";
CM_ BO_ 2364617726 "Engine Pre-Chamber Fuel Valve Duration Command 1";
CM_ SG_ 2364617726 EngnPrChmrFlVlv1Drtn "Amount of time the pre-chamber fuel valve 1 is activated.…";
CM_ SG_ 2364617726 EngnPrChmrFlVlv2Drtn "Amount of time the pre-chamber fuel valve 2 is activated.…";
CM_ SG_ 2364617726 EngnPrChmrFlVlv3Drtn "Amount of time the pre-chamber fuel valve 3 is activated.…";
CM_ SG_ 2364617726 EngnPrChmrFlVlv4Drtn "Amount of time the pre-chamber fuel valve 4 is activated.…";
CM_ BO_ 2364617982 "Engine Pre-Chamber Fuel Valve Duration Command 2";
CM_ SG_ 2364617982 EngnPrChmrFlVlv5Drtn "Amount of time the pre-chamber fuel valve 5 is activated.…";
CM_ SG_ 2364617982 EngnPrChmrFlVlv6Drtn "Amount of time the pre-chamber fuel valve 6 is activated.…";
CM_ SG_ 2364617982 EngnPrChmrFlVlv7Drtn "Amount of time the pre-chamber fuel valve 7 is activated.…";
CM_ SG_ 2364617982 EngnPrChmrFlVlv8Drtn "Amount of time the pre-chamber fuel valve 8 is activated.…";
CM_ BO_ 2364618238 "Engine Pre-Chamber Fuel Valve Duration Command 3";
CM_ SG_ 2364618238 EngnPrChmrFlVlv9Drtn "Amount of time the pre-chamber fuel valve 9 is activated.…";
CM_ SG_ 2364618238 EngnPrChmrFlVlv10Drtn "Amount of time the pre-chamber fuel valve 10 is activated.…";
CM_ SG_ 2364618238 EngnPrChmrFlVlv11Drtn "Amount of time the pre-chamber fuel valve 11 is activated.…";
CM_ SG_ 2364618238 EngnPrChmrFlVlv12Drtn "Amount of time the pre-chamber fuel valve 12 is activated.…";
CM_ BO_ 2364618494 "Engine Pre-Chamber Fuel Valve Duration Command 4";
CM_ SG_ 2364618494 EngnPrChmrFlVlv13Drtn "Amount of time the pre-chamber fuel valve 13 is activated.…";
CM_ SG_ 2364618494 EngnPrChmrFlVlv14Drtn "Amount of time the pre-chamber fuel valve 14 is activated.…";
CM_ SG_ 2364618494 EngnPrChmrFlVlv15Drtn "Amount of time the pre-chamber fuel valve 15 is activated.…";
CM_ SG_ 2364618494 EngnPrChmrFlVlv16Drtn "Amount of time the pre-chamber fuel valve 16 is activated.…";
CM_ BO_ 2364618750 "Engine Pre-Chamber Fuel Valve Duration Command 5";
CM_ SG_ 2364618750 EngnPrChmrFlVlv17Drtn "Amount of time the pre-chamber fuel valve 17 is activated.…";
CM_ SG_ 2364618750 EngnPrChmrFlVlv18Drtn "Amount of time the pre-chamber fuel valve 18 is activated.…";
CM_ SG_ 2364618750 EngnPrChmrFlVlv19Drtn "Amount of time the pre-chamber fuel valve 19 is activated.…";
CM_ SG_ 2364618750 EngnPrChmrFlVlv20Drtn "Amount of time the pre-chamber fuel valve 20 is activated.…";
CM_ BO_ 2364619006 "Engine Pre-Chamber Fuel Valve Start of Actuation Command 1";
CM_ SG_ 2364619006 EngnPrChmrFlVlv1StrtfAttnCmmnd "The angle, relative to the TDC of cylinder 1 with 0 being the TDC before the power stroke commences, at the which pre-chamber fuel valve 1 is activated to open.…";
CM_ SG_ 2364619006 EngnPrChmrFlVlv2StrtfAttnCmmnd "The angle, relative to the TDC of cylinder 2 with 0 being the TDC before the power stroke commences, at the which pre-chamber fuel valve 2 is activated to open.…";
CM_ SG_ 2364619006 EngnPrChmrFlVlv3StrtfAttnCmmnd "The angle, relative to the TDC of cylinder 3 with 0 being the TDC before the power stroke commences, at the which pre-chamber fuel valve 3 is activated to open.…";
CM_ SG_ 2364619006 EngnPrChmrFlVlv4StrtfAttnCmmnd "The angle, relative to the TDC of cylinder 4 with 0 being the TDC before the power stroke commences, at the which pre-chamber fuel valve 4 is activated to open.…";
CM_ BO_ 2364619262 "Engine Pre-Chamber Fuel Valve Start of Actuation Command 2";
CM_ SG_ 2364619262 EngnPrChmrFlVlv5StrtfAttnCmmnd "The angle, relative to the TDC of cylinder 5 with 0 being the TDC before the power stroke commences, at the which pre-chamber fuel valve 5 is activated to open.…";
CM_ SG_ 2364619262 EngnPrChmrFlVlv6StrtfAttnCmmnd "The angle, relative to the TDC of cylinder 6 with 0 being the TDC before the power stroke commences, at the which pre-chamber fuel valve 6 is activated to open.…";
CM_ SG_ 2364619262 EngnPrChmrFlVlv7StrtfAttnCmmnd "The angle, relative to the TDC of cylinder 7 with 0 being the TDC before the power stroke commences, at the which pre-chamber fuel valve 7 is activated to open.…";
CM_ SG_ 2364619262 EngnPrChmrFlVlv8StrtfAttnCmmnd "The angle, relative to the TDC of cylinder 8 with 0 being the TDC before the power stroke commences, at the which pre-chamber fuel valve 8 is activated to open.…";
CM_ BO_ 2364619518 "Engine Pre-Chamber Fuel Valve Start of Actuation Command 3";
CM_ SG_ 2364619518 EngnPrChmrFlVlv9StrtfAttnCmmnd "The angle, relative to the TDC of cylinder 9 with 0 being the TDC before the power stroke commences, at the which pre-chamber fuel valve 9 is activated to open.…";
CM_ SG_ 2364619518 EngnPrChmrFlVlv10StrtfAttnCmmnd "The angle, relative to the TDC of cylinder 10 with 0 being the TDC before the power stroke commences, at the which pre-chamber fuel valve 10 is activated to ope…";
CM_ SG_ 2364619518 EngnPrChmrFlVlv11StrtfAttnCmmnd "The angle, relative to the TDC of cylinder 11 with 0 being the TDC before the power stroke commences, at the which pre-chamber fuel valve 11 is activated to ope…";
CM_ SG_ 2364619518 EngnPrChmrFlVlv12StrtfAttnCmmnd "The angle, relative to the TDC of cylinder 12 with 0 being the TDC before the power stroke commences, at the which pre-chamber fuel valve 12 is activated to ope…";
CM_ BO_ 2364619774 "Engine Pre-Chamber Fuel Valve Start of Actuation Command 4";
CM_ SG_ 2364619774 EngnPrChmrFlVlv13StrtfAttnCmmnd "The angle, relative to the TDC of cylinder 13 with 0 being the TDC before the power stroke commences, at the which pre-chamber fuel valve 13 is activated to ope…";
CM_ SG_ 2364619774 EngnPrChmrFlVlv14StrtfAttnCmmnd "The angle, relative to the TDC of cylinder 14 with 0 being the TDC before the power stroke commences, at the which pre-chamber fuel valve 14 is activated to ope…";
CM_ SG_ 2364619774 EngnPrChmrFlVlv15StrtfAttnCmmnd "The angle, relative to the TDC of cylinder 15 with 0 being the TDC before the power stroke commences, at the which pre-chamber fuel valve 15 is activated to ope…";
CM_ SG_ 2364619774 EngnPrChmrFlVlv16StrtfAttnCmmnd "The angle, relative to the TDC of cylinder 16 with 0 being the TDC before the power stroke commences, at the which pre-chamber fuel valve 16 is activated to ope…";
CM_ BO_ 2364620030 "Engine Pre-Chamber Fuel Valve Start of Actuation Command 5";
CM_ SG_ 2364620030 EngnPrChmrFlVlv17StrtfAttnCmmnd "The angle, relative to the TDC of cylinder 17 with 0 being the TDC before the power stroke commences, at the which pre-chamber fuel valve 17 is activated to ope…";
CM_ SG_ 2364620030 EngnPrChmrFlVlv18StrtfAttnCmmnd "The angle, relative to the TDC of cylinder 18 with 0 being the TDC before the power stroke commences, at the which pre-chamber fuel valve 18 is activated to ope…";
CM_ SG_ 2364620030 EngnPrChmrFlVlv19StrtfAttnCmmnd "The angle, relative to the TDC of cylinder 19 with 0 being the TDC before the power stroke commences, at the which pre-chamber fuel valve 19 is activated to ope…";
CM_ SG_ 2364620030 EngnPrChmrFlVlv20StrtfAttnCmmnd "The angle, relative to the TDC of cylinder 20 with 0 being the TDC before the power stroke commences, at the which pre-chamber fuel valve 20 is activated to ope…";
CM_ BO_ 2364620286 "Active Steering System Controls 1";
CM_ SG_ 2364620286 LnKpngAssstSttsRghtSd "Indicates the current status of lane keeping assist feature for right side lane marker.000b = Lane Keeping Assist Not Available for Right Side001b = Lane Keepin…";
CM_ SG_ 2364620286 LaneKeepingAssistStatusLeftSide "Indicates the current status of lane keeping assist feature for left side lane marker.000b = Lane Keeping Assist Not Available for Left Side001b = Lane Keeping …";
CM_ SG_ 2364620286 LnKpngAssstIndtnEnlStts "Indicates whether lane keeping assist is enabled.00b = Lane Keeping Assist disabled01b = Lane Keeping Assist enabled10b = Error11b = Not available…";
CM_ SG_ 2364620286 LaneKeepingAssistSystemState "Indicates the current state of the Lane Keep Assist feature.0000b = System is not ready (initialization not finished)0001b = System is temporarily not available…";
CM_ SG_ 2364620286 ActiveSteeringDriverPreference "Indicates the current preference for active steering mode selected by the driver.000b = Active Steering Mode #1001b = Active Steering Mode #2010b = Active Steer…";
CM_ SG_ 2364620286 LnCntrngIndtnEnlStt "Indicates whether lane centering indication is enabled.00b = Lane Centering Indication disabled01b = Lane Centering Indication enabled10b = Error11b = Not avail…";
CM_ SG_ 2364620286 LaneCenteringSystemStatus "Indicates the current state of the Lane Centering feature.0000b = System is not ready (initialization not finished)0001b = System is temporarily not available (…";
CM_ BO_ 2364621054 "Stationary Inverter Average Basic AC Quantities";
CM_ SG_ 2364621054 SttnrInvrtrAvrgACRMSVltg "Average Line to Line AC RMS voltage measured at the inverter output.For stationary non-vehicular applications of inverters.…";
CM_ SG_ 2364621054 SttnrInvrtrAvrgLnNtrlACRMSVltg "Average Line to Neutral AC RMS voltage measured at the inverter output.For stationary non-vehicular applications of inverters.…";
CM_ SG_ 2364621054 SttnrInvrtrAvrgACFrqn "Average AC frequency measured at the inverter output.For stationary non-vehicular applications of inverters.…";
CM_ SG_ 2364621054 SttnrInvrtrAvrgACRMSCrrnt "Average AC RMS current measured at the inverter output.For stationary non-vehicular applications of inverters.…";
CM_ BO_ 2364621310 "Stationary Inverter Total AC Reactive Power";
CM_ SG_ 2364621310 SttnrInvrtrTtlRtvPwr "The total reactive power delivered by the inverter.For stationary non-vehicular applications of inverters.…";
CM_ SG_ 2364621310 SttnrInvrtrOvrllPwrFtr "The average power factor of the inverter.For stationary non-vehicular applications of inverters.…";
CM_ SG_ 2364621310 SttnrInvrtrOvrllPwrFtrLggng "Lead/lag status for inverter average power factor.For stationary non-vehicular applications of inverters.00b = Leading01b = Lagging10b = Error11b = Not Availabl…";
CM_ BO_ 2364621566 "Stationary Inverter Total AC Power";
CM_ SG_ 2364621566 SttnrInvrtrTtlRlPwr "Total real power delivered by the inverter.For stationary non-vehicular applications of inverters.…";
CM_ SG_ 2364621566 SttnrInvrtrTtlApprntPwr "The total apparent power delivered by the inverter.For stationary non-vehicular applications of inverters.…";
CM_ BO_ 2364621822 "Stationary Inverter Control";
CM_ SG_ 2364621822 SttnrInvrtrNtRdtAtmtllPrlllStt "This parameter indicates whether or not all systems required to operate the inverter and close to the bus are prepared to operate automatically. If systems are …";
CM_ SG_ 2364621822 SttnrInvrtrAxlrShtdwnSwth "Switch signal which requests that all inverter functions stop.For stationary non-vehicular applications of inverters.00b = Off01b = On10b = Error11b = Not avail…";
CM_ BO_ 2364622078 "Stationary Inverter to Bus Sync Check Status";
CM_ SG_ 2364622078 StationaryInvertertoBusDeadBus "Indicator of whether the bus is considered dead for closing to the stationary inverter. This indicator will be based on parameters such as bus voltage and dead …";
CM_ SG_ 2364622078 SttnrInvrtrtBsPhsMth "Indicator of whether phase difference between the stationary inverter and the bus is adequate for paralleling.For stationary non-vehicular applications of inver…";
CM_ SG_ 2364622078 SttnrInvrtrtBsFrqnMth "Indicator of whether the frequency difference between the stationary inverter and the bus is adequate for paralleling.For stationary non-vehicular applications …";
CM_ SG_ 2364622078 SttnrInvrtrtBsVltgMth "Indicator of whether the voltage difference the stationary inverter and the bus is adequate for paralleling.For stationary non-vehicular applications of inverte…";
CM_ SG_ 2364622078 StationaryInvertertoBusInSync "Indicator of whether the stationary inverter and the bus are properly synchronized for paralleling.  This indicator will be based on parameters such as Voltage …";
CM_ SG_ 2364622078 SttnrInvrtrtBsACPhsDffrn "The phase difference between the stationary inverter and the bus voltage.  For stationary non-vehicular applications of inverters.…";
CM_ BO_ 2364622334 "Engine Cylinder 1 Combustion Pressures";
CM_ SG_ 2364622334 EngineCylinder1Timing1Pressure "In-cylinder pressure for Cylinder #1 at user-defined timing location #1 as per SPN 9845.  Will report FB00h (64256) when engine is not running.…";
CM_ SG_ 2364622334 EngineCylinder1Timing2Pressure "In-cylinder pressure for Cylinder #1 at user-defined timing location #2 as per SPN 9846.  Will report FB00h (64256) when engine is not running.…";
CM_ SG_ 2364622334 EngineCylinder1Timing3Pressure "In-cylinder pressure for Cylinder #1 at user-defined timing location #3 as per SPN 9847.  Will report FB00h (64256) when engine is not running.…";
CM_ SG_ 2364622334 EngineCylinder1Timing4Pressure "In-cylinder pressure for Cylinder #1 at user-defined timing location #4 as per SPN 9848.  Will report FB00h (64256) when engine is not running.…";
CM_ BO_ 2364622590 "Engine Cylinder 2 Combustion Pressures";
CM_ SG_ 2364622590 EngineCylinder2Timing1Pressure "In-cylinder pressure for Cylinder #2 at user-defined timing location #1 as per SPN 9845.  Will report FB00h (64256) when engine is not running.…";
CM_ SG_ 2364622590 EngineCylinder2Timing2Pressure "In-cylinder pressure for Cylinder #2 at user-defined timing location #2 as per SPN 9846.  Will report FB00h (64256) when engine is not running.…";
CM_ SG_ 2364622590 EngineCylinder2Timing3Pressure "In-cylinder pressure for Cylinder #2 at user-defined timing location #3 as per SPN 9847.  Will report FB00h (64256) when engine is not running.…";
CM_ SG_ 2364622590 EngineCylinder2Timing4Pressure "In-cylinder pressure for Cylinder #2 at user-defined timing location #4 as per SPN 9848.  Will report FB00h (64256) when engine is not running.…";
CM_ BO_ 2364622846 "Engine Cylinder 3 Combustion Pressures";
CM_ SG_ 2364622846 EngineCylinder3Timing1Pressure "In-cylinder pressure for Cylinder #3 at user-defined timing location #1 as per SPN 9845.  Will report FB00h (64256) when engine is not running.…";
CM_ SG_ 2364622846 EngineCylinder3Timing2Pressure "In-cylinder pressure for Cylinder #3 at user-defined timing location #2 as per SPN 9846.  Will report FB00h (64256) when engine is not running.…";
CM_ SG_ 2364622846 EngineCylinder3Timing3Pressure "In-cylinder pressure for Cylinder #3 at user-defined timing location #3 as per SPN 9847.  Will report FB00h (64256) when engine is not running.…";
CM_ SG_ 2364622846 EngineCylinder3Timing4Pressure "In-cylinder pressure for Cylinder #3 at user-defined timing location #4 as per SPN 9848.  Will report FB00h (64256) when engine is not running.…";
CM_ BO_ 2364623102 "Engine Cylinder 4 Combustion Pressures";
CM_ SG_ 2364623102 EngineCylinder4Timing1Pressure "In-cylinder pressure for Cylinder #4 at user-defined timing location #1 as per SPN 9845.  Will report FB00h (64256) when engine is not running.…";
CM_ SG_ 2364623102 EngineCylinder4Timing2Pressure "In-cylinder pressure for Cylinder #4 at user-defined timing location #2 as per SPN 9846.  Will report FB00h (64256) when engine is not running.…";
CM_ SG_ 2364623102 EngineCylinder4Timing3Pressure "In-cylinder pressure for Cylinder #4 at user-defined timing location #3 as per SPN 9847.  Will report FB00h (64256) when engine is not running.…";
CM_ SG_ 2364623102 EngineCylinder4Timing4Pressure "In-cylinder pressure for Cylinder #4 at user-defined timing location #4 as per SPN 9848.  Will report FB00h (64256) when engine is not running.…";
CM_ BO_ 2364623358 "Engine Cylinder 5 Combustion Pressures";
CM_ SG_ 2364623358 EngineCylinder5Timing1Pressure "In-cylinder pressure for Cylinder #5 at user-defined timing location #1 as per SPN 9845.  Will report FB00h (64256) when engine is not running.…";
CM_ SG_ 2364623358 EngineCylinder5Timing2Pressure "In-cylinder pressure for Cylinder #5 at user-defined timing location #2 as per SPN 9846.  Will report FB00h (64256) when engine is not running.…";
CM_ SG_ 2364623358 EngineCylinder5Timing3Pressure "In-cylinder pressure for Cylinder #5 at user-defined timing location #3 as per SPN 9847.  Will report FB00h (64256) when engine is not running.…";
CM_ SG_ 2364623358 EngineCylinder5Timing4Pressure "In-cylinder pressure for Cylinder #5 at user-defined timing location #4 as per SPN 9848.  Will report FB00h (64256) when engine is not running.…";
CM_ BO_ 2364623614 "Engine Cylinder 6 Combustion Pressures";
CM_ SG_ 2364623614 EngineCylinder6Timing1Pressure "In-cylinder pressure for Cylinder #6 at user-defined timing location #1 as per SPN 9845.  Will report FB00h (64256) when engine is not running.…";
CM_ SG_ 2364623614 EngineCylinder6Timing2Pressure "In-cylinder pressure for Cylinder #6 at user-defined timing location #2 as per SPN 9846.  Will report FB00h (64256) when engine is not running.…";
CM_ SG_ 2364623614 EngineCylinder6Timing3Pressure "In-cylinder pressure for Cylinder #6 at user-defined timing location #3 as per SPN 9847.  Will report FB00h (64256) when engine is not running.…";
CM_ SG_ 2364623614 EngineCylinder6Timing4Pressure "In-cylinder pressure for Cylinder #6 at user-defined timing location #4 as per SPN 9848.  Will report FB00h (64256) when engine is not running.…";
CM_ BO_ 2364623870 "Engine Cylinder 7 Combustion Pressures";
CM_ SG_ 2364623870 EngineCylinder7Timing1Pressure "In-cylinder pressure for Cylinder #7 at user-defined timing location #1 as per SPN 9845.  Will report FB00h (64256) when engine is not running.…";
CM_ SG_ 2364623870 EngineCylinder7Timing2Pressure "In-cylinder pressure for Cylinder #7 at user-defined timing location #2 as per SPN 9846.  Will report FB00h (64256) when engine is not running.…";
CM_ SG_ 2364623870 EngineCylinder7Timing3Pressure "In-cylinder pressure for Cylinder #7 at user-defined timing location #3 as per SPN 9847.  Will report FB00h (64256) when engine is not running.…";
CM_ SG_ 2364623870 EngineCylinder7Timing4Pressure "In-cylinder pressure for Cylinder #7 at user-defined timing location #4 as per SPN 9848.  Will report FB00h (64256) when engine is not running.…";
CM_ BO_ 2364624126 "Engine Cylinder 8 Combustion Pressures";
CM_ SG_ 2364624126 EngineCylinder8Timing1Pressure "In-cylinder pressure for Cylinder #8 at user-defined timing location #1 as per SPN 9845.  Will report FB00h (64256) when engine is not running.…";
CM_ SG_ 2364624126 EngineCylinder8Timing2Pressure "In-cylinder pressure for Cylinder #8 at user-defined timing location #2 as per SPN 9846.  Will report FB00h (64256) when engine is not running.…";
CM_ SG_ 2364624126 EngineCylinder8Timing3Pressure "In-cylinder pressure for Cylinder #8 at user-defined timing location #3 as per SPN 9847.  Will report FB00h (64256) when engine is not running.…";
CM_ SG_ 2364624126 EngineCylinder8Timing4Pressure "In-cylinder pressure for Cylinder #8 at user-defined timing location #4 as per SPN 9848.  Will report FB00h (64256) when engine is not running.…";
CM_ BO_ 2364624382 "Engine Cylinder 9 Combustion Pressures";
CM_ SG_ 2364624382 EngineCylinder9Timing1Pressure "In-cylinder pressure for Cylinder #9 at user-defined timing location #1 as per SPN 9845.  Will report FB00h (64256) when engine is not running.…";
CM_ SG_ 2364624382 EngineCylinder9Timing2Pressure "In-cylinder pressure for Cylinder #9 at user-defined timing location #2 as per SPN 9846.  Will report FB00h (64256) when engine is not running.…";
CM_ SG_ 2364624382 EngineCylinder9Timing3Pressure "In-cylinder pressure for Cylinder #9 at user-defined timing location #3 as per SPN 9847.  Will report FB00h (64256) when engine is not running.…";
CM_ SG_ 2364624382 EngineCylinder9Timing4Pressure "In-cylinder pressure for Cylinder #9 at user-defined timing location #4 as per SPN 9848.  Will report FB00h (64256) when engine is not running.…";
CM_ BO_ 2364624638 "Engine Cylinder 10 Combustion Pressures";
CM_ SG_ 2364624638 EngineCylinder10Timing1Pressure "In-cylinder pressure for Cylinder #10 at user-defined timing location #1 as per SPN 9845.  Will report FB00h (64256) when engine is not running.…";
CM_ SG_ 2364624638 EngineCylinder10Timing2Pressure "In-cylinder pressure for Cylinder #10 at user-defined timing location #2 as per SPN 9846.  Will report FB00h (64256) when engine is not running.…";
CM_ SG_ 2364624638 EngineCylinder10Timing3Pressure "In-cylinder pressure for Cylinder #10 at user-defined timing location #3 as per SPN 9847.  Will report FB00h (64256) when engine is not running.…";
CM_ SG_ 2364624638 EngineCylinder10Timing4Pressure "In-cylinder pressure for Cylinder #10 at user-defined timing location #4 as per SPN 9848.  Will report FB00h (64256) when engine is not running.…";
CM_ BO_ 2364624894 "Engine Cylinder 11 Combustion Pressures";
CM_ SG_ 2364624894 EngineCylinder11Timing1Pressure "In-cylinder pressure for Cylinder #11 at user-defined timing location #1 as per SPN 9845.  Will report FB00h (64256) when engine is not running.…";
CM_ SG_ 2364624894 EngineCylinder11Timing2Pressure "In-cylinder pressure for Cylinder #11 at user-defined timing location #2 as per SPN 9846.  Will report FB00h (64256) when engine is not running.…";
CM_ SG_ 2364624894 EngineCylinder11Timing3Pressure "In-cylinder pressure for Cylinder #11 at user-defined timing location #3 as per SPN 9847.  Will report FB00h (64256) when engine is not running.…";
CM_ SG_ 2364624894 EngineCylinder11Timing4Pressure "In-cylinder pressure for Cylinder #11 at user-defined timing location #4 as per SPN 9848.  Will report FB00h (64256) when engine is not running.…";
CM_ BO_ 2364625150 "Engine Cylinder 12 Combustion Pressures";
CM_ SG_ 2364625150 EngineCylinder12Timing1Pressure "In-cylinder pressure for Cylinder #12 at user-defined timing location #1 as per SPN 9845.  Will report FB00h (64256) when engine is not running.…";
CM_ SG_ 2364625150 EngineCylinder12Timing2Pressure "In-cylinder pressure for Cylinder #12 at user-defined timing location #2 as per SPN 9846.  Will report FB00h (64256) when engine is not running.…";
CM_ SG_ 2364625150 EngineCylinder12Timing3Pressure "In-cylinder pressure for Cylinder #12 at user-defined timing location #3 as per SPN 9847.  Will report FB00h (64256) when engine is not running.…";
CM_ SG_ 2364625150 EngineCylinder12Timing4Pressure "In-cylinder pressure for Cylinder #12 at user-defined timing location #4 as per SPN 9848.  Will report FB00h (64256) when engine is not running.…";
CM_ BO_ 2364625406 "Engine Cylinder 13 Combustion Pressures";
CM_ SG_ 2364625406 EngineCylinder13Timing1Pressure "In-cylinder pressure for Cylinder #13 at user-defined timing location #1 as per SPN 9845.  Will report FB00h (64256) when engine is not running.…";
CM_ SG_ 2364625406 EngineCylinder13Timing2Pressure "In-cylinder pressure for Cylinder #13 at user-defined timing location #2 as per SPN 9846.  Will report FB00h (64256) when engine is not running.…";
CM_ SG_ 2364625406 EngineCylinder13Timing3Pressure "In-cylinder pressure for Cylinder #13 at user-defined timing location #3 as per SPN 9847.  Will report FB00h (64256) when engine is not running.…";
CM_ SG_ 2364625406 EngineCylinder13Timing4Pressure "In-cylinder pressure for Cylinder #13 at user-defined timing location #4 as per SPN 9848.  Will report FB00h (64256) when engine is not running.…";
CM_ BO_ 2364625662 "Engine Cylinder 14 Combustion Pressures";
CM_ SG_ 2364625662 EngineCylinder14Timing1Pressure "In-cylinder pressure for Cylinder #14 at user-defined timing location #1 as per SPN 9845.  Will report FB00h (64256) when engine is not running.…";
CM_ SG_ 2364625662 EngineCylinder14Timing2Pressure "In-cylinder pressure for Cylinder #14 at user-defined timing location #2 as per SPN 9846.  Will report FB00h (64256) when engine is not running.…";
CM_ SG_ 2364625662 EngineCylinder14Timing3Pressure "In-cylinder pressure for Cylinder #14 at user-defined timing location #3 as per SPN 9847.  Will report FB00h (64256) when engine is not running.…";
CM_ SG_ 2364625662 EngineCylinder14Timing4Pressure "In-cylinder pressure for Cylinder #14 at user-defined timing location #4 as per SPN 9848.  Will report FB00h (64256) when engine is not running.…";
CM_ BO_ 2364625918 "Engine Cylinder 15 Combustion Pressures";
CM_ SG_ 2364625918 EngineCylinder15Timing1Pressure "In-cylinder pressure for Cylinder #15 at user-defined timing location #1 as per SPN 9845.  Will report FB00h (64256) when engine is not running.…";
CM_ SG_ 2364625918 EngineCylinder15Timing2Pressure "In-cylinder pressure for Cylinder #15 at user-defined timing location #2 as per SPN 9846.  Will report FB00h (64256) when engine is not running.…";
CM_ SG_ 2364625918 EngineCylinder15Timing3Pressure "In-cylinder pressure for Cylinder #15 at user-defined timing location #3 as per SPN 9847.  Will report FB00h (64256) when engine is not running.…";
CM_ SG_ 2364625918 EngineCylinder15Timing4Pressure "In-cylinder pressure for Cylinder #15 at user-defined timing location #4 as per SPN 9848.  Will report FB00h (64256) when engine is not running.…";
CM_ BO_ 2364626174 "Engine Cylinder 16 Combustion Pressures";
CM_ SG_ 2364626174 EngineCylinder16Timing1Pressure "In-cylinder pressure for Cylinder #16 at user-defined timing location #1 as per SPN 9845.  Will report FB00h (64256) when engine is not running.…";
CM_ SG_ 2364626174 EngineCylinder16Timing2Pressure "In-cylinder pressure for Cylinder #16 at user-defined timing location #2 as per SPN 9846.  Will report FB00h (64256) when engine is not running.…";
CM_ SG_ 2364626174 EngineCylinder16Timing3Pressure "In-cylinder pressure for Cylinder #16 at user-defined timing location #3 as per SPN 9847.  Will report FB00h (64256) when engine is not running.…";
CM_ SG_ 2364626174 EngineCylinder16Timing4Pressure "In-cylinder pressure for Cylinder #16 at user-defined timing location #4 as per SPN 9848.  Will report FB00h (64256) when engine is not running.…";
CM_ BO_ 2364626430 "Engine Cylinder 17 Combustion Pressures";
CM_ SG_ 2364626430 EngineCylinder17Timing1Pressure "In-cylinder pressure for Cylinder #17 at user-defined timing location #1 as per SPN 9845.  Will report FB00h (64256) when engine is not running.…";
CM_ SG_ 2364626430 EngineCylinder17Timing2Pressure "In-cylinder pressure for Cylinder #17 at user-defined timing location #2 as per SPN 9846.  Will report FB00h (64256) when engine is not running.…";
CM_ SG_ 2364626430 EngineCylinder17Timing3Pressure "In-cylinder pressure for Cylinder #17 at user-defined timing location #3 as per SPN 9847.  Will report FB00h (64256) when engine is not running.…";
CM_ SG_ 2364626430 EngineCylinder17Timing4Pressure "In-cylinder pressure for Cylinder #17 at user-defined timing location #4 as per SPN 9848.  Will report FB00h (64256) when engine is not running.…";
CM_ BO_ 2364626686 "Engine Cylinder 18 Combustion Pressures";
CM_ SG_ 2364626686 EngineCylinder18Timing1Pressure "In-cylinder pressure for Cylinder #18 at user-defined timing location #1 as per SPN 9845.  Will report FB00h (64256) when engine is not running.…";
CM_ SG_ 2364626686 EngineCylinder18Timing2Pressure "In-cylinder pressure for Cylinder #18 at user-defined timing location #2 as per SPN 9846.  Will report FB00h (64256) when engine is not running.…";
CM_ SG_ 2364626686 EngineCylinder18Timing3Pressure "In-cylinder pressure for Cylinder #18 at user-defined timing location #3 as per SPN 9847.  Will report FB00h (64256) when engine is not running.…";
CM_ SG_ 2364626686 EngineCylinder18Timing4Pressure "In-cylinder pressure for Cylinder #18 at user-defined timing location #4 as per SPN 9848.  Will report FB00h (64256) when engine is not running.…";
CM_ BO_ 2364626942 "Engine Cylinder 19 Combustion Pressures";
CM_ SG_ 2364626942 EngineCylinder19Timing1Pressure "In-cylinder pressure for Cylinder #19 at user-defined timing location #1 as per SPN 9845.  Will report FB00h (64256) when engine is not running.…";
CM_ SG_ 2364626942 EngineCylinder19Timing2Pressure "In-cylinder pressure for Cylinder #19 at user-defined timing location #2 as per SPN 9846.  Will report FB00h (64256) when engine is not running.…";
CM_ SG_ 2364626942 EngineCylinder19Timing3Pressure "In-cylinder pressure for Cylinder #19 at user-defined timing location #3 as per SPN 9847.  Will report FB00h (64256) when engine is not running.…";
CM_ SG_ 2364626942 EngineCylinder19Timing4Pressure "In-cylinder pressure for Cylinder #19 at user-defined timing location #4 as per SPN 9848.  Will report FB00h (64256) when engine is not running.…";
CM_ BO_ 2364627198 "Engine Cylinder 20 Combustion Pressures";
CM_ SG_ 2364627198 EngineCylinder20Timing1Pressure "In-cylinder pressure for Cylinder #20 at user-defined timing location #1 as per SPN 9845.  Will report FB00h (64256) when engine is not running.…";
CM_ SG_ 2364627198 EngineCylinder20Timing2Pressure "In-cylinder pressure for Cylinder #20 at user-defined timing location #2 as per SPN 9846.  Will report FB00h (64256) when engine is not running.…";
CM_ SG_ 2364627198 EngineCylinder20Timing3Pressure "In-cylinder pressure for Cylinder #20 at user-defined timing location #3 as per SPN 9847.  Will report FB00h (64256) when engine is not running.…";
CM_ SG_ 2364627198 EngineCylinder20Timing4Pressure "In-cylinder pressure for Cylinder #20 at user-defined timing location #4 as per SPN 9848.  Will report FB00h (64256) when engine is not running.…";
CM_ BO_ 2364627454 "Engine Cylinder 1 Combustion Timing";
CM_ SG_ 2364627454 ECd1IsttsSttCstT "Instantaneous Start of Combustion timing is defined as the crank angle for which less than 5% of the fuel mass has been burned in the present engine cycle.  The…";
CM_ SG_ 2364627454 ECd1IsttsCtCstT "Instantaneous Center of Combustion timing is defined as the crank angle for which 50% of the fuel mass has been burned in the present engine cycle.  The data wi…";
CM_ SG_ 2364627454 EngnClndr1InstntnsCmstnTmngPnt1 "Engine Cylinder 1 Instantaneous Combustion Timing, Point 1 is defined as the crank angle for which x% of the fuel mass has been burned by Cylinder 1 in the pres…";
CM_ SG_ 2364627454 EngnClndr1InstntnsCmstnTmngPnt2 "Engine Cylinder 1 Instantaneous Combustion Timing, Point 2 is defined as the crank angle for which y% of the fuel mass has been burned by Cylinder 1 in the pres…";
CM_ BO_ 2364627710 "Engine Cylinder 2 Combustion Timing";
CM_ SG_ 2364627710 ECd2IsttsSttCstT "Instantaneous Start of Combustion timing is defined as the crank angle for which less than 5% of the fuel mass has been burned in the present engine cycle.  The…";
CM_ SG_ 2364627710 ECd2IsttsCtCstT "Instantaneous Center of Combustion timing is defined as the crank angle for which 50% of the fuel mass has been burned in the present engine cycle.  The data wi…";
CM_ SG_ 2364627710 EngnClndr2InstntnsCmstnTmngPnt1 "Engine Cylinder 2 Instantaneous Combustion Timing, Point 1 is defined as the crank angle for which x% of the fuel mass has been burned by Cylinder 2 in the pres…";
CM_ SG_ 2364627710 EngnClndr2InstntnsCmstnTmngPnt2 "Engine Cylinder 2 Instantaneous Combustion Timing, Point 2 is defined as the crank angle for which y% of the fuel mass has been burned by Cylinder 2 in the pres…";
CM_ BO_ 2364627966 "Engine Cylinder 3 Combustion Timing";
CM_ SG_ 2364627966 ECd3IsttsSttCstT "Instantaneous Start of Combustion timing is defined as the crank angle for which less than 5% of the fuel mass has been burned in the present engine cycle.  The…";
CM_ SG_ 2364627966 ECd3IsttsCtCstT "Instantaneous Center of Combustion timing is defined as the crank angle for which 50% of the fuel mass has been burned in the present engine cycle.  The data wi…";
CM_ SG_ 2364627966 EngnClndr3InstntnsCmstnTmngPnt1 "Engine Cylinder 3 Instantaneous Combustion Timing, Point 1 is defined as the crank angle for which x% of the fuel mass has been burned by Cylinder 3 in the pres…";
CM_ SG_ 2364627966 EngnClndr3InstntnsCmstnTmngPnt2 "Engine Cylinder 3 Instantaneous Combustion Timing, Point 2 is defined as the crank angle for which y% of the fuel mass has been burned by Cylinder 3 in the pres…";
CM_ BO_ 2364628222 "Engine Cylinder 4 Combustion Timing";
CM_ SG_ 2364628222 ECd4IsttsSttCstT "Instantaneous Start of Combustion timing is defined as the crank angle for which less than 5% of the fuel mass has been burned in the present engine cycle.  The…";
CM_ SG_ 2364628222 ECd4IsttsCtCstT "Instantaneous Center of Combustion timing is defined as the crank angle for which 50% of the fuel mass has been burned in the present engine cycle.  The data wi…";
CM_ SG_ 2364628222 EngnClndr4InstntnsCmstnTmngPnt1 "Engine Cylinder 4 Instantaneous Combustion Timing, Point 1 is defined as the crank angle for which x% of the fuel mass has been burned by Cylinder 4 in the pres…";
CM_ SG_ 2364628222 EngnClndr4InstntnsCmstnTmngPnt2 "Engine Cylinder 4 Instantaneous Combustion Timing, Point 2 is defined as the crank angle for which y% of the fuel mass has been burned by Cylinder 4 in the pres…";
CM_ BO_ 2364628478 "Engine Cylinder 5 Combustion Timing";
CM_ SG_ 2364628478 ECd5IsttsSttCstT "Instantaneous Start of Combustion timing is defined as the crank angle for which less than 5% of the fuel mass has been burned in the present engine cycle.  The…";
CM_ SG_ 2364628478 ECd5IsttsCtCstT "Instantaneous Center of Combustion timing is defined as the crank angle for which 50% of the fuel mass has been burned in the present engine cycle.  The data wi…";
CM_ SG_ 2364628478 EngnClndr5InstntnsCmstnTmngPnt1 "Engine Cylinder 5 Instantaneous Combustion Timing, Point 1 is defined as the crank angle for which x% of the fuel mass has been burned by Cylinder 5 in the pres…";
CM_ SG_ 2364628478 EngnClndr5InstntnsCmstnTmngPnt2 "Engine Cylinder 5 Instantaneous Combustion Timing, Point 2 is defined as the crank angle for which y% of the fuel mass has been burned by Cylinder 5 in the pres…";
CM_ BO_ 2364628734 "Engine Cylinder 6 Combustion Timing";
CM_ SG_ 2364628734 ECd6IsttsSttCstT "Instantaneous Start of Combustion timing is defined as the crank angle for which less than 5% of the fuel mass has been burned in the present engine cycle.  The…";
CM_ SG_ 2364628734 ECd6IsttsCtCstT "Instantaneous Center of Combustion timing is defined as the crank angle for which 50% of the fuel mass has been burned in the present engine cycle.  The data wi…";
CM_ SG_ 2364628734 EngnClndr6InstntnsCmstnTmngPnt1 "Engine Cylinder 6 Instantaneous Combustion Timing, Point 1 is defined as the crank angle for which x% of the fuel mass has been burned by Cylinder 6 in the pres…";
CM_ SG_ 2364628734 EngnClndr6InstntnsCmstnTmngPnt2 "Engine Cylinder 6 Instantaneous Combustion Timing, Point 2 is defined as the crank angle for which y% of the fuel mass has been burned by Cylinder 6 in the pres…";
CM_ BO_ 2364628990 "Engine Cylinder 7 Combustion Timing";
CM_ SG_ 2364628990 ECd7IsttsSttCstT "Instantaneous Start of Combustion timing is defined as the crank angle for which less than 5% of the fuel mass has been burned in the present engine cycle.  The…";
CM_ SG_ 2364628990 ECd7IsttsCtCstT "Instantaneous Center of Combustion timing is defined as the crank angle for which 50% of the fuel mass has been burned in the present engine cycle.  The data wi…";
CM_ SG_ 2364628990 EngnClndr7InstntnsCmstnTmngPnt1 "Engine Cylinder 7 Instantaneous Combustion Timing, Point 1 is defined as the crank angle for which x% of the fuel mass has been burned by Cylinder 7 in the pres…";
CM_ SG_ 2364628990 EngnClndr7InstntnsCmstnTmngPnt2 "Engine Cylinder 7 Instantaneous Combustion Timing, Point 2 is defined as the crank angle for which y% of the fuel mass has been burned by Cylinder 7 in the pres…";
CM_ BO_ 2364629246 "Engine Cylinder 8 Combustion Timing";
CM_ SG_ 2364629246 ECd8IsttsSttCstT "Instantaneous Start of Combustion timing is defined as the crank angle for which less than 5% of the fuel mass has been burned in the present engine cycle.  The…";
CM_ SG_ 2364629246 ECd8IsttsCtCstT "Instantaneous Center of Combustion timing is defined as the crank angle for which 50% of the fuel mass has been burned in the present engine cycle.  The data wi…";
CM_ SG_ 2364629246 EngnClndr8InstntnsCmstnTmngPnt1 "Engine Cylinder 8 Instantaneous Combustion Timing, Point 1 is defined as the crank angle for which x% of the fuel mass has been burned by Cylinder 8 in the pres…";
CM_ SG_ 2364629246 EngnClndr8InstntnsCmstnTmngPnt2 "Engine Cylinder 8 Instantaneous Combustion Timing, Point 2 is defined as the crank angle for which y% of the fuel mass has been burned by Cylinder 8 in the pres…";
CM_ BO_ 2364629502 "Engine Cylinder 9 Combustion Timing";
CM_ SG_ 2364629502 ECd9IsttsSttCstT "Instantaneous Start of Combustion timing is defined as the crank angle for which less than 5% of the fuel mass has been burned in the present engine cycle.  The…";
CM_ SG_ 2364629502 ECd9IsttsCtCstT "Instantaneous Center of Combustion timing is defined as the crank angle for which 50% of the fuel mass has been burned in the present engine cycle.  The data wi…";
CM_ SG_ 2364629502 EngnClndr9InstntnsCmstnTmngPnt1 "Engine Cylinder 9 Instantaneous Combustion Timing, Point 1 is defined as the crank angle for which x% of the fuel mass has been burned by Cylinder 9 in the pres…";
CM_ SG_ 2364629502 EngnClndr9InstntnsCmstnTmngPnt2 "Engine Cylinder 9 Instantaneous Combustion Timing, Point 2 is defined as the crank angle for which y% of the fuel mass has been burned by Cylinder 9 in the pres…";
CM_ BO_ 2364629758 "Engine Cylinder 10 Combustion Timing";
CM_ SG_ 2364629758 ECd10IsttsSttCstT "Instantaneous Start of Combustion timing is defined as the crank angle for which less than 5% of the fuel mass has been burned in the present engine cycle.  The…";
CM_ SG_ 2364629758 ECd10IsttsCtCstT "Instantaneous Center of Combustion timing is defined as the crank angle for which 50% of the fuel mass has been burned in the present engine cycle.  The data wi…";
CM_ SG_ 2364629758 ECd10IsttsCstTPt1 "Engine Cylinder 10 Instantaneous Combustion Timing, Point 1 is defined as the crank angle for which x% of the fuel mass has been burned by Cylinder 10 in the pr…";
CM_ SG_ 2364629758 ECd10IsttsCstTPt2 "Engine Cylinder 10 Instantaneous Combustion Timing, Point 2 is defined as the crank angle for which y% of the fuel mass has been burned by Cylinder 10 in the pr…";
CM_ BO_ 2364630014 "Engine Cylinder 11 Combustion Timing";
CM_ SG_ 2364630014 ECd11IsttsSttCstT "Instantaneous Start of Combustion timing is defined as the crank angle for which less than 5% of the fuel mass has been burned in the present engine cycle.  The…";
CM_ SG_ 2364630014 ECd11IsttsCtCstT "Instantaneous Center of Combustion timing is defined as the crank angle for which 50% of the fuel mass has been burned in the present engine cycle.  The data wi…";
CM_ SG_ 2364630014 ECd11IsttsCstTPt1 "Engine Cylinder 11 Instantaneous Combustion Timing, Point 1 is defined as the crank angle for which x% of the fuel mass has been burned by Cylinder 11 in the pr…";
CM_ SG_ 2364630014 ECd11IsttsCstTPt2 "Engine Cylinder 11 Instantaneous Combustion Timing, Point 2 is defined as the crank angle for which y% of the fuel mass has been burned by Cylinder 11 in the pr…";
CM_ BO_ 2364630270 "Engine Cylinder 12 Combustion Timing";
CM_ SG_ 2364630270 ECd12IsttsSttCstT "Instantaneous Start of Combustion timing is defined as the crank angle for which less than 5% of the fuel mass has been burned in the present engine cycle.  The…";
CM_ SG_ 2364630270 ECd12IsttsCtCstT "Instantaneous Center of Combustion timing is defined as the crank angle for which 50% of the fuel mass has been burned in the present engine cycle.  The data wi…";
CM_ SG_ 2364630270 ECd12IsttsCstTPt1 "Engine Cylinder 12 Instantaneous Combustion Timing, Point 1 is defined as the crank angle for which x% of the fuel mass has been burned by Cylinder 12 in the pr…";
CM_ SG_ 2364630270 ECd12IsttsCstTPt2 "Engine Cylinder 12 Instantaneous Combustion Timing, Point 2 is defined as the crank angle for which y% of the fuel mass has been burned by Cylinder 12 in the pr…";
CM_ BO_ 2364630526 "Engine Cylinder 13 Combustion Timing";
CM_ SG_ 2364630526 ECd13IsttsSttCstT "Instantaneous Start of Combustion timing is defined as the crank angle for which less than 5% of the fuel mass has been burned in the present engine cycle.  The…";
CM_ SG_ 2364630526 ECd13IsttsCtCstT "Instantaneous Center of Combustion timing is defined as the crank angle for which 50% of the fuel mass has been burned in the present engine cycle.  The data wi…";
CM_ SG_ 2364630526 ECd13IsttsCstTPt1 "Engine Cylinder 13 Instantaneous Combustion Timing, Point 1 is defined as the crank angle for which x% of the fuel mass has been burned by Cylinder 13 in the pr…";
CM_ SG_ 2364630526 ECd13IsttsCstTPt2 "Engine Cylinder 13 Instantaneous Combustion Timing, Point 2 is defined as the crank angle for which y% of the fuel mass has been burned by Cylinder 13 in the pr…";
CM_ BO_ 2364630782 "Engine Cylinder 14 Combustion Timing";
CM_ SG_ 2364630782 ECd14IsttsSttCstT "Instantaneous Start of Combustion timing is defined as the crank angle for which less than 5% of the fuel mass has been burned in the present engine cycle.  The…";
CM_ SG_ 2364630782 ECd14IsttsCtCstT "Instantaneous Center of Combustion timing is defined as the crank angle for which 50% of the fuel mass has been burned in the present engine cycle.  The data wi…";
CM_ SG_ 2364630782 ECd14IsttsCstTPt1 "Engine Cylinder 14 Instantaneous Combustion Timing, Point 1 is defined as the crank angle for which x% of the fuel mass has been burned by Cylinder 14 in the pr…";
CM_ SG_ 2364630782 ECd14IsttsCstTPt2 "Engine Cylinder 14 Instantaneous Combustion Timing, Point 2 is defined as the crank angle for which y% of the fuel mass has been burned by Cylinder 14 in the pr…";
CM_ BO_ 2364631038 "Engine Cylinder 15 Combustion Timing";
CM_ SG_ 2364631038 ECd15IsttsSttCstT "Instantaneous Start of Combustion timing is defined as the crank angle for which less than 5% of the fuel mass has been burned in the present engine cycle.  The…";
CM_ SG_ 2364631038 ECd15IsttsCtCstT "Instantaneous Center of Combustion timing is defined as the crank angle for which 50% of the fuel mass has been burned in the present engine cycle.  The data wi…";
CM_ SG_ 2364631038 ECd15IsttsCstTPt1 "Engine Cylinder 15 Instantaneous Combustion Timing, Point 1 is defined as the crank angle for which x% of the fuel mass has been burned by Cylinder 15 in the pr…";
CM_ SG_ 2364631038 ECd15IsttsCstTPt2 "Engine Cylinder 15 Instantaneous Combustion Timing, Point 2 is defined as the crank angle for which y% of the fuel mass has been burned by Cylinder 15 in the pr…";
CM_ BO_ 2364631294 "Engine Cylinder 16 Combustion Timing";
CM_ SG_ 2364631294 ECd16IsttsSttCstT "Instantaneous Start of Combustion timing is defined as the crank angle for which less than 5% of the fuel mass has been burned in the present engine cycle.  The…";
CM_ SG_ 2364631294 ECd16IsttsCtCstT "Instantaneous Center of Combustion timing is defined as the crank angle for which 50% of the fuel mass has been burned in the present engine cycle.  The data wi…";
CM_ SG_ 2364631294 ECd16IsttsCstTPt1 "Engine Cylinder 16 Instantaneous Combustion Timing, Point 1 is defined as the crank angle for which x% of the fuel mass has been burned by Cylinder 16 in the pr…";
CM_ SG_ 2364631294 ECd16IsttsCstTPt2 "Engine Cylinder 16 Instantaneous Combustion Timing, Point 2 is defined as the crank angle for which y% of the fuel mass has been burned by Cylinder 16 in the pr…";
CM_ BO_ 2364631550 "Engine Cylinder 17 Combustion Timing";
CM_ SG_ 2364631550 ECd17IsttsSttCstT "Instantaneous Start of Combustion timing is defined as the crank angle for which less than 5% of the fuel mass has been burned in the present engine cycle.  The…";
CM_ SG_ 2364631550 ECd17IsttsCtCstT "Instantaneous Center of Combustion timing is defined as the crank angle for which 50% of the fuel mass has been burned in the present engine cycle.  The data wi…";
CM_ SG_ 2364631550 ECd17IsttsCstTPt1 "Engine Cylinder 17 Instantaneous Combustion Timing, Point 1 is defined as the crank angle for which x% of the fuel mass has been burned by Cylinder 17 in the pr…";
CM_ SG_ 2364631550 ECd17IsttsCstTPt2 "Engine Cylinder 17 Instantaneous Combustion Timing, Point 2 is defined as the crank angle for which y% of the fuel mass has been burned by Cylinder 17 in the pr…";
CM_ BO_ 2364631806 "Engine Cylinder 18 Combustion Timing";
CM_ SG_ 2364631806 ECd18IsttsSttCstT "Instantaneous Start of Combustion timing is defined as the crank angle for which less than 5% of the fuel mass has been burned in the present engine cycle.  The…";
CM_ SG_ 2364631806 ECd18IsttsCtCstT "Instantaneous Center of Combustion timing is defined as the crank angle for which 50% of the fuel mass has been burned in the present engine cycle.  The data wi…";
CM_ SG_ 2364631806 ECd18IsttsCstTPt1 "Engine Cylinder 18 Instantaneous Combustion Timing, Point 1 is defined as the crank angle for which x% of the fuel mass has been burned by Cylinder 18 in the pr…";
CM_ SG_ 2364631806 ECd18IsttsCstTPt2 "Engine Cylinder 18 Instantaneous Combustion Timing, Point 2 is defined as the crank angle for which y% of the fuel mass has been burned by Cylinder 18 in the pr…";
CM_ BO_ 2364632062 "Engine Cylinder 19 Combustion Timing";
CM_ SG_ 2364632062 ECd19IsttsSttCstT "Instantaneous Start of Combustion timing is defined as the crank angle for which less than 5% of the fuel mass has been burned in the present engine cycle.  The…";
CM_ SG_ 2364632062 ECd19IsttsCtCstT "Instantaneous Center of Combustion timing is defined as the crank angle for which 50% of the fuel mass has been burned in the present engine cycle.  The data wi…";
CM_ SG_ 2364632062 ECd19IsttsCstTPt1 "Engine Cylinder 19 Instantaneous Combustion Timing, Point 1 is defined as the crank angle for which x% of the fuel mass has been burned by Cylinder 19 in the pr…";
CM_ SG_ 2364632062 ECd19IsttsCstTPt2 "Engine Cylinder 19 Instantaneous Combustion Timing, Point 2 is defined as the crank angle for which y% of the fuel mass has been burned by Cylinder 19 in the pr…";
CM_ BO_ 2364632318 "Engine Cylinder 20 Combustion Timing";
CM_ SG_ 2364632318 ECd20IsttsSttCstT "Instantaneous Start of Combustion timing is defined as the crank angle for which less than 5% of the fuel mass has been burned in the present engine cycle.  The…";
CM_ SG_ 2364632318 ECd20IsttsCtCstT "Instantaneous Center of Combustion timing is defined as the crank angle for which 50% of the fuel mass has been burned in the present engine cycle.  The data wi…";
CM_ SG_ 2364632318 ECd20IsttsCstTPt1 "Engine Cylinder 20 Instantaneous Combustion Timing, Point 1 is defined as the crank angle for which x% of the fuel mass has been burned by Cylinder 20 in the pr…";
CM_ SG_ 2364632318 ECd20IsttsCstTPt2 "Engine Cylinder 20 Instantaneous Combustion Timing, Point 2 is defined as the crank angle for which y% of the fuel mass has been burned by Cylinder 20 in the pr…";
CM_ BO_ 2364632574 "Engine Cylinder 1 Combustion Metrics";
CM_ SG_ 2364632574 ECd1IsttsPCstPssT "The timing in crank angle degrees of the observed peak pressure during the current combustion cycle.  When the combustion happens after the TDC (Top Dead Center…";
CM_ SG_ 2364632574 ECd1IsttsIdtdMEtvPss "The indicated mean effective pressure (IMEP) is the work delivered to the piston over the entire cycle, per unit displaced volume.  This SPN reports for the cur…";
CM_ SG_ 2364632574 ECd1IdtdMEtvPssCtV "The indicated mean effective pressure coefficient of variance is the variability seen in IMEP over the number of engine cycles in SPN6394 represented as a perce…";
CM_ SG_ 2364632574 EngineCylinder1MisfireRate "The misfire rate of engine cylinder 1 over the number of engine cycles in SPN6394 represented as a percentage.…";
CM_ BO_ 2364632830 "Engine Cylinder 2 Combustion Metrics";
CM_ SG_ 2364632830 ECd2IsttsPCstPssT "The timing in crank angle degrees of the observed peak pressure during the current combustion cycle.  When the combustion happens after the TDC (Top Dead Center…";
CM_ SG_ 2364632830 ECd2IsttsIdtdMEtvPss "The indicated mean effective pressure (IMEP) is the work delivered to the piston over the entire cycle, per unit displaced volume.  This SPN reports for the cur…";
CM_ SG_ 2364632830 ECd2IdtdMEtvPssCtV "The indicated mean effective pressure coefficient of variance is the variability seen in IMEP over the number of engine cycles in SPN6394 represented as a perce…";
CM_ SG_ 2364632830 EngineCylinder2MisfireRate "The misfire rate of engine Cylinder 2 over the number of engine cycles in SPN6394 represented as a percentage.…";
CM_ BO_ 2364633086 "Engine Cylinder 3 Combustion Metrics";
CM_ SG_ 2364633086 ECd3IsttsPCstPssT "The timing in crank angle degrees of the observed peak pressure during the current combustion cycle.  When the combustion happens after the TDC (Top Dead Center…";
CM_ SG_ 2364633086 ECd3IsttsIdtdMEtvPss "The indicated mean effective pressure (IMEP) is the work delivered to the piston over the entire cycle, per unit displaced volume.  This SPN reports for the cur…";
CM_ SG_ 2364633086 ECd3IdtdMEtvPssCtV "The indicated mean effective pressure coefficient of variance is the variability seen in IMEP over the number of engine cycles in SPN6394 represented as a perce…";
CM_ SG_ 2364633086 EngineCylinder3MisfireRate "The misfire rate of engine Cylinder 3 over the number of engine cycles in SPN6394 represented as a percentage.…";
CM_ BO_ 2364633342 "Engine Cylinder 4 Combustion Metrics";
CM_ SG_ 2364633342 ECd4IsttsPCstPssT "The timing in crank angle degrees of the observed peak pressure during the current combustion cycle.  When the combustion happens after the TDC (Top Dead Center…";
CM_ SG_ 2364633342 ECd4IsttsIdtdMEtvPss "The indicated mean effective pressure (IMEP) is the work delivered to the piston over the entire cycle, per unit displaced volume.  This SPN reports for the cur…";
CM_ SG_ 2364633342 ECd4IdtdMEtvPssCtV "The indicated mean effective pressure coefficient of variance is the variability seen in IMEP over the number of engine cycles in SPN6394 represented as a perce…";
CM_ SG_ 2364633342 EngineCylinder4MisfireRate "The misfire rate of engine Cylinder 4 over the number of engine cycles in SPN6394 represented as a percentage.…";
CM_ BO_ 2364633598 "Engine Cylinder 5 Combustion Metrics";
CM_ SG_ 2364633598 ECd5IsttsPCstPssT "The timing in crank angle degrees of the observed peak pressure during the current combustion cycle.  When the combustion happens after the TDC (Top Dead Center…";
CM_ SG_ 2364633598 ECd5IsttsIdtdMEtvPss "The indicated mean effective pressure (IMEP) is the work delivered to the piston over the entire cycle, per unit displaced volume.  This SPN reports for the cur…";
CM_ SG_ 2364633598 ECd5IdtdMEtvPssCtV "The indicated mean effective pressure coefficient of variance is the variability seen in IMEP over the number of engine cycles in SPN6394 represented as a perce…";
CM_ SG_ 2364633598 EngineCylinder5MisfireRate "The misfire rate of engine Cylinder 5 over the number of engine cycles in SPN6394 represented as a percentage.…";
CM_ BO_ 2364633854 "Engine Cylinder 6 Combustion Metrics";
CM_ SG_ 2364633854 ECd6IsttsPCstPssT "The timing in crank angle degrees of the observed peak pressure during the current combustion cycle.  When the combustion happens after the TDC (Top Dead Center…";
CM_ SG_ 2364633854 ECd6IsttsIdtdMEtvPss "The indicated mean effective pressure (IMEP) is the work delivered to the piston over the entire cycle, per unit displaced volume.  This SPN reports for the cur…";
CM_ SG_ 2364633854 ECd6IdtdMEtvPssCtV "The indicated mean effective pressure coefficient of variance is the variability seen in IMEP over the number of engine cycles in SPN6394 represented as a perce…";
CM_ SG_ 2364633854 EngineCylinder6MisfireRate "The misfire rate of engine Cylinder 6 over the number of engine cycles in SPN6394 represented as a percentage.…";
CM_ BO_ 2364634110 "Engine Cylinder 7 Combustion Metrics";
CM_ SG_ 2364634110 ECd7IsttsPCstPssT "The timing in crank angle degrees of the observed peak pressure during the current combustion cycle.  When the combustion happens after the TDC (Top Dead Center…";
CM_ SG_ 2364634110 ECd7IsttsIdtdMEtvPss "The indicated mean effective pressure (IMEP) is the work delivered to the piston over the entire cycle, per unit displaced volume.  This SPN reports for the cur…";
CM_ SG_ 2364634110 ECd7IdtdMEtvPssCtV "The indicated mean effective pressure coefficient of variance is the variability seen in IMEP over the number of engine cycles in SPN6394 represented as a perce…";
CM_ SG_ 2364634110 EngineCylinder7MisfireRate "The misfire rate of engine Cylinder 7 over the number of engine cycles in SPN6394 represented as a percentage.…";
CM_ BO_ 2364634366 "Engine Cylinder 8 Combustion Metrics";
CM_ SG_ 2364634366 ECd8IsttsPCstPssT "The timing in crank angle degrees of the observed peak pressure during the current combustion cycle.  When the combustion happens after the TDC (Top Dead Center…";
CM_ SG_ 2364634366 ECd8IsttsIdtdMEtvPss "The indicated mean effective pressure (IMEP) is the work delivered to the piston over the entire cycle, per unit displaced volume.  This SPN reports for the cur…";
CM_ SG_ 2364634366 ECd8IdtdMEtvPssCtV "The indicated mean effective pressure coefficient of variance is the variability seen in IMEP over the number of engine cycles in SPN6394 represented as a perce…";
CM_ SG_ 2364634366 EngineCylinder8MisfireRate "The misfire rate of engine Cylinder 8 over the number of engine cycles in SPN6394 represented as a percentage.…";
CM_ BO_ 2364634622 "Engine Cylinder 9 Combustion Metrics";
CM_ SG_ 2364634622 ECd9IsttsPCstPssT "The timing in crank angle degrees of the observed peak pressure during the current combustion cycle.  When the combustion happens after the TDC (Top Dead Center…";
CM_ SG_ 2364634622 ECd9IsttsIdtdMEtvPss "The indicated mean effective pressure (IMEP) is the work delivered to the piston over the entire cycle, per unit displaced volume.  This SPN reports for the cur…";
CM_ SG_ 2364634622 ECd9IdtdMEtvPssCtV "The indicated mean effective pressure coefficient of variance is the variability seen in IMEP over the number of engine cycles in SPN6394 represented as a perce…";
CM_ SG_ 2364634622 EngineCylinder9MisfireRate "The misfire rate of engine Cylinder 9 over the number of engine cycles in SPN6394 represented as a percentage.…";
CM_ BO_ 2364634878 "Engine Cylinder 10 Combustion Metrics";
CM_ SG_ 2364634878 ECd10IsttsPCstPssT "The timing in crank angle degrees of the observed peak pressure during the current combustion cycle.  When the combustion happens after the TDC (Top Dead Center…";
CM_ SG_ 2364634878 ECd10IsttsIdtdMEtvPss "The indicated mean effective pressure (IMEP) is the work delivered to the piston over the entire cycle, per unit displaced volume.  This SPN reports for the cur…";
CM_ SG_ 2364634878 ECd10IdtdMEtvPssCtV "The indicated mean effective pressure coefficient of variance is the variability seen in IMEP over the number of engine cycles in SPN6394 represented as a perce…";
CM_ SG_ 2364634878 EngineCylinder10MisfireRate "The misfire rate of engine Cylinder 10 over the number of engine cycles in SPN6394 represented as a percentage.…";
CM_ BO_ 2364635134 "Engine Cylinder 11 Combustion Metrics";
CM_ SG_ 2364635134 ECd11IsttsPCstPssT "The timing in crank angle degrees of the observed peak pressure during the current combustion cycle.  When the combustion happens after the TDC (Top Dead Center…";
CM_ SG_ 2364635134 ECd11IsttsIdtdMEtvPss "The indicated mean effective pressure (IMEP) is the work delivered to the piston over the entire cycle, per unit displaced volume.  This SPN reports for the cur…";
CM_ SG_ 2364635134 ECd11IdtdMEtvPssCtV "The indicated mean effective pressure coefficient of variance is the variability seen in IMEP over the number of engine cycles in SPN6394 represented as a perce…";
CM_ SG_ 2364635134 EngineCylinder11MisfireRate "The misfire rate of engine Cylinder 11 over the number of engine cycles in SPN6394 represented as a percentage.…";
CM_ BO_ 2364635390 "Engine Cylinder 12 Combustion Metrics";
CM_ SG_ 2364635390 ECd12IsttsPCstPssT "The timing in crank angle degrees of the observed peak pressure during the current combustion cycle.  When the combustion happens after the TDC (Top Dead Center…";
CM_ SG_ 2364635390 ECd12IsttsIdtdMEtvPss "The indicated mean effective pressure (IMEP) is the work delivered to the piston over the entire cycle, per unit displaced volume.  This SPN reports for the cur…";
CM_ SG_ 2364635390 ECd12IdtdMEtvPssCtV "The indicated mean effective pressure coefficient of variance is the variability seen in IMEP over the number of engine cycles in SPN6394 represented as a perce…";
CM_ SG_ 2364635390 EngineCylinder12MisfireRate "The misfire rate of engine Cylinder 12 over the number of engine cycles in SPN6394 represented as a percentage.…";
CM_ BO_ 2364635646 "Engine Cylinder 13 Combustion Metrics";
CM_ SG_ 2364635646 ECd13IsttsPCstPssT "The timing in crank angle degrees of the observed peak pressure during the current combustion cycle.  When the combustion happens after the TDC (Top Dead Center…";
CM_ SG_ 2364635646 ECd13IsttsIdtdMEtvPss "The indicated mean effective pressure (IMEP) is the work delivered to the piston over the entire cycle, per unit displaced volume.  This SPN reports for the cur…";
CM_ SG_ 2364635646 ECd13IdtdMEtvPssCtV "The indicated mean effective pressure coefficient of variance is the variability seen in IMEP over the number of engine cycles in SPN6394 represented as a perce…";
CM_ SG_ 2364635646 EngineCylinder13MisfireRate "The misfire rate of engine Cylinder 13 over the number of engine cycles in SPN6394 represented as a percentage.…";
CM_ BO_ 2364635902 "Engine Cylinder 14 Combustion Metrics";
CM_ SG_ 2364635902 ECd14IsttsPCstPssT "The timing in crank angle degrees of the observed peak pressure during the current combustion cycle.  When the combustion happens after the TDC (Top Dead Center…";
CM_ SG_ 2364635902 ECd14IsttsIdtdMEtvPss "The indicated mean effective pressure (IMEP) is the work delivered to the piston over the entire cycle, per unit displaced volume.  This SPN reports for the cur…";
CM_ SG_ 2364635902 ECd14IdtdMEtvPssCtV "The indicated mean effective pressure coefficient of variance is the variability seen in IMEP over the number of engine cycles in SPN6394 represented as a perce…";
CM_ SG_ 2364635902 EngineCylinder14MisfireRate "The misfire rate of engine Cylinder 14 over the number of engine cycles in SPN6394 represented as a percentage.…";
CM_ BO_ 2364636158 "Engine Cylinder 15 Combustion Metrics";
CM_ SG_ 2364636158 ECd15IsttsPCstPssT "The timing in crank angle degrees of the observed peak pressure during the current combustion cycle.  When the combustion happens after the TDC (Top Dead Center…";
CM_ SG_ 2364636158 ECd15IsttsIdtdMEtvPss "The indicated mean effective pressure (IMEP) is the work delivered to the piston over the entire cycle, per unit displaced volume.  This SPN reports for the cur…";
CM_ SG_ 2364636158 ECd15IdtdMEtvPssCtV "The indicated mean effective pressure coefficient of variance is the variability seen in IMEP over the number of engine cycles in SPN6394 represented as a perce…";
CM_ SG_ 2364636158 EngineCylinder15MisfireRate "The misfire rate of engine Cylinder 15 over the number of engine cycles in SPN6394 represented as a percentage.…";
CM_ BO_ 2364636414 "Engine Cylinder 16 Combustion Metrics";
CM_ SG_ 2364636414 ECd16IsttsPCstPssT "The timing in crank angle degrees of the observed peak pressure during the current combustion cycle.  When the combustion happens after the TDC (Top Dead Center…";
CM_ SG_ 2364636414 ECd16IsttsIdtdMEtvPss "The indicated mean effective pressure (IMEP) is the work delivered to the piston over the entire cycle, per unit displaced volume.  This SPN reports for the cur…";
CM_ SG_ 2364636414 ECd16IdtdMEtvPssCtV "The indicated mean effective pressure coefficient of variance is the variability seen in IMEP over the number of engine cycles in SPN6394 represented as a perce…";
CM_ SG_ 2364636414 EngineCylinder16MisfireRate "The misfire rate of engine Cylinder 16 over the number of engine cycles in SPN6394 represented as a percentage.…";
CM_ BO_ 2364636670 "Engine Cylinder 17 Combustion Metrics";
CM_ SG_ 2364636670 ECd17IsttsPCstPssT "The timing in crank angle degrees of the observed peak pressure during the current combustion cycle.  When the combustion happens after the TDC (Top Dead Center…";
CM_ SG_ 2364636670 ECd17IsttsIdtdMEtvPss "The indicated mean effective pressure (IMEP) is the work delivered to the piston over the entire cycle, per unit displaced volume.  This SPN reports for the cur…";
CM_ SG_ 2364636670 ECd17IdtdMEtvPssCtV "The indicated mean effective pressure coefficient of variance is the variability seen in IMEP over the number of engine cycles in SPN6394 represented as a perce…";
CM_ SG_ 2364636670 EngineCylinder17MisfireRate "The misfire rate of engine Cylinder 17 over the number of engine cycles in SPN6394 represented as a percentage.…";
CM_ BO_ 2364636926 "Engine Cylinder 18 Combustion Metrics";
CM_ SG_ 2364636926 ECd18IsttsPCstPssT "The timing in crank angle degrees of the observed peak pressure during the current combustion cycle.  When the combustion happens after the TDC (Top Dead Center…";
CM_ SG_ 2364636926 ECd18IsttsIdtdMEtvPss "The indicated mean effective pressure (IMEP) is the work delivered to the piston over the entire cycle, per unit displaced volume.  This SPN reports for the cur…";
CM_ SG_ 2364636926 ECd18IdtdMEtvPssCtV "The indicated mean effective pressure coefficient of variance is the variability seen in IMEP over the number of engine cycles in SPN6394 represented as a perce…";
CM_ SG_ 2364636926 EngineCylinder18MisfireRate "The misfire rate of engine Cylinder 18 over the number of engine cycles in SPN6394 represented as a percentage.…";
CM_ BO_ 2364637182 "Engine Cylinder 19 Combustion Metrics";
CM_ SG_ 2364637182 ECd19IsttsPCstPssT "The timing in crank angle degrees of the observed peak pressure during the current combustion cycle.  When the combustion happens after the TDC (Top Dead Center…";
CM_ SG_ 2364637182 ECd19IsttsIdtdMEtvPss "The indicated mean effective pressure (IMEP) is the work delivered to the piston over the entire cycle, per unit displaced volume.  This SPN reports for the cur…";
CM_ SG_ 2364637182 ECd19IdtdMEtvPssCtV "The indicated mean effective pressure coefficient of variance is the variability seen in IMEP over the number of engine cycles in SPN6394 represented as a perce…";
CM_ SG_ 2364637182 EngineCylinder19MisfireRate "The misfire rate of engine Cylinder 19 over the number of engine cycles in SPN6394 represented as a percentage.…";
CM_ BO_ 2364637438 "Engine Cylinder 20 Combustion Metrics";
CM_ SG_ 2364637438 ECd20IsttsPCstPssT "The timing in crank angle degrees of the observed peak pressure during the current combustion cycle.  When the combustion happens after the TDC (Top Dead Center…";
CM_ SG_ 2364637438 ECd20IsttsIdtdMEtvPss "The indicated mean effective pressure (IMEP) is the work delivered to the piston over the entire cycle, per unit displaced volume.  This SPN reports for the cur…";
CM_ SG_ 2364637438 ECd20IdtdMEtvPssCtV "The indicated mean effective pressure coefficient of variance is the variability seen in IMEP over the number of engine cycles in SPN6394 represented as a perce…";
CM_ SG_ 2364637438 EngineCylinder20MisfireRate "The misfire rate of engine Cylinder 20 over the number of engine cycles in SPN6394 represented as a percentage.…";
CM_ BO_ 2364637694 "Motor/Generator 1 Inverter Mode Feedback 1";
CM_ SG_ 2364637694 MtrGnrtr1InvrtrMdFdk1CRC "The CRC is defined as follows: • Length: 8 bits • Polynomial: x^8+x^5+x^3+x^2+x+1 • Initial Value: FFh • Input Data Reflection: Not reflected • Result Data Refl…";
CM_ SG_ 2364637694 MtrGnrtr1InvrtrMdFdk1Cntr "The message counter is used to detect situations where the transmitting ECU malfunction repeats the same frame all the time. The receiver of the information may…";
CM_ SG_ 2364637694 MtrGnrtr1InvrtrCntrlLmtsOvrrdMd "During normal operation this will have the same value as SPN 10159 [Control Limits Request Override Mode].  0 = Operating limits are not overridden.  If a limit…";
CM_ SG_ 2364637694 MtrGnrtr1InvrtrCntrlStpntMd "Reports the inverter mode (See SPN 10162 [Control Setpoint Mode Request] for requested mode).Passive modes:  0 = Powered On - the inverter is commanded to be po…";
CM_ SG_ 2364637694 MtrGnrtr1InvrtrHVILStts "Reports the High Voltage Interlock Loop (HVIL) state.00b = HVIL Closed01b = HVIL Open10b = Error11b = Not Available…";
CM_ BO_ 2565964542 "Motor/Generator 1 Inverter Limits Active Power";
CM_ SG_ 2565964542 MtrGnrtr1InvrtrLmtsAtvPwrCRC "The CRC is defined as follows: • Length: 8 bits • Polynomial: x^8+x^5+x^3+x^2+x+1 • Initial Value: FFh • Input Data Reflection: Not reflected • Result Data Refl…";
CM_ SG_ 2565964542 MtrGnrtr1InvrtrLmtsAtvPwrCntr "The message counter is used to detect situations where the transmitting ECU malfunction repeats the same frame all the time. The receiver of the information may…";
CM_ BO_ 2565964798 "Motor/Generator 1 Inverter Limits Active Mechanical";
CM_ SG_ 2565964798 MtrGnrtr1InvrtrLmtsAtvMhnlCRC "The CRC is defined as follows: • Length: 8 bits • Polynomial: x^8+x^5+x^3+x^2+x+1 • Initial Value: FFh • Input Data Reflection: Not reflected • Result Data Refl…";
CM_ SG_ 2565964798 MtrGnrtr1InvrtrLmtsAtvMhnlCntr "The message counter is used to detect situations where the transmitting ECU malfunction repeats the same frame all the time. The receiver of the information may…";
CM_ BO_ 2565965054 "Motor/Generator 1 Inverter Limits Active DC Side";
CM_ SG_ 2565965054 MtrGnrtr1InvrtrLmtsAtvDCSdCRC "The CRC is defined as follows: • Length: 8 bits • Polynomial: x^8+x^5+x^3+x^2+x+1 • Initial Value: FFh • Input Data Reflection: Not reflected • Result Data Refl…";
CM_ SG_ 2565965054 MtrGnrtr1InvrtrLmtsAtvDCSdCntr "The message counter is used to detect situations where the transmitting ECU malfunction repeats the same frame all the time. The receiver of the information may…";
CM_ BO_ 2565965310 "Motor/Generator 1 Inverter Low Voltage";
CM_ SG_ 2565965310 MtrGnrtr1InvrtrSwthdIgntnVltg "Switched Ignition voltage supplied to this instance of the inverter controller.…";
CM_ SG_ 2565965310 MtrGnrtr1InvrtrUnswthdSLIVltg "Continuously supplied SLI power to this instance of the inverter controller.…";
CM_ BO_ 2364638974 "Motor/Generator 2 Inverter Mode Feedback 1";
CM_ SG_ 2364638974 MtrGnrtr2InvrtrMdFdk1CRC "The CRC is defined as follows: • Length: 8 bits • Polynomial: x^8+x^5+x^3+x^2+x+1 • Initial Value: FFh • Input Data Reflection: Not reflected • Result Data Refl…";
CM_ SG_ 2364638974 MtrGnrtr2InvrtrMdFdk1Cntr "The message counter is used to detect situations where the transmitting ECU malfunction repeats the same frame all the time. The receiver of the information may…";
CM_ SG_ 2364638974 MtrGnrtr2InvrtrCntrlLmtsOvrrdMd "During normal operation this will have the same value as SPN 10225 [Control Limits Request Override Mode].0 = Operating limits are not overridden.  If a limit w…";
CM_ SG_ 2364638974 MtrGnrtr2InvrtrCntrlStpntMd "Reports the inverter mode (See SPN 10228 [Control Setpoint Mode Request] for requested mode).Passive modes:  0 = Powered On - the inverter is commanded to be po…";
CM_ SG_ 2364638974 MtrGnrtr2InvrtrHVILStts "Reports the High Voltage Interlock Loop (HVIL) state.00b = HVIL Closed01b = HVIL Open10b = Error11b = Not Available…";
CM_ BO_ 2565965822 "Motor/Generator 2 Inverter Limits Active Power";
CM_ SG_ 2565965822 MtrGnrtr2InvrtrLmtsAtvPwrCRC "The CRC is defined as follows: • Length: 8 bits • Polynomial: x^8+x^5+x^3+x^2+x+1 • Initial Value: FFh • Input Data Reflection: Not reflected • Result Data Refl…";
CM_ SG_ 2565965822 MtrGnrtr2InvrtrLmtsAtvPwrCntr "The message counter is used to detect situations where the transmitting ECU malfunction repeats the same frame all the time. The receiver of the information may…";
CM_ BO_ 2565966078 "Motor/Generator 2 Inverter Limits Active Mechanical";
CM_ SG_ 2565966078 MtrGnrtr2InvrtrLmtsAtvMhnlCRC "The CRC is defined as follows: • Length: 8 bits • Polynomial: x^8+x^5+x^3+x^2+x+1 • Initial Value: FFh • Input Data Reflection: Not reflected • Result Data Refl…";
CM_ SG_ 2565966078 MtrGnrtr2InvrtrLmtsAtvMhnlCntr "The message counter is used to detect situations where the transmitting ECU malfunction repeats the same frame all the time. The receiver of the information may…";
CM_ BO_ 2565966334 "Motor/Generator 2 Inverter Limits Active DC Side";
CM_ SG_ 2565966334 MtrGnrtr2InvrtrLmtsAtvDCSdCRC "The CRC is defined as follows: • Length: 8 bits • Polynomial: x^8+x^5+x^3+x^2+x+1 • Initial Value: FFh • Input Data Reflection: Not reflected • Result Data Refl…";
CM_ SG_ 2565966334 MtrGnrtr2InvrtrLmtsAtvDCSdCntr "The message counter is used to detect situations where the transmitting ECU malfunction repeats the same frame all the time. The receiver of the information may…";
CM_ BO_ 2565966590 "Motor/Generator 2 Inverter Low Voltage";
CM_ SG_ 2565966590 MtrGnrtr2InvrtrSwthdIgntnVltg "Switched Ignition voltage supplied to this instance of the inverter controller.…";
CM_ SG_ 2565966590 MtrGnrtr2InvrtrUnswthdSLIVltg "Continuously supplied SLI power to this instance of the inverter controller.…";
CM_ BO_ 2365287678 "Motor/Generator 2 Inverter Reference 1";
CM_ SG_ 2365287678 MtrGnrtr2InvrtrRfrn1CRC "The CRC is defined as follows: • Length: 8 bits • Polynomial: x^8+x^5+x^3+x^2+x+1 • Initial Value: FFh • Input Data Reflection: Not reflected • Result Data Refl…";
CM_ SG_ 2365287678 MtrGnrtr2InvrtrRfrn1Cntr "The message counter is used to detect situations where the transmitting ECU malfunction repeats the same frame all the time. The receiver of the information may…";
CM_ SG_ 2365287678 MtrGnrtr2InvrtrRfrnTrq "This value is used for converting torque in percent to units of Nm.Value in Nm = (Percent Value)/(100%) * (Reference Torque)For example, if this parameter has a…";
CM_ SG_ 2365287678 MtrGnrtr2InvrtrRfrnSpd "This value is used for converting Speed in percent to units of rpm.Value in rpm = (Percent Value)/(100%) * (Reference Speed)For example, if this parameter has a…";
CM_ SG_ 2365287678 MtrGnrtr2InvrtrRfrnPwr "This value is used for converting power in percent to units of kW.  It is applicable to both mechanical and electrical power.(Value in kW) = (Percent Value)/(10…";
CM_ BO_ 2365287934 "Motor/Generator 2 Inverter Status 1";
CM_ SG_ 2365287934 MtrGnrtr2InvrtrStts1CRC "The CRC is defined as follows: • Length: 8 bits • Polynomial: x^8+x^5+x^3+x^2+x+1 • Initial Value: FFh • Input Data Reflection: Not reflected • Result Data Refl…";
CM_ SG_ 2365287934 MtrGnrtr2InvrtrStts1Cntr "The message counter is used to detect situations where the transmitting ECU malfunction repeats the same frame all the time. The receiver of the information may…";
CM_ SG_ 2365287934 MotorGenerator2Speed "The measured or estimated motor speed.  This refers to the motor rotor output and excludes any gearbox that may be attached to the motor.   Refer to SPN 10237 […";
CM_ BO_ 2365288190 "Motor/Generator 2 Inverter Reference 2";
CM_ SG_ 2365288190 MtrGnrtr2InvrtrRfrn2CRC "The CRC is defined as follows: • Length: 8 bits • Polynomial: x^8+x^5+x^3+x^2+x+1 • Initial Value: FFh • Input Data Reflection: Not reflected • Result Data Refl…";
CM_ SG_ 2365288190 MtrGnrtr2InvrtrRfrn2Cntr "The message counter is used to detect situations where the transmitting ECU malfunction repeats the same frame all the time. The receiver of the information may…";
CM_ SG_ 2365288190 MtrGnrtr2InvrtrRfrnCrrnt "This value is used for converting inverter current in percent to units of Amps (RMS or DC).(Value in Amps) = (Percent Value)/(100%) * (Reference Current)For exa…";
CM_ SG_ 2365288190 MtrGnrtr2InvrtrRfrnVltg "This value is used for converting inverter voltage in percent to units of Volts (RMS or DC).(Value in Volts) = (Percent Value)/(100%) * (Reference Voltage)For e…";
CM_ BO_ 2566615038 "Motor/Generator 2 Inverter Temperature";
CM_ SG_ 2566615038 MtrGnrtr2InvrtrTmprtr1 "The exact location of this temperature can be defined by the manufacturer.  It is intended to be located somewhere on the inverter. …";
CM_ SG_ 2566615038 MtrGnrtr2InvrtrTmprtr2 "The exact location of this temperature can be defined by the manufacturer.  It is intended to be located somewhere on the inverter. …";
CM_ SG_ 2566615038 MtrGnrtr2InvrtrTmprtr3 "The exact location of this temperature can be defined by the manufacturer.  It is intended to be located somewhere on the inverter. …";
CM_ SG_ 2566615038 MtrGnrtr2InvrtrTmprtr4 "The exact location of this temperature can be defined by the manufacturer.  It is intended to be located somewhere on the inverter. …";
CM_ BO_ 2566615294 "Motor/Generator 2 Inverter Motor Temperature";
CM_ SG_ 2566615294 MotorGenerator2Temperature1 "The exact location of this temperature can be defined by the manufacturer.  It is intended to located somewhere on the motor.…";
CM_ SG_ 2566615294 MotorGenerator2Temperature2 "The exact location of this temperature can be defined by the manufacturer.  It is intended to located somewhere on the motor. …";
CM_ SG_ 2566615294 MotorGenerator2Temperature3 "The exact location of this temperature can be defined by the manufacturer.  It is intended to located somewhere on the motor. …";
CM_ SG_ 2566615294 MotorGenerator2Temperature4 "The exact location of this temperature can be defined by the manufacturer.  It is intended to located somewhere on the motor. …";
CM_ BO_ 2566615550 "Motor/Generator 1 Inverter Motor Temperature";
CM_ SG_ 2566615550 MotorGenerator1Temperature1 "The exact location of this temperature can be defined by the manufacturer.  It is intended to located somewhere on the motor.…";
CM_ SG_ 2566615550 MotorGenerator1Temperature2 "The exact location of this temperature can be defined by the manufacturer.  It is intended to located somewhere on the motor. …";
CM_ SG_ 2566615550 MotorGenerator1Temperature3 "The exact location of this temperature can be defined by the manufacturer.  It is intended to located somewhere on the motor. …";
CM_ SG_ 2566615550 MotorGenerator1Temperature4 "The exact location of this temperature can be defined by the manufacturer.  It is intended to located somewhere on the motor. …";
CM_ BO_ 2566615806 "Motor/Generator 1 Inverter Temperature";
CM_ SG_ 2566615806 MtrGnrtr1InvrtrTmprtr1 "The exact location of this temperature can be defined by the manufacturer.  It is intended to be located somewhere on the inverter. …";
CM_ SG_ 2566615806 MtrGnrtr1InvrtrTmprtr2 "The exact location of this temperature can be defined by the manufacturer.  It is intended to be located somewhere on the inverter. …";
CM_ SG_ 2566615806 MtrGnrtr1InvrtrTmprtr3 "The exact location of this temperature can be defined by the manufacturer.  It is intended to be located somewhere on the inverter. …";
CM_ SG_ 2566615806 MtrGnrtr1InvrtrTmprtr4 "The exact location of this temperature can be defined by the manufacturer.  It is intended to be located somewhere on the inverter. …";
CM_ BO_ 2365289470 "Motor/Generator 1 Inverter Reference 2";
CM_ SG_ 2365289470 MtrGnrtr1InvrtrRfrn2CRC "The CRC is defined as follows: • Length: 8 bits • Polynomial: x^8+x^5+x^3+x^2+x+1 • Initial Value: FFh • Input Data Reflection: Not reflected • Result Data Refl…";
CM_ SG_ 2365289470 MtrGnrtr1InvrtrRfrn2Cntr "The message counter is used to detect situations where the transmitting ECU malfunction repeats the same frame all the time. The receiver of the information may…";
CM_ SG_ 2365289470 MtrGnrtr1InvrtrRfrnCrrnt "This value is used for converting inverter current in percent to units of Amps (RMS or DC).(Value in Amps) = (Percent Value)/(100%) * (Reference Current)For exa…";
CM_ SG_ 2365289470 MtrGnrtr1InvrtrRfrnVltg "This value is used for converting inverter voltage in percent to units of Volts (RMS or DC).(Value in Volts) = (Percent Value)/(100%) * (Reference Voltage)For e…";
CM_ BO_ 2365289726 "Motor/Generator 1 Inverter Status 1";
CM_ SG_ 2365289726 MtrGnrtr1InvrtrStts1CRC "The CRC is defined as follows: • Length: 8 bits • Polynomial: x^8+x^5+x^3+x^2+x+1 • Initial Value: FFh • Input Data Reflection: Not reflected • Result Data Refl…";
CM_ SG_ 2365289726 MtrGnrtr1InvrtrStts1Cntr "The message counter is used to detect situations where the transmitting ECU malfunction repeats the same frame all the time. The receiver of the information may…";
CM_ SG_ 2365289726 MotorGenerator1Torque "The measured or estimated motor torque.  This refers to the motor rotor output and excludes any gearbox that may be attached to the motor.Refer to SPN 10170 [Re…";
CM_ SG_ 2365289726 MotorGenerator1Speed "The measured or estimated motor speed.  This refers to the motor rotor output and excludes any gearbox that may be attached to the motor.   Refer to SPN 10171 […";
CM_ SG_ 2365289726 MtrGnrtr1InvrtrDCSdVltg "The measured or estimated DC side voltage.  Refer to SPN 10203 [Reference Voltage] to convert % to Volts.…";
CM_ BO_ 2365289982 "Motor/Generator 1 Inverter Reference 1";
CM_ SG_ 2365289982 MtrGnrtr1InvrtrRfrn1CRC "The CRC is defined as follows: • Length: 8 bits • Polynomial: x^8+x^5+x^3+x^2+x+1 • Initial Value: FFh • Input Data Reflection: Not reflected • Result Data Refl…";
CM_ SG_ 2365289982 MtrGnrtr1InvrtrRfrn1Cntr "The message counter is used to detect situations where the transmitting ECU malfunction repeats the same frame all the time. The receiver of the information may…";
CM_ SG_ 2365289982 MtrGnrtr1InvrtrRfrnTrq "This value is used for converting torque in percent to units of Nm.Value in Nm = (Percent Value)/(100%) * (Reference Torque)For example, if this parameter has a…";
CM_ SG_ 2365289982 MtrGnrtr1InvrtrRfrnSpd "This value is used for converting Speed in percent to units of rpm.Value in rpm = (Percent Value)/(100%) * (Reference Speed)For example, if this parameter has a…";
CM_ SG_ 2365289982 MtrGnrtr1InvrtrRfrnPwr "This value is used for converting power in percent to units of kW.  It is applicable to both mechanical and electrical power.(Value in kW) = (Percent Value)/(10…";
CM_ BO_ 2566616830 "Personnel Detect Status";
CM_ SG_ 2566616830 DetectionLocation1 "Identifies the location of the detection area associated with Zone Alarm Status 1 (SPN 10134) reported in the message. The detection location identifies a direc…";
CM_ SG_ 2566616830 DetectionZone1 "Identifies the detection zone associated with Zone Alarm Status 1 (SPN 10134) reported in the message. A detection zone identifies spatial area within the detec…";
CM_ SG_ 2566616830 ZoneAlarmStatus1 "Indicates the alarm status for detection of personnel within the detection zone identified by Detection Zone 1 (SPN 10132) and Detection Location 1 (SPN 10133).…";
CM_ SG_ 2566616830 DetectionLocation2 "Identifies the location of the detection area associated with Zone Alarm Status 2 (SPN 10137) reported in the message. The detection location identifies a direc…";
CM_ SG_ 2566616830 DetectionZone2 "Identifies the detection zone associated with Zone Alarm Status 2 (SPN 10137) reported in the message. A detection zone identifies spatial area within the detec…";
CM_ SG_ 2566616830 ZoneAlarmStatus2 "Indicates the alarm status for detection of personnel within the detection zone identified by Detection Zone 2 (SPN 10135) and Detection Location 2 (SPN 10136).…";
CM_ SG_ 2566616830 DetectionLocation3 "Identifies the location of the detection area associated with Zone Alarm Status 3 (SPN 10140) reported in the message. The detection location identifies a direc…";
CM_ SG_ 2566616830 DetectionZone3 "Identifies the detection zone associated with Zone Alarm Status 3 (SPN 10140) reported in the message. A detection zone identifies spatial area within the detec…";
CM_ SG_ 2566616830 ZoneAlarmStatus3 "Indicates the alarm status for detection of personnel within the detection zone identified by Detection Zone 3 (SPN 10138) and Detection Location 3 (SPN 10139).…";
CM_ SG_ 2566616830 PersonnelDetectSequenceCounter "A counter value which increments per each transmission of data. If Personnel Detect Status consists of multiple messages then each message in the group shall sh…";
CM_ BO_ 2566617086 "Engine Cylinder Pressure Gamma 1";
CM_ SG_ 2566617086 EngnClndr1CmprssnGmmRt "The compression gamma ratio is defined as Log(pressure)/Log(volume) of the cylinder pressure curve during the compression stroke of the current engine cycle for…";
CM_ SG_ 2566617086 EngnClndr1ExpnsnGmmRt "The expansion gamma ratio is defined as Log(pressure)/Log(volume) of the cylinder pressure curve during the expansion stroke of the current engine cycle for eng…";
CM_ SG_ 2566617086 EngnClndr2CmprssnGmmRt "The compression gamma ratio is defined as Log(pressure)/Log(volume) of the cylinder pressure curve during the compression stroke of the current engine cycle for…";
CM_ SG_ 2566617086 EngnClndr2ExpnsnGmmRt "The expansion gamma ratio is defined as Log(pressure)/Log(volume) of the cylinder pressure curve during the expansion stroke of the current engine cycle for eng…";
CM_ SG_ 2566617086 EngnClndr3CmprssnGmmRt "The compression gamma ratio is defined as Log(pressure)/Log(volume) of the cylinder pressure curve during the compression stroke of the current engine cycle for…";
CM_ SG_ 2566617086 EngnClndr3ExpnsnGmmRt "The expansion gamma ratio is defined as Log(pressure)/Log(volume) of the cylinder pressure curve during the expansion stroke of the current engine cycle for eng…";
CM_ SG_ 2566617086 EngnClndr4CmprssnGmmRt "The compression gamma ratio is defined as Log(pressure)/Log(volume) of the cylinder pressure curve during the compression stroke of the current engine cycle for…";
CM_ SG_ 2566617086 EngnClndr4ExpnsnGmmRt "The expansion gamma ratio is defined as Log(pressure)/Log(volume) of the cylinder pressure curve during the expansion stroke of the current engine cycle for eng…";
CM_ BO_ 2566617342 "Engine Cylinder Pressure Gamma 2";
CM_ SG_ 2566617342 EngnClndr5CmprssnGmmRt "The compression gamma ratio is defined as Log(pressure)/Log(volume) of the cylinder pressure curve during the compression stroke of the current engine cycle for…";
CM_ SG_ 2566617342 EngnClndr5ExpnsnGmmRt "The expansion gamma ratio is defined as Log(pressure)/Log(volume) of the cylinder pressure curve during the expansion stroke of the current engine cycle for eng…";
CM_ SG_ 2566617342 EngnClndr6CmprssnGmmRt "The compression gamma ratio is defined as Log(pressure)/Log(volume) of the cylinder pressure curve during the compression stroke of the current engine cycle for…";
CM_ SG_ 2566617342 EngnClndr6ExpnsnGmmRt "The expansion gamma ratio is defined as Log(pressure)/Log(volume) of the cylinder pressure curve during the expansion stroke of the current engine cycle for eng…";
CM_ SG_ 2566617342 EngnClndr7CmprssnGmmRt "The compression gamma ratio is defined as Log(pressure)/Log(volume) of the cylinder pressure curve during the compression stroke of the current engine cycle for…";
CM_ SG_ 2566617342 EngnClndr7ExpnsnGmmRt "The expansion gamma ratio is defined as Log(pressure)/Log(volume) of the cylinder pressure curve during the expansion stroke of the current engine cycle for eng…";
CM_ SG_ 2566617342 EngnClndr8CmprssnGmmRt "The compression gamma ratio is defined as Log(pressure)/Log(volume) of the cylinder pressure curve during the compression stroke of the current engine cycle for…";
CM_ SG_ 2566617342 EngnClndr8ExpnsnGmmRt "The expansion gamma ratio is defined as Log(pressure)/Log(volume) of the cylinder pressure curve during the expansion stroke of the current engine cycle for eng…";
CM_ BO_ 2566617598 "Engine Cylinder Pressure Gamma 3";
CM_ SG_ 2566617598 EngnClndr9CmprssnGmmRt "The compression gamma ratio is defined as Log(pressure)/Log(volume) of the cylinder pressure curve during the compression stroke of the current engine cycle for…";
CM_ SG_ 2566617598 EngnClndr9ExpnsnGmmRt "The expansion gamma ratio is defined as Log(pressure)/Log(volume) of the cylinder pressure curve during the expansion stroke of the current engine cycle for eng…";
CM_ SG_ 2566617598 EngnClndr10CmprssnGmmRt "The compression gamma ratio is defined as Log(pressure)/Log(volume) of the cylinder pressure curve during the compression stroke of the current engine cycle for…";
CM_ SG_ 2566617598 EngnClndr10ExpnsnGmmRt "The expansion gamma ratio is defined as Log(pressure)/Log(volume) of the cylinder pressure curve during the expansion stroke of the current engine cycle for eng…";
CM_ SG_ 2566617598 EngnClndr11CmprssnGmmRt "The compression gamma ratio is defined as Log(pressure)/Log(volume) of the cylinder pressure curve during the compression stroke of the current engine cycle for…";
CM_ SG_ 2566617598 EngnClndr11ExpnsnGmmRt "The expansion gamma ratio is defined as Log(pressure)/Log(volume) of the cylinder pressure curve during the expansion stroke of the current engine cycle for eng…";
CM_ SG_ 2566617598 EngnClndr12CmprssnGmmRt "The compression gamma ratio is defined as Log(pressure)/Log(volume) of the cylinder pressure curve during the compression stroke of the current engine cycle for…";
CM_ SG_ 2566617598 EngnClndr12ExpnsnGmmRt "The expansion gamma ratio is defined as Log(pressure)/Log(volume) of the cylinder pressure curve during the expansion stroke of the current engine cycle for eng…";
CM_ BO_ 2566617854 "Engine Cylinder Pressure Gamma 4";
CM_ SG_ 2566617854 EngnClndr13CmprssnGmmRt "The compression gamma ratio is defined as Log(pressure)/Log(volume) of the cylinder pressure curve during the compression stroke of the current engine cycle for…";
CM_ SG_ 2566617854 EngnClndr13ExpnsnGmmRt "The expansion gamma ratio is defined as Log(pressure)/Log(volume) of the cylinder pressure curve during the expansion stroke of the current engine cycle for eng…";
CM_ SG_ 2566617854 EngnClndr14CmprssnGmmRt "The compression gamma ratio is defined as Log(pressure)/Log(volume) of the cylinder pressure curve during the compression stroke of the current engine cycle for…";
CM_ SG_ 2566617854 EngnClndr14ExpnsnGmmRt "The expansion gamma ratio is defined as Log(pressure)/Log(volume) of the cylinder pressure curve during the expansion stroke of the current engine cycle for eng…";
CM_ SG_ 2566617854 EngnClndr15CmprssnGmmRt "The compression gamma ratio is defined as Log(pressure)/Log(volume) of the cylinder pressure curve during the compression stroke of the current engine cycle for…";
CM_ SG_ 2566617854 EngnClndr15ExpnsnGmmRt "The expansion gamma ratio is defined as Log(pressure)/Log(volume) of the cylinder pressure curve during the expansion stroke of the current engine cycle for eng…";
CM_ SG_ 2566617854 EngnClndr16CmprssnGmmRt "The compression gamma ratio is defined as Log(pressure)/Log(volume) of the cylinder pressure curve during the compression stroke of the current engine cycle for…";
CM_ SG_ 2566617854 EngnClndr16ExpnsnGmmRt "The expansion gamma ratio is defined as Log(pressure)/Log(volume) of the cylinder pressure curve during the expansion stroke of the current engine cycle for eng…";
CM_ BO_ 2566618110 "Engine Cylinder Pressure Gamma 5";
CM_ SG_ 2566618110 EngnClndr17CmprssnGmmRt "The compression gamma ratio is defined as Log(pressure)/Log(volume) of the cylinder pressure curve during the compression stroke of the current engine cycle for…";
CM_ SG_ 2566618110 EngnClndr17ExpnsnGmmRt "The expansion gamma ratio is defined as Log(pressure)/Log(volume) of the cylinder pressure curve during the expansion stroke of the current engine cycle for eng…";
CM_ SG_ 2566618110 EngnClndr18CmprssnGmmRt "The compression gamma ratio is defined as Log(pressure)/Log(volume) of the cylinder pressure curve during the compression stroke of the current engine cycle for…";
CM_ SG_ 2566618110 EngnClndr18ExpnsnGmmRt "The expansion gamma ratio is defined as Log(pressure)/Log(volume) of the cylinder pressure curve during the expansion stroke of the current engine cycle for eng…";
CM_ SG_ 2566618110 EngnClndr19CmprssnGmmRt "The compression gamma ratio is defined as Log(pressure)/Log(volume) of the cylinder pressure curve during the compression stroke of the current engine cycle for…";
CM_ SG_ 2566618110 EngnClndr19ExpnsnGmmRt "The expansion gamma ratio is defined as Log(pressure)/Log(volume) of the cylinder pressure curve during the expansion stroke of the current engine cycle for eng…";
CM_ SG_ 2566618110 EngnClndr20CmprssnGmmRt "The compression gamma ratio is defined as Log(pressure)/Log(volume) of the cylinder pressure curve during the compression stroke of the current engine cycle for…";
CM_ SG_ 2566618110 EngnClndr20ExpnsnGmmRt "The expansion gamma ratio is defined as Log(pressure)/Log(volume) of the cylinder pressure curve during the expansion stroke of the current engine cycle for eng…";
CM_ BO_ 2566618622 "Electrified Accessory Generator Coolant Pump Status";
CM_ SG_ 2566618622 GnrtrClntPmpEnlStts "Enable and direction status of the Generator Coolant Pump system or component.00b = Accessory Motor Off01b = Accessory Motor On - Normal, Forward, or Default Di…";
CM_ SG_ 2566618622 GnrtrClntPmpCntrllrSttsRsnCd "Provides the reason code describing the unique failure of the Generator Coolant Pump system or component.If a detailed reason code is not used by the supporting…";
CM_ SG_ 2566618622 GnrtrClntPmpCntrllrCmmndStts "Indicates the source of the speed command to the Generator Coolant Pump system or component.00b is communicated when the controller is self-controlled (e.g. bas…";
CM_ SG_ 2566618622 GeneratorCoolantPumpMotorSpeed "Motor Speed of the Generator Coolant Pump.…";
CM_ SG_ 2566618622 GnrtrClntPmpCntrlTmprtr "A temperature measured and reported by the device.  It may be used for direct or remote (e.g. by another controller) control of the pump.  For example, this may…";
CM_ SG_ 2566618622 GeneratorCoolantPumpPower "Calculated electrical power consumed by the Generator Coolant Pump.…";
CM_ SG_ 2566618622 GnrtrClntPmpSrvIndtr "Indicates that service is required for the Generator Coolant Pump system or component.  An active indication may convey a need for component replacement or peri…";
CM_ SG_ 2566618622 GnrtrClntPmpOprtngStts "Indicates the operating status of the Generator Coolant Pump system or component.  This parameter is used to inform other devices that this system or component …";
CM_ BO_ 2566618878 "Electrified Accessory Generator Coolant Fan Status";
CM_ SG_ 2566618878 GeneratorCoolantFanEnableStatus "Enable and direction status of this Generator Coolant Fan Motor system or component.00b = Accessory Motor Off01b = Accessory Motor On - Normal, Forward, or Defa…";
CM_ SG_ 2566618878 GnrtrClntFnCntrllrSttsRsnCd "Provides the reason code describing the unique failure of this Generator Coolant Fan Motor system or component.If a detailed reason code is not used by the supp…";
CM_ SG_ 2566618878 GnrtrClntFnCntrllrCmmndStts "Indicates the source of the speed command to this Generator Coolant Fan system or component.00b is communicated when the controller is self-controlled (e.g. bas…";
CM_ SG_ 2566618878 GeneratorCoolantFanMotorSpeed "Motor Speed of the Generator Coolant Fan.…";
CM_ SG_ 2566618878 GnrtrClntFnCntrlTmprtr "A temperature measured and reported by the device.  It may be used for direct or remote (e.g. by another controller) control of the pump.  For example, this may…";
CM_ SG_ 2566618878 GeneratorCoolantFanPower "Calculated electrical power consumed by the Generator Coolant Fan.…";
CM_ SG_ 2566618878 GnrtrClntFnSrvIndtr "Indicates that service is required for the Generator Coolant Fan system or component.  An active indication may convey a need for component replacement or perio…";
CM_ SG_ 2566618878 GnrtrClntFnOprtngStts "Indicates the operating status of the Generator Coolant Fan system or component.  This parameter is used to inform other devices that this system or component i…";
CM_ BO_ 2566619134 "Well Stimulation Pump System Filter Information";
CM_ SG_ 2566619134 WllStmltnPmpOlFltrDffrntlPrssr "Change in pump gear box oil pressure, measured across the filter, due to the filter and any accumulation of solid or semisolid material on or in the filter. The…";
CM_ SG_ 2566619134 WllStmltnPmpOlFltrOtltPrssr "Pump Oil pressure (gage) measured just downstream of oil filter.…";
CM_ SG_ 2566619134 WllStmltnPmpOlFltrBpssSwthStts "Displays Pump Oil Filter Switch Status00b = Not bypassing01b = Bypassing10b = Error11b = Not available…";
CM_ BO_ 2566619390 "PTO Governor Configuration";
CM_ SG_ 2566619390 PrprgrmmdPTOGvrnrStSpd1 "This speed corresponds to the PTO governed speed when PTO Governor State (SPN 976) is equal to Preprogrammed PTO Governor Set Speed 1 (01010b).…";
CM_ SG_ 2566619390 PrprgrmmdPTOGvrnrStSpd2 "This speed corresponds to the PTO governed speed when PTO Governor State (SPN 976) is equal to Preprogrammed PTO Governor Set Speed 2 (01011b).…";
CM_ SG_ 2566619390 PrprgrmmdPTOGvrnrStSpd3 "This speed corresponds to the PTO governed speed when PTO Governor State (SPN 976) is equal to Preprogrammed PTO Governor Set Speed 3 (01100b).…";
CM_ SG_ 2566619390 PrprgrmmdPTOGvrnrStSpd4 "This speed corresponds to the PTO governed speed when PTO Governor State (SPN 976) is equal to Preprogrammed PTO Governor Set Speed 4 (01101b).…";
CM_ SG_ 2566619390 PrprgrmmdPTOGvrnrStSpd5 "This speed corresponds to the PTO governed speed when PTO Governor State (SPN 976) is equal to Preprogrammed PTO Governor Set Speed 5 (01110b).…";
CM_ SG_ 2566619390 PrprgrmmdPTOGvrnrStSpd6 "This speed corresponds to the PTO governed speed when PTO Governor State (SPN 976) is equal to Preprogrammed PTO Governor Set Speed 6 (01111b).…";
CM_ SG_ 2566619390 PrprgrmmdPTOGvrnrStSpd7 "This speed corresponds to the PTO governed speed when PTO Governor State (SPN 976) is equal to Preprogrammed PTO Governor Set Speed 7 (10000b).…";
CM_ SG_ 2566619390 PrprgrmmdPTOGvrnrStSpd8 "This speed corresponds to the PTO governed speed when PTO Governor State (SPN 976) is equal to Preprogrammed PTO Governor Set Speed 8 (10001b).…";
CM_ SG_ 2566619390 MinimumPTOGovernorSetSpeed "The minimum allowed engine speed (user programmable) in which preprogrammed PTO governor set speeds 1-8 can be set.…";
CM_ SG_ 2566619390 MaximumPTOGovernorSetSpeed "The maximum allowed engine speed (user programmable) in which preprogrammed PTO governor set speeds 1-8 can be set.…";
CM_ SG_ 2566619390 PTOGvrnrAlrtrOvrrdMxmmSpd "The maximum engine speed allowed while accelerator pedal is overriding the PTO governor.…";
CM_ BO_ 2566619646 "On Board Programming 2";
CM_ SG_ 2566619646 OnBrdPrgrmmngInttECUAddrss "Source address of target device for which on board programming is to be initiated. Source addresses 254 and 255 are not valid.…";
CM_ SG_ 2566619646 OnBrdPrgrmmngInttRqst "Signal indicating that programming should be initiated. Could come from operator controls or target device. Actual initiation may be subject to, or delayed by, …";
CM_ SG_ 2566619646 OnBrdPrgrmmngInttInht "Indicates that programming is inhibited. Signal should be used by the target to prevent being programmed, or by the operator to decline/cancel programming.00b =…";
CM_ BO_ 2566620670 "Engine Idle Management Information";
CM_ SG_ 2566620670 EngineIdleManagementStatus "Indicates the current state or mode of operation by the engine idle manangement system.0000b = Off0001b = Locked0010b = Disabled0011b = Activation conditions no…";
CM_ SG_ 2566620670 EngnIdlMngmntRstrtRsn "Used to indicate the condition requesting the engine to restart when the idle management system is active.0000b = Operator input request0001b = Low engine coola…";
CM_ SG_ 2566620670 EngnIdlMngmntShtdwnRsn "Used to indicate the condition requesting the engine to shutdown when the idle management system is active.0000b = Operator input request0001b = Engine coolant …";
CM_ SG_ 2566620670 IdlMngmntPndngEvntTmRmnng "Used to indicate the time remaining before the engine will start-up or shutdown as determined by the idle management controller. The time remaining can be used …";
CM_ BO_ 2566621438 "Marine Control Information 3";
CM_ SG_ 2566621438 StationThrottlePositionMatch "Indicates whether the throttle position at the currently selected station and the throttle lever position at the station where the transfer is occuring is withi…";
CM_ SG_ 2566621438 StationGearPositionMatch "Indicates whether the gear position at the currently selected station is in neutral and the gear lever position at the station where the transfer is occuring is…";
CM_ SG_ 2566621438 OprtrSttnAtvBttnStts "The button used to request a station to become the active station when another station is currently in control.00b = Button not pressed01b = Button pressed10b =…";
CM_ SG_ 2566621438 TrollingModeButtonStatus "The button used to change the current type of trolling mode that is selected.00b = Button not pressed01b = Button pressed10b = Error11b = Not Available…";
CM_ SG_ 2566621438 EngnThrttlLvrSnhrnztnBttnStts "The button that is used to enable or disable syncronization of the engine throttles. When synchronization mode is activated, an operator uses one throttle lever…";
CM_ SG_ 2566621438 GearLockoutButtonStatus "This button is used to prevent the transmissions from being shifted into gear. When the button is pressed, the transmissions will be locked in neutral.00b = But…";
CM_ SG_ 2566621438 SlowVesselModeButtonStatus "Reports when the slow vessel mode button has been pressed.00b = Button not pressed01b = Button pressed10b = Error11b = Not Available…";
CM_ SG_ 2566621438 OperatorStationActiveLampStatus "Reports when the operator station active lamp is illuminated.00b = Off01b = On10b = Error11b = Not Available…";
CM_ SG_ 2566621438 TrollingModeLampStatus "Reports when the trolling mode lamp is illuminated.00b = Off01b = On10b = Error11b = Not Available…";
CM_ SG_ 2566621438 EngnThrttlLvrSnhrnztnLmpStts "Reports when the throttle lever synchronization lamp is illuminated. When synchronization mode is activated, an operator uses one throttle lever to control the …";
CM_ SG_ 2566621438 GearLockoutLampStatus "Reports when the gear lockout lamp is illuminated.00b = Off01b = On10b = Error11b = Not Available…";
CM_ SG_ 2566621438 SlowVesselModeLampStatus "Reports when the slow vessel mode lamp is illuminated.00b = Off01b = On10b = Error11b = Not Available…";
CM_ BO_ 2566621694 "Engine Fluid Level/Pressure 13";
CM_ SG_ 2566621694 EngineOilPressure2 "Gage pressure of oil in engine lubrication system as provided by oil pump - second instance.…";
CM_ BO_ 2365295358 "High Voltage Energy Storage 1 Data 11";
CM_ SG_ 2365295358 HVES1BsVltgNgtvtChsssGrndVltg "Voltage difference between the most negative terminal of the HVES battery and chassis measured on the hybrid system bus side (not the battery side) of any HVES …";
CM_ SG_ 2365295358 HVES1VltgLvlNgtvtChsssGrndVltg "Voltage difference between the most negative terminal of the HVES battery and chassis measured at the battery side of any HVES contained output contactor.  This…";
CM_ BO_ 2566622206 "Economy Mode Inactive Hours";
CM_ SG_ 2566622206 EconomyModeTotalHoursInactive "Total accumulated operating time while economy mode is installed but not in use.…";
CM_ SG_ 2566622206 EconomyModeTripHoursInactive "Trip operating time accumulated while economy mode is installed but not in use, since last trip reset.…";
CM_ BO_ 2566622462 "Economy Mode Estimated Instantaneous Fuel Savings Rate";
CM_ SG_ 2566622462 EnmMdEstmtdInstntnsFlSvngsRt "Estimated instantaneous fuel savings rate while operating in economy mode.  This is in comparison to operating in a non-economy mode.…";
CM_ SG_ 2566622462 EMdEsttdIsttsFSvsRtPt "Estimated instantaneous fuel savings rate percentage while operating in economy mode. This value is calculated by dividing Economy Mode Estimated Instantaneous …";
CM_ BO_ 2566622718 "Economy Mode Active Hours";
CM_ SG_ 2566622718 EconomyModeTotalHoursActive "Total accumulated operating time in economy mode over the lifetime of the application.…";
CM_ SG_ 2566622718 EconomyModeTripHoursActive "Total accumulated operating time in economy mode since the last trip reset.…";
CM_ BO_ 2566622974 "Economy Mode Fuel Used";
CM_ SG_ 2566622974 EconomyModeTotalFuelUsed "Total volume of fuel used during economy mode operation over the lifetime of the application.…";
CM_ SG_ 2566622974 EconomyModeTripFuelUsed "Total volume of fuel used during all or part of a journey while operating in economy mode, since the last trip reset.…";
CM_ BO_ 2566623230 "Economy Mode Estimated Fuel Savings";
CM_ SG_ 2566623230 EnmMdTtlEstmtdFlSvd "Total volume of estimated fuel saved during economy mode of operation over the lifetime of the application. This is in comparison to operating in a non-economy …";
CM_ SG_ 2566623230 EnmMdTrpEstmtdFlSvd "Total volume of estimated fuel saved during all or part of a journey while operating in economy mode, since the last trip reset. This is in comparison to operat…";
BA_DEF_ SG_  "SPN" INT 0 524287;
BA_DEF_ BO_  "VFrameFormat" ENUM  "StandardCAN","ExtendedCAN","reserved","J1939PG";
BA_DEF_DEF_  "SPN" 0;
BA_DEF_DEF_  "VFrameFormat" "J1939PG";
BA_ "SPN" SG_ 2556493566 MtrGnrtr1InvrtrLmtsRqstPwrCRC 10176;
BA_ "SPN" SG_ 2556493566 MtrGnrtr1InvrtrLmtsRqstPwrCntr 10177;
BA_ "SPN" SG_ 2556559102 PrsnnlDttAlrmRvStts 10142;
BA_ "SPN" SG_ 2556559102 PrsnnlDttSqnCntrEh 10143;
BA_ "SPN" SG_ 2556624638 CnfgrdEngnClndrMssFrtnBrndLtn1 9935;
BA_ "SPN" SG_ 2556624638 CnfgrdEngnClndrMssFrtnBrndLtn2 9936;
BA_ "SPN" SG_ 2556690174 EngnClndrMssFrtnBrndLtn1 9933;
BA_ "SPN" SG_ 2556690174 EngnClndrMssFrtnBrndLtn2 9934;
BA_ "SPN" SG_ 2556755710 CnfgrdEngnClndrPrssrTmng1 9845;
BA_ "SPN" SG_ 2556755710 CnfgrdEngnClndrPrssrTmng2 9846;
BA_ "SPN" SG_ 2556755710 CnfgrdEngnClndrPrssrTmng3 9847;
BA_ "SPN" SG_ 2556755710 CnfgrdEngnClndrPrssrTmng4 9848;
BA_ "SPN" SG_ 2556821246 EngineCylinderPressureTiming1 9849;
BA_ "SPN" SG_ 2556821246 EngineCylinderPressureTiming2 9850;
BA_ "SPN" SG_ 2556821246 EngineCylinderPressureTiming3 9851;
BA_ "SPN" SG_ 2556821246 EngineCylinderPressureTiming4 9852;
BA_ "SPN" SG_ 2556886782 GnrtrClntPmpEnlCmmnd 9829;
BA_ "SPN" SG_ 2556886782 GeneratorCoolantPumpPowerHold 9830;
BA_ "SPN" SG_ 2556886782 GnrtrClntPmpSpdCmmnd 9831;
BA_ "SPN" SG_ 2556886782 GnrtrClntPmpPrntSpdCmmnd 9832;
BA_ "SPN" SG_ 2556952318 GnrtrClntFnEnlCmmnd 9816;
BA_ "SPN" SG_ 2556952318 GeneratorCoolantFanPowerHold 9817;
BA_ "SPN" SG_ 2556952318 GeneratorCoolantFanSpeedCommand 9818;
BA_ "SPN" SG_ 2556952318 GnrtrClntFnPrntSpdCmmnd 9819;
BA_ "SPN" SG_ 2557017854 OnBrdPrgrmmngTrgtECUAddrss 9766;
BA_ "SPN" SG_ 2557017854 OnBoardProgrammingStatus 9767;
BA_ "SPN" SG_ 2557017854 OBPInterlockOverallStatus 9768;
BA_ "SPN" SG_ 2557017854 OBPInterlockEngineSpeed 9769;
BA_ "SPN" SG_ 2557017854 OBPInterlockKeySwitchPosition 9770;
BA_ "SPN" SG_ 2557017854 OBPInterlockParkBrake 9771;
BA_ "SPN" SG_ 2557017854 OBPIntrlkPwrSpplInsffnt 9772;
BA_ "SPN" SG_ 2557017854 OBPInterlockTargetNotReady 9773;
BA_ "SPN" SG_ 2557017854 OBPKeySwitchRequest 9775;
BA_ "SPN" SG_ 2557017854 OnBoardProgrammingProgress 9774;
BA_ "SPN" SG_ 2557083390 OperatorStationLocationSetting 9661;
BA_ "SPN" SG_ 2557083390 TrollingModeSettingCommand 9662;
BA_ "SPN" SG_ 2557083390 EngnThrttlSnhrnztnMdCmmnd 9663;
BA_ "SPN" SG_ 2557083390 EngineTrollingModeSetSpeed 9664;
BA_ "SPN" SG_ 2557148926 OprtrSttnInCntrlLtn 9654;
BA_ "SPN" SG_ 2557148926 OperatorStationLockout 9655;
BA_ "SPN" SG_ 2557148926 EngnThrttlSnhrnztnMdCrrntSttng 9656;
BA_ "SPN" SG_ 2557148926 TrollingModeExtendedRange 9657;
BA_ "SPN" SG_ 2557148926 TrollingModeCurrentSetting 9658;
BA_ "SPN" SG_ 2557148926 VesselEngineSetSpeed 9659;
BA_ "SPN" SG_ 2557148926 VesselSpeedControlMode 9660;
BA_ "SPN" SG_ 2364617726 EngnPrChmrFlVlv1Drtn 9591;
BA_ "SPN" SG_ 2364617726 EngnPrChmrFlVlv2Drtn 9592;
BA_ "SPN" SG_ 2364617726 EngnPrChmrFlVlv3Drtn 9593;
BA_ "SPN" SG_ 2364617726 EngnPrChmrFlVlv4Drtn 9594;
BA_ "SPN" SG_ 2364617982 EngnPrChmrFlVlv5Drtn 9595;
BA_ "SPN" SG_ 2364617982 EngnPrChmrFlVlv6Drtn 9596;
BA_ "SPN" SG_ 2364617982 EngnPrChmrFlVlv7Drtn 9597;
BA_ "SPN" SG_ 2364617982 EngnPrChmrFlVlv8Drtn 9598;
BA_ "SPN" SG_ 2364618238 EngnPrChmrFlVlv9Drtn 9599;
BA_ "SPN" SG_ 2364618238 EngnPrChmrFlVlv10Drtn 9600;
BA_ "SPN" SG_ 2364618238 EngnPrChmrFlVlv11Drtn 9601;
BA_ "SPN" SG_ 2364618238 EngnPrChmrFlVlv12Drtn 9602;
BA_ "SPN" SG_ 2364618494 EngnPrChmrFlVlv13Drtn 9603;
BA_ "SPN" SG_ 2364618494 EngnPrChmrFlVlv14Drtn 9604;
BA_ "SPN" SG_ 2364618494 EngnPrChmrFlVlv15Drtn 9605;
BA_ "SPN" SG_ 2364618494 EngnPrChmrFlVlv16Drtn 9606;
BA_ "SPN" SG_ 2364618750 EngnPrChmrFlVlv17Drtn 9607;
BA_ "SPN" SG_ 2364618750 EngnPrChmrFlVlv18Drtn 9608;
BA_ "SPN" SG_ 2364618750 EngnPrChmrFlVlv19Drtn 9609;
BA_ "SPN" SG_ 2364618750 EngnPrChmrFlVlv20Drtn 9610;
BA_ "SPN" SG_ 2364619006 EngnPrChmrFlVlv1StrtfAttnCmmnd 9611;
BA_ "SPN" SG_ 2364619006 EngnPrChmrFlVlv2StrtfAttnCmmnd 9612;
BA_ "SPN" SG_ 2364619006 EngnPrChmrFlVlv3StrtfAttnCmmnd 9613;
BA_ "SPN" SG_ 2364619006 EngnPrChmrFlVlv4StrtfAttnCmmnd 9614;
BA_ "SPN" SG_ 2364619262 EngnPrChmrFlVlv5StrtfAttnCmmnd 9615;
BA_ "SPN" SG_ 2364619262 EngnPrChmrFlVlv6StrtfAttnCmmnd 9616;
BA_ "SPN" SG_ 2364619262 EngnPrChmrFlVlv7StrtfAttnCmmnd 9617;
BA_ "SPN" SG_ 2364619262 EngnPrChmrFlVlv8StrtfAttnCmmnd 9618;
BA_ "SPN" SG_ 2364619518 EngnPrChmrFlVlv9StrtfAttnCmmnd 9619;
BA_ "SPN" SG_ 2364619518 EngnPrChmrFlVlv10StrtfAttnCmmnd 9620;
BA_ "SPN" SG_ 2364619518 EngnPrChmrFlVlv11StrtfAttnCmmnd 9621;
BA_ "SPN" SG_ 2364619518 EngnPrChmrFlVlv12StrtfAttnCmmnd 9622;
BA_ "SPN" SG_ 2364619774 EngnPrChmrFlVlv13StrtfAttnCmmnd 9623;
BA_ "SPN" SG_ 2364619774 EngnPrChmrFlVlv14StrtfAttnCmmnd 9624;
BA_ "SPN" SG_ 2364619774 EngnPrChmrFlVlv15StrtfAttnCmmnd 9625;
BA_ "SPN" SG_ 2364619774 EngnPrChmrFlVlv16StrtfAttnCmmnd 9626;
BA_ "SPN" SG_ 2364620030 EngnPrChmrFlVlv17StrtfAttnCmmnd 9627;
BA_ "SPN" SG_ 2364620030 EngnPrChmrFlVlv18StrtfAttnCmmnd 9628;
BA_ "SPN" SG_ 2364620030 EngnPrChmrFlVlv19StrtfAttnCmmnd 9629;
BA_ "SPN" SG_ 2364620030 EngnPrChmrFlVlv20StrtfAttnCmmnd 9630;
BA_ "SPN" SG_ 2364620286 LnKpngAssstSttsRghtSd 9753;
BA_ "SPN" SG_ 2364620286 LaneKeepingAssistStatusLeftSide 9754;
BA_ "SPN" SG_ 2364620286 LnKpngAssstIndtnEnlStts 9755;
BA_ "SPN" SG_ 2364620286 LaneKeepingAssistSystemState 9756;
BA_ "SPN" SG_ 2364620286 ActiveSteeringDriverPreference 9757;
BA_ "SPN" SG_ 2364620286 LnCntrngIndtnEnlStt 9758;
BA_ "SPN" SG_ 2364620286 LaneCenteringSystemStatus 9759;
BA_ "SPN" SG_ 2364621054 SttnrInvrtrAvrgACRMSVltg 9794;
BA_ "SPN" SG_ 2364621054 SttnrInvrtrAvrgLnNtrlACRMSVltg 9795;
BA_ "SPN" SG_ 2364621054 SttnrInvrtrAvrgACFrqn 9796;
BA_ "SPN" SG_ 2364621054 SttnrInvrtrAvrgACRMSCrrnt 9797;
BA_ "SPN" SG_ 2364621310 SttnrInvrtrTtlRtvPwr 9798;
BA_ "SPN" SG_ 2364621310 SttnrInvrtrOvrllPwrFtr 9799;
BA_ "SPN" SG_ 2364621310 SttnrInvrtrOvrllPwrFtrLggng 9800;
BA_ "SPN" SG_ 2364621566 SttnrInvrtrTtlRlPwr 9801;
BA_ "SPN" SG_ 2364621566 SttnrInvrtrTtlApprntPwr 9802;
BA_ "SPN" SG_ 2364621822 SttnrInvrtrNtRdtAtmtllPrlllStt 9803;
BA_ "SPN" SG_ 2364621822 SttnrInvrtrAxlrShtdwnSwth 9804;
BA_ "SPN" SG_ 2364622078 StationaryInvertertoBusDeadBus 9806;
BA_ "SPN" SG_ 2364622078 SttnrInvrtrtBsPhsMth 9807;
BA_ "SPN" SG_ 2364622078 SttnrInvrtrtBsFrqnMth 9808;
BA_ "SPN" SG_ 2364622078 SttnrInvrtrtBsVltgMth 9809;
BA_ "SPN" SG_ 2364622078 StationaryInvertertoBusInSync 9810;
BA_ "SPN" SG_ 2364622078 SttnrInvrtrtBsACPhsDffrn 9811;
BA_ "SPN" SG_ 2364622334 EngineCylinder1Timing1Pressure 9853;
BA_ "SPN" SG_ 2364622334 EngineCylinder1Timing2Pressure 9854;
BA_ "SPN" SG_ 2364622334 EngineCylinder1Timing3Pressure 9855;
BA_ "SPN" SG_ 2364622334 EngineCylinder1Timing4Pressure 9856;
BA_ "SPN" SG_ 2364622590 EngineCylinder2Timing1Pressure 9857;
BA_ "SPN" SG_ 2364622590 EngineCylinder2Timing2Pressure 9858;
BA_ "SPN" SG_ 2364622590 EngineCylinder2Timing3Pressure 9859;
BA_ "SPN" SG_ 2364622590 EngineCylinder2Timing4Pressure 9860;
BA_ "SPN" SG_ 2364622846 EngineCylinder3Timing1Pressure 9861;
BA_ "SPN" SG_ 2364622846 EngineCylinder3Timing2Pressure 9862;
BA_ "SPN" SG_ 2364622846 EngineCylinder3Timing3Pressure 9863;
BA_ "SPN" SG_ 2364622846 EngineCylinder3Timing4Pressure 9864;
BA_ "SPN" SG_ 2364623102 EngineCylinder4Timing1Pressure 9865;
BA_ "SPN" SG_ 2364623102 EngineCylinder4Timing2Pressure 9866;
BA_ "SPN" SG_ 2364623102 EngineCylinder4Timing3Pressure 9867;
BA_ "SPN" SG_ 2364623102 EngineCylinder4Timing4Pressure 9868;
BA_ "SPN" SG_ 2364623358 EngineCylinder5Timing1Pressure 9869;
BA_ "SPN" SG_ 2364623358 EngineCylinder5Timing2Pressure 9870;
BA_ "SPN" SG_ 2364623358 EngineCylinder5Timing3Pressure 9871;
BA_ "SPN" SG_ 2364623358 EngineCylinder5Timing4Pressure 9872;
BA_ "SPN" SG_ 2364623614 EngineCylinder6Timing1Pressure 9873;
BA_ "SPN" SG_ 2364623614 EngineCylinder6Timing2Pressure 9874;
BA_ "SPN" SG_ 2364623614 EngineCylinder6Timing3Pressure 9875;
BA_ "SPN" SG_ 2364623614 EngineCylinder6Timing4Pressure 9876;
BA_ "SPN" SG_ 2364623870 EngineCylinder7Timing1Pressure 9877;
BA_ "SPN" SG_ 2364623870 EngineCylinder7Timing2Pressure 9878;
BA_ "SPN" SG_ 2364623870 EngineCylinder7Timing3Pressure 9879;
BA_ "SPN" SG_ 2364623870 EngineCylinder7Timing4Pressure 9880;
BA_ "SPN" SG_ 2364624126 EngineCylinder8Timing1Pressure 9881;
BA_ "SPN" SG_ 2364624126 EngineCylinder8Timing2Pressure 9882;
BA_ "SPN" SG_ 2364624126 EngineCylinder8Timing3Pressure 9883;
BA_ "SPN" SG_ 2364624126 EngineCylinder8Timing4Pressure 9884;
BA_ "SPN" SG_ 2364624382 EngineCylinder9Timing1Pressure 9885;
BA_ "SPN" SG_ 2364624382 EngineCylinder9Timing2Pressure 9886;
BA_ "SPN" SG_ 2364624382 EngineCylinder9Timing3Pressure 9887;
BA_ "SPN" SG_ 2364624382 EngineCylinder9Timing4Pressure 9888;
BA_ "SPN" SG_ 2364624638 EngineCylinder10Timing1Pressure 9889;
BA_ "SPN" SG_ 2364624638 EngineCylinder10Timing2Pressure 9890;
BA_ "SPN" SG_ 2364624638 EngineCylinder10Timing3Pressure 9891;
BA_ "SPN" SG_ 2364624638 EngineCylinder10Timing4Pressure 9892;
BA_ "SPN" SG_ 2364624894 EngineCylinder11Timing1Pressure 9893;
BA_ "SPN" SG_ 2364624894 EngineCylinder11Timing2Pressure 9894;
BA_ "SPN" SG_ 2364624894 EngineCylinder11Timing3Pressure 9895;
BA_ "SPN" SG_ 2364624894 EngineCylinder11Timing4Pressure 9896;
BA_ "SPN" SG_ 2364625150 EngineCylinder12Timing1Pressure 9897;
BA_ "SPN" SG_ 2364625150 EngineCylinder12Timing2Pressure 9898;
BA_ "SPN" SG_ 2364625150 EngineCylinder12Timing3Pressure 9899;
BA_ "SPN" SG_ 2364625150 EngineCylinder12Timing4Pressure 9900;
BA_ "SPN" SG_ 2364625406 EngineCylinder13Timing1Pressure 9901;
BA_ "SPN" SG_ 2364625406 EngineCylinder13Timing2Pressure 9902;
BA_ "SPN" SG_ 2364625406 EngineCylinder13Timing3Pressure 9903;
BA_ "SPN" SG_ 2364625406 EngineCylinder13Timing4Pressure 9904;
BA_ "SPN" SG_ 2364625662 EngineCylinder14Timing1Pressure 9905;
BA_ "SPN" SG_ 2364625662 EngineCylinder14Timing2Pressure 9906;
BA_ "SPN" SG_ 2364625662 EngineCylinder14Timing3Pressure 9907;
BA_ "SPN" SG_ 2364625662 EngineCylinder14Timing4Pressure 9908;
BA_ "SPN" SG_ 2364625918 EngineCylinder15Timing1Pressure 9909;
BA_ "SPN" SG_ 2364625918 EngineCylinder15Timing2Pressure 9910;
BA_ "SPN" SG_ 2364625918 EngineCylinder15Timing3Pressure 9911;
BA_ "SPN" SG_ 2364625918 EngineCylinder15Timing4Pressure 9912;
BA_ "SPN" SG_ 2364626174 EngineCylinder16Timing1Pressure 9913;
BA_ "SPN" SG_ 2364626174 EngineCylinder16Timing2Pressure 9914;
BA_ "SPN" SG_ 2364626174 EngineCylinder16Timing3Pressure 9915;
BA_ "SPN" SG_ 2364626174 EngineCylinder16Timing4Pressure 9916;
BA_ "SPN" SG_ 2364626430 EngineCylinder17Timing1Pressure 9917;
BA_ "SPN" SG_ 2364626430 EngineCylinder17Timing2Pressure 9918;
BA_ "SPN" SG_ 2364626430 EngineCylinder17Timing3Pressure 9919;
BA_ "SPN" SG_ 2364626430 EngineCylinder17Timing4Pressure 9920;
BA_ "SPN" SG_ 2364626686 EngineCylinder18Timing1Pressure 9921;
BA_ "SPN" SG_ 2364626686 EngineCylinder18Timing2Pressure 9922;
BA_ "SPN" SG_ 2364626686 EngineCylinder18Timing3Pressure 9923;
BA_ "SPN" SG_ 2364626686 EngineCylinder18Timing4Pressure 9924;
BA_ "SPN" SG_ 2364626942 EngineCylinder19Timing1Pressure 9925;
BA_ "SPN" SG_ 2364626942 EngineCylinder19Timing2Pressure 9926;
BA_ "SPN" SG_ 2364626942 EngineCylinder19Timing3Pressure 9927;
BA_ "SPN" SG_ 2364626942 EngineCylinder19Timing4Pressure 9928;
BA_ "SPN" SG_ 2364627198 EngineCylinder20Timing1Pressure 9929;
BA_ "SPN" SG_ 2364627198 EngineCylinder20Timing2Pressure 9930;
BA_ "SPN" SG_ 2364627198 EngineCylinder20Timing3Pressure 9931;
BA_ "SPN" SG_ 2364627198 EngineCylinder20Timing4Pressure 9932;
BA_ "SPN" SG_ 2364627454 ECd1IsttsSttCstT 9937;
BA_ "SPN" SG_ 2364627454 ECd1IsttsCtCstT 9938;
BA_ "SPN" SG_ 2364627454 EngnClndr1InstntnsCmstnTmngPnt1 9939;
BA_ "SPN" SG_ 2364627454 EngnClndr1InstntnsCmstnTmngPnt2 9940;
BA_ "SPN" SG_ 2364627710 ECd2IsttsSttCstT 9941;
BA_ "SPN" SG_ 2364627710 ECd2IsttsCtCstT 9942;
BA_ "SPN" SG_ 2364627710 EngnClndr2InstntnsCmstnTmngPnt1 9943;
BA_ "SPN" SG_ 2364627710 EngnClndr2InstntnsCmstnTmngPnt2 9944;
BA_ "SPN" SG_ 2364627966 ECd3IsttsSttCstT 9945;
BA_ "SPN" SG_ 2364627966 ECd3IsttsCtCstT 9946;
BA_ "SPN" SG_ 2364627966 EngnClndr3InstntnsCmstnTmngPnt1 9947;
BA_ "SPN" SG_ 2364627966 EngnClndr3InstntnsCmstnTmngPnt2 9948;
BA_ "SPN" SG_ 2364628222 ECd4IsttsSttCstT 9949;
BA_ "SPN" SG_ 2364628222 ECd4IsttsCtCstT 9950;
BA_ "SPN" SG_ 2364628222 EngnClndr4InstntnsCmstnTmngPnt1 9951;
BA_ "SPN" SG_ 2364628222 EngnClndr4InstntnsCmstnTmngPnt2 9952;
BA_ "SPN" SG_ 2364628478 ECd5IsttsSttCstT 9953;
BA_ "SPN" SG_ 2364628478 ECd5IsttsCtCstT 9954;
BA_ "SPN" SG_ 2364628478 EngnClndr5InstntnsCmstnTmngPnt1 9955;
BA_ "SPN" SG_ 2364628478 EngnClndr5InstntnsCmstnTmngPnt2 9956;
BA_ "SPN" SG_ 2364628734 ECd6IsttsSttCstT 9957;
BA_ "SPN" SG_ 2364628734 ECd6IsttsCtCstT 9958;
BA_ "SPN" SG_ 2364628734 EngnClndr6InstntnsCmstnTmngPnt1 9959;
BA_ "SPN" SG_ 2364628734 EngnClndr6InstntnsCmstnTmngPnt2 9960;
BA_ "SPN" SG_ 2364628990 ECd7IsttsSttCstT 9961;
BA_ "SPN" SG_ 2364628990 ECd7IsttsCtCstT 9962;
BA_ "SPN" SG_ 2364628990 EngnClndr7InstntnsCmstnTmngPnt1 9963;
BA_ "SPN" SG_ 2364628990 EngnClndr7InstntnsCmstnTmngPnt2 9964;
BA_ "SPN" SG_ 2364629246 ECd8IsttsSttCstT 9965;
BA_ "SPN" SG_ 2364629246 ECd8IsttsCtCstT 9966;
BA_ "SPN" SG_ 2364629246 EngnClndr8InstntnsCmstnTmngPnt1 9967;
BA_ "SPN" SG_ 2364629246 EngnClndr8InstntnsCmstnTmngPnt2 9968;
BA_ "SPN" SG_ 2364629502 ECd9IsttsSttCstT 9969;
BA_ "SPN" SG_ 2364629502 ECd9IsttsCtCstT 9970;
BA_ "SPN" SG_ 2364629502 EngnClndr9InstntnsCmstnTmngPnt1 9971;
BA_ "SPN" SG_ 2364629502 EngnClndr9InstntnsCmstnTmngPnt2 9972;
BA_ "SPN" SG_ 2364629758 ECd10IsttsSttCstT 9973;
BA_ "SPN" SG_ 2364629758 ECd10IsttsCtCstT 9974;
BA_ "SPN" SG_ 2364629758 ECd10IsttsCstTPt1 9975;
BA_ "SPN" SG_ 2364629758 ECd10IsttsCstTPt2 9976;
BA_ "SPN" SG_ 2364630014 ECd11IsttsSttCstT 9977;
BA_ "SPN" SG_ 2364630014 ECd11IsttsCtCstT 9978;
BA_ "SPN" SG_ 2364630014 ECd11IsttsCstTPt1 9979;
BA_ "SPN" SG_ 2364630014 ECd11IsttsCstTPt2 9980;
BA_ "SPN" SG_ 2364630270 ECd12IsttsSttCstT 9981;
BA_ "SPN" SG_ 2364630270 ECd12IsttsCtCstT 9982;
BA_ "SPN" SG_ 2364630270 ECd12IsttsCstTPt1 9983;
BA_ "SPN" SG_ 2364630270 ECd12IsttsCstTPt2 9984;
BA_ "SPN" SG_ 2364630526 ECd13IsttsSttCstT 9985;
BA_ "SPN" SG_ 2364630526 ECd13IsttsCtCstT 9986;
BA_ "SPN" SG_ 2364630526 ECd13IsttsCstTPt1 9987;
BA_ "SPN" SG_ 2364630526 ECd13IsttsCstTPt2 9988;
BA_ "SPN" SG_ 2364630782 ECd14IsttsSttCstT 9989;
BA_ "SPN" SG_ 2364630782 ECd14IsttsCtCstT 9990;
BA_ "SPN" SG_ 2364630782 ECd14IsttsCstTPt1 9991;
BA_ "SPN" SG_ 2364630782 ECd14IsttsCstTPt2 9992;
BA_ "SPN" SG_ 2364631038 ECd15IsttsSttCstT 9993;
BA_ "SPN" SG_ 2364631038 ECd15IsttsCtCstT 9994;
BA_ "SPN" SG_ 2364631038 ECd15IsttsCstTPt1 9995;
BA_ "SPN" SG_ 2364631038 ECd15IsttsCstTPt2 9996;
BA_ "SPN" SG_ 2364631294 ECd16IsttsSttCstT 9997;
BA_ "SPN" SG_ 2364631294 ECd16IsttsCtCstT 9998;
BA_ "SPN" SG_ 2364631294 ECd16IsttsCstTPt1 9999;
BA_ "SPN" SG_ 2364631294 ECd16IsttsCstTPt2 10000;
BA_ "SPN" SG_ 2364631550 ECd17IsttsSttCstT 10001;
BA_ "SPN" SG_ 2364631550 ECd17IsttsCtCstT 10002;
BA_ "SPN" SG_ 2364631550 ECd17IsttsCstTPt1 10003;
BA_ "SPN" SG_ 2364631550 ECd17IsttsCstTPt2 10004;
BA_ "SPN" SG_ 2364631806 ECd18IsttsSttCstT 10005;
BA_ "SPN" SG_ 2364631806 ECd18IsttsCtCstT 10006;
BA_ "SPN" SG_ 2364631806 ECd18IsttsCstTPt1 10007;
BA_ "SPN" SG_ 2364631806 ECd18IsttsCstTPt2 10008;
BA_ "SPN" SG_ 2364632062 ECd19IsttsSttCstT 10009;
BA_ "SPN" SG_ 2364632062 ECd19IsttsCtCstT 10010;
BA_ "SPN" SG_ 2364632062 ECd19IsttsCstTPt1 10011;
BA_ "SPN" SG_ 2364632062 ECd19IsttsCstTPt2 10012;
BA_ "SPN" SG_ 2364632318 ECd20IsttsSttCstT 10013;
BA_ "SPN" SG_ 2364632318 ECd20IsttsCtCstT 10014;
BA_ "SPN" SG_ 2364632318 ECd20IsttsCstTPt1 10015;
BA_ "SPN" SG_ 2364632318 ECd20IsttsCstTPt2 10016;
BA_ "SPN" SG_ 2364632574 ECd1IsttsPCstPssT 10017;
BA_ "SPN" SG_ 2364632574 ECd1IsttsIdtdMEtvPss 10018;
BA_ "SPN" SG_ 2364632574 ECd1IdtdMEtvPssCtV 10019;
BA_ "SPN" SG_ 2364632574 EngineCylinder1MisfireRate 1323;
BA_ "SPN" SG_ 2364632830 ECd2IsttsPCstPssT 10020;
BA_ "SPN" SG_ 2364632830 ECd2IsttsIdtdMEtvPss 10021;
BA_ "SPN" SG_ 2364632830 ECd2IdtdMEtvPssCtV 10022;
BA_ "SPN" SG_ 2364632830 EngineCylinder2MisfireRate 1324;
BA_ "SPN" SG_ 2364633086 ECd3IsttsPCstPssT 10023;
BA_ "SPN" SG_ 2364633086 ECd3IsttsIdtdMEtvPss 10024;
BA_ "SPN" SG_ 2364633086 ECd3IdtdMEtvPssCtV 10025;
BA_ "SPN" SG_ 2364633086 EngineCylinder3MisfireRate 1325;
BA_ "SPN" SG_ 2364633342 ECd4IsttsPCstPssT 10026;
BA_ "SPN" SG_ 2364633342 ECd4IsttsIdtdMEtvPss 10027;
BA_ "SPN" SG_ 2364633342 ECd4IdtdMEtvPssCtV 10028;
BA_ "SPN" SG_ 2364633342 EngineCylinder4MisfireRate 1326;
BA_ "SPN" SG_ 2364633598 ECd5IsttsPCstPssT 10029;
BA_ "SPN" SG_ 2364633598 ECd5IsttsIdtdMEtvPss 10030;
BA_ "SPN" SG_ 2364633598 ECd5IdtdMEtvPssCtV 10031;
BA_ "SPN" SG_ 2364633598 EngineCylinder5MisfireRate 1327;
BA_ "SPN" SG_ 2364633854 ECd6IsttsPCstPssT 10032;
BA_ "SPN" SG_ 2364633854 ECd6IsttsIdtdMEtvPss 10033;
BA_ "SPN" SG_ 2364633854 ECd6IdtdMEtvPssCtV 10034;
BA_ "SPN" SG_ 2364633854 EngineCylinder6MisfireRate 1328;
BA_ "SPN" SG_ 2364634110 ECd7IsttsPCstPssT 10035;
BA_ "SPN" SG_ 2364634110 ECd7IsttsIdtdMEtvPss 10036;
BA_ "SPN" SG_ 2364634110 ECd7IdtdMEtvPssCtV 10037;
BA_ "SPN" SG_ 2364634110 EngineCylinder7MisfireRate 1329;
BA_ "SPN" SG_ 2364634366 ECd8IsttsPCstPssT 10038;
BA_ "SPN" SG_ 2364634366 ECd8IsttsIdtdMEtvPss 10039;
BA_ "SPN" SG_ 2364634366 ECd8IdtdMEtvPssCtV 10040;
BA_ "SPN" SG_ 2364634366 EngineCylinder8MisfireRate 1330;
BA_ "SPN" SG_ 2364634622 ECd9IsttsPCstPssT 10041;
BA_ "SPN" SG_ 2364634622 ECd9IsttsIdtdMEtvPss 10042;
BA_ "SPN" SG_ 2364634622 ECd9IdtdMEtvPssCtV 10043;
BA_ "SPN" SG_ 2364634622 EngineCylinder9MisfireRate 1331;
BA_ "SPN" SG_ 2364634878 ECd10IsttsPCstPssT 10044;
BA_ "SPN" SG_ 2364634878 ECd10IsttsIdtdMEtvPss 10045;
BA_ "SPN" SG_ 2364634878 ECd10IdtdMEtvPssCtV 10046;
BA_ "SPN" SG_ 2364634878 EngineCylinder10MisfireRate 1332;
BA_ "SPN" SG_ 2364635134 ECd11IsttsPCstPssT 10047;
BA_ "SPN" SG_ 2364635134 ECd11IsttsIdtdMEtvPss 10048;
BA_ "SPN" SG_ 2364635134 ECd11IdtdMEtvPssCtV 10049;
BA_ "SPN" SG_ 2364635134 EngineCylinder11MisfireRate 1333;
BA_ "SPN" SG_ 2364635390 ECd12IsttsPCstPssT 10050;
BA_ "SPN" SG_ 2364635390 ECd12IsttsIdtdMEtvPss 10051;
BA_ "SPN" SG_ 2364635390 ECd12IdtdMEtvPssCtV 10052;
BA_ "SPN" SG_ 2364635390 EngineCylinder12MisfireRate 1334;
BA_ "SPN" SG_ 2364635646 ECd13IsttsPCstPssT 10053;
BA_ "SPN" SG_ 2364635646 ECd13IsttsIdtdMEtvPss 10054;
BA_ "SPN" SG_ 2364635646 ECd13IdtdMEtvPssCtV 10055;
BA_ "SPN" SG_ 2364635646 EngineCylinder13MisfireRate 1335;
BA_ "SPN" SG_ 2364635902 ECd14IsttsPCstPssT 10056;
BA_ "SPN" SG_ 2364635902 ECd14IsttsIdtdMEtvPss 10057;
BA_ "SPN" SG_ 2364635902 ECd14IdtdMEtvPssCtV 10058;
BA_ "SPN" SG_ 2364635902 EngineCylinder14MisfireRate 1336;
BA_ "SPN" SG_ 2364636158 ECd15IsttsPCstPssT 10059;
BA_ "SPN" SG_ 2364636158 ECd15IsttsIdtdMEtvPss 10060;
BA_ "SPN" SG_ 2364636158 ECd15IdtdMEtvPssCtV 10061;
BA_ "SPN" SG_ 2364636158 EngineCylinder15MisfireRate 1337;
BA_ "SPN" SG_ 2364636414 ECd16IsttsPCstPssT 10062;
BA_ "SPN" SG_ 2364636414 ECd16IsttsIdtdMEtvPss 10063;
BA_ "SPN" SG_ 2364636414 ECd16IdtdMEtvPssCtV 10064;
BA_ "SPN" SG_ 2364636414 EngineCylinder16MisfireRate 1338;
BA_ "SPN" SG_ 2364636670 ECd17IsttsPCstPssT 10065;
BA_ "SPN" SG_ 2364636670 ECd17IsttsIdtdMEtvPss 10066;
BA_ "SPN" SG_ 2364636670 ECd17IdtdMEtvPssCtV 10067;
BA_ "SPN" SG_ 2364636670 EngineCylinder17MisfireRate 1339;
BA_ "SPN" SG_ 2364636926 ECd18IsttsPCstPssT 10068;
BA_ "SPN" SG_ 2364636926 ECd18IsttsIdtdMEtvPss 10069;
BA_ "SPN" SG_ 2364636926 ECd18IdtdMEtvPssCtV 10070;
BA_ "SPN" SG_ 2364636926 EngineCylinder18MisfireRate 1340;
BA_ "SPN" SG_ 2364637182 ECd19IsttsPCstPssT 10071;
BA_ "SPN" SG_ 2364637182 ECd19IsttsIdtdMEtvPss 10072;
BA_ "SPN" SG_ 2364637182 ECd19IdtdMEtvPssCtV 10073;
BA_ "SPN" SG_ 2364637182 EngineCylinder19MisfireRate 1341;
BA_ "SPN" SG_ 2364637438 ECd20IsttsPCstPssT 10074;
BA_ "SPN" SG_ 2364637438 ECd20IsttsIdtdMEtvPss 10075;
BA_ "SPN" SG_ 2364637438 ECd20IdtdMEtvPssCtV 10076;
BA_ "SPN" SG_ 2364637438 EngineCylinder20MisfireRate 1342;
BA_ "SPN" SG_ 2364637694 MtrGnrtr1InvrtrMdFdk1CRC 10164;
BA_ "SPN" SG_ 2364637694 MtrGnrtr1InvrtrMdFdk1Cntr 10165;
BA_ "SPN" SG_ 2364637694 MtrGnrtr1InvrtrCntrlLmtsOvrrdMd 10166;
BA_ "SPN" SG_ 2364637694 MtrGnrtr1InvrtrCntrlStpntMd 10167;
BA_ "SPN" SG_ 2364637694 MtrGnrtr1InvrtrHVILStts 9103;
BA_ "SPN" SG_ 2565964542 MtrGnrtr1InvrtrLmtsAtvPwrCRC 10182;
BA_ "SPN" SG_ 2565964542 MtrGnrtr1InvrtrLmtsAtvPwrCntr 10183;
BA_ "SPN" SG_ 2565964798 MtrGnrtr1InvrtrLmtsAtvMhnlCRC 10194;
BA_ "SPN" SG_ 2565964798 MtrGnrtr1InvrtrLmtsAtvMhnlCntr 10195;
BA_ "SPN" SG_ 2565965054 MtrGnrtr1InvrtrLmtsAtvDCSdCRC 10210;
BA_ "SPN" SG_ 2565965054 MtrGnrtr1InvrtrLmtsAtvDCSdCntr 10211;
BA_ "SPN" SG_ 2565965310 MtrGnrtr1InvrtrSwthdIgntnVltg 9105;
BA_ "SPN" SG_ 2565965310 MtrGnrtr1InvrtrUnswthdSLIVltg 9117;
BA_ "SPN" SG_ 2364638974 MtrGnrtr2InvrtrMdFdk1CRC 10230;
BA_ "SPN" SG_ 2364638974 MtrGnrtr2InvrtrMdFdk1Cntr 10231;
BA_ "SPN" SG_ 2364638974 MtrGnrtr2InvrtrCntrlLmtsOvrrdMd 10232;
BA_ "SPN" SG_ 2364638974 MtrGnrtr2InvrtrCntrlStpntMd 10233;
BA_ "SPN" SG_ 2364638974 MtrGnrtr2InvrtrHVILStts 9104;
BA_ "SPN" SG_ 2565965822 MtrGnrtr2InvrtrLmtsAtvPwrCRC 10248;
BA_ "SPN" SG_ 2565965822 MtrGnrtr2InvrtrLmtsAtvPwrCntr 10249;
BA_ "SPN" SG_ 2565966078 MtrGnrtr2InvrtrLmtsAtvMhnlCRC 10260;
BA_ "SPN" SG_ 2565966078 MtrGnrtr2InvrtrLmtsAtvMhnlCntr 10261;
BA_ "SPN" SG_ 2565966334 MtrGnrtr2InvrtrLmtsAtvDCSdCRC 10276;
BA_ "SPN" SG_ 2565966334 MtrGnrtr2InvrtrLmtsAtvDCSdCntr 10277;
BA_ "SPN" SG_ 2565966590 MtrGnrtr2InvrtrSwthdIgntnVltg 9106;
BA_ "SPN" SG_ 2565966590 MtrGnrtr2InvrtrUnswthdSLIVltg 9118;
BA_ "SPN" SG_ 2365287678 MtrGnrtr2InvrtrRfrn1CRC 10234;
BA_ "SPN" SG_ 2365287678 MtrGnrtr2InvrtrRfrn1Cntr 10235;
BA_ "SPN" SG_ 2365287678 MtrGnrtr2InvrtrRfrnTrq 10236;
BA_ "SPN" SG_ 2365287678 MtrGnrtr2InvrtrRfrnSpd 10237;
BA_ "SPN" SG_ 2365287678 MtrGnrtr2InvrtrRfrnPwr 10238;
BA_ "SPN" SG_ 2365287934 MtrGnrtr2InvrtrStts1CRC 10239;
BA_ "SPN" SG_ 2365287934 MtrGnrtr2InvrtrStts1Cntr 10240;
BA_ "SPN" SG_ 2365287934 MotorGenerator2Speed 9058;
BA_ "SPN" SG_ 2365288190 MtrGnrtr2InvrtrRfrn2CRC 10266;
BA_ "SPN" SG_ 2365288190 MtrGnrtr2InvrtrRfrn2Cntr 10267;
BA_ "SPN" SG_ 2365288190 MtrGnrtr2InvrtrRfrnCrrnt 10268;
BA_ "SPN" SG_ 2365288190 MtrGnrtr2InvrtrRfrnVltg 10269;
BA_ "SPN" SG_ 2566615038 MtrGnrtr2InvrtrTmprtr1 10282;
BA_ "SPN" SG_ 2566615038 MtrGnrtr2InvrtrTmprtr2 10283;
BA_ "SPN" SG_ 2566615038 MtrGnrtr2InvrtrTmprtr3 10284;
BA_ "SPN" SG_ 2566615038 MtrGnrtr2InvrtrTmprtr4 10285;
BA_ "SPN" SG_ 2566615294 MotorGenerator2Temperature1 9060;
BA_ "SPN" SG_ 2566615294 MotorGenerator2Temperature2 10286;
BA_ "SPN" SG_ 2566615294 MotorGenerator2Temperature3 10287;
BA_ "SPN" SG_ 2566615294 MotorGenerator2Temperature4 10288;
BA_ "SPN" SG_ 2566615550 MotorGenerator1Temperature1 9059;
BA_ "SPN" SG_ 2566615550 MotorGenerator1Temperature2 10220;
BA_ "SPN" SG_ 2566615550 MotorGenerator1Temperature3 10221;
BA_ "SPN" SG_ 2566615550 MotorGenerator1Temperature4 10222;
BA_ "SPN" SG_ 2566615806 MtrGnrtr1InvrtrTmprtr1 10216;
BA_ "SPN" SG_ 2566615806 MtrGnrtr1InvrtrTmprtr2 10217;
BA_ "SPN" SG_ 2566615806 MtrGnrtr1InvrtrTmprtr3 10218;
BA_ "SPN" SG_ 2566615806 MtrGnrtr1InvrtrTmprtr4 10219;
BA_ "SPN" SG_ 2365289470 MtrGnrtr1InvrtrRfrn2CRC 10200;
BA_ "SPN" SG_ 2365289470 MtrGnrtr1InvrtrRfrn2Cntr 10201;
BA_ "SPN" SG_ 2365289470 MtrGnrtr1InvrtrRfrnCrrnt 10202;
BA_ "SPN" SG_ 2365289470 MtrGnrtr1InvrtrRfrnVltg 10203;
BA_ "SPN" SG_ 2365289726 MtrGnrtr1InvrtrStts1CRC 10173;
BA_ "SPN" SG_ 2365289726 MtrGnrtr1InvrtrStts1Cntr 10174;
BA_ "SPN" SG_ 2365289726 MotorGenerator1Torque 9061;
BA_ "SPN" SG_ 2365289726 MotorGenerator1Speed 9057;
BA_ "SPN" SG_ 2365289726 MtrGnrtr1InvrtrDCSdVltg 9101;
BA_ "SPN" SG_ 2365289982 MtrGnrtr1InvrtrRfrn1CRC 10168;
BA_ "SPN" SG_ 2365289982 MtrGnrtr1InvrtrRfrn1Cntr 10169;
BA_ "SPN" SG_ 2365289982 MtrGnrtr1InvrtrRfrnTrq 10170;
BA_ "SPN" SG_ 2365289982 MtrGnrtr1InvrtrRfrnSpd 10171;
BA_ "SPN" SG_ 2365289982 MtrGnrtr1InvrtrRfrnPwr 10172;
BA_ "SPN" SG_ 2566616830 DetectionLocation1 10133;
BA_ "SPN" SG_ 2566616830 DetectionZone1 10132;
BA_ "SPN" SG_ 2566616830 ZoneAlarmStatus1 10134;
BA_ "SPN" SG_ 2566616830 DetectionLocation2 10136;
BA_ "SPN" SG_ 2566616830 DetectionZone2 10135;
BA_ "SPN" SG_ 2566616830 ZoneAlarmStatus2 10137;
BA_ "SPN" SG_ 2566616830 DetectionLocation3 10139;
BA_ "SPN" SG_ 2566616830 DetectionZone3 10138;
BA_ "SPN" SG_ 2566616830 ZoneAlarmStatus3 10140;
BA_ "SPN" SG_ 2566616830 PersonnelDetectSequenceCounter 10141;
BA_ "SPN" SG_ 2566617086 EngnClndr1CmprssnGmmRt 10077;
BA_ "SPN" SG_ 2566617086 EngnClndr1ExpnsnGmmRt 10078;
BA_ "SPN" SG_ 2566617086 EngnClndr2CmprssnGmmRt 10079;
BA_ "SPN" SG_ 2566617086 EngnClndr2ExpnsnGmmRt 10080;
BA_ "SPN" SG_ 2566617086 EngnClndr3CmprssnGmmRt 10081;
BA_ "SPN" SG_ 2566617086 EngnClndr3ExpnsnGmmRt 10082;
BA_ "SPN" SG_ 2566617086 EngnClndr4CmprssnGmmRt 10083;
BA_ "SPN" SG_ 2566617086 EngnClndr4ExpnsnGmmRt 10084;
BA_ "SPN" SG_ 2566617342 EngnClndr5CmprssnGmmRt 10085;
BA_ "SPN" SG_ 2566617342 EngnClndr5ExpnsnGmmRt 10086;
BA_ "SPN" SG_ 2566617342 EngnClndr6CmprssnGmmRt 10087;
BA_ "SPN" SG_ 2566617342 EngnClndr6ExpnsnGmmRt 10088;
BA_ "SPN" SG_ 2566617342 EngnClndr7CmprssnGmmRt 10089;
BA_ "SPN" SG_ 2566617342 EngnClndr7ExpnsnGmmRt 10090;
BA_ "SPN" SG_ 2566617342 EngnClndr8CmprssnGmmRt 10091;
BA_ "SPN" SG_ 2566617342 EngnClndr8ExpnsnGmmRt 10092;
BA_ "SPN" SG_ 2566617598 EngnClndr9CmprssnGmmRt 10093;
BA_ "SPN" SG_ 2566617598 EngnClndr9ExpnsnGmmRt 10094;
BA_ "SPN" SG_ 2566617598 EngnClndr10CmprssnGmmRt 10095;
BA_ "SPN" SG_ 2566617598 EngnClndr10ExpnsnGmmRt 10096;
BA_ "SPN" SG_ 2566617598 EngnClndr11CmprssnGmmRt 10097;
BA_ "SPN" SG_ 2566617598 EngnClndr11ExpnsnGmmRt 10098;
BA_ "SPN" SG_ 2566617598 EngnClndr12CmprssnGmmRt 10099;
BA_ "SPN" SG_ 2566617598 EngnClndr12ExpnsnGmmRt 10100;
BA_ "SPN" SG_ 2566617854 EngnClndr13CmprssnGmmRt 10101;
BA_ "SPN" SG_ 2566617854 EngnClndr13ExpnsnGmmRt 10102;
BA_ "SPN" SG_ 2566617854 EngnClndr14CmprssnGmmRt 10103;
BA_ "SPN" SG_ 2566617854 EngnClndr14ExpnsnGmmRt 10104;
BA_ "SPN" SG_ 2566617854 EngnClndr15CmprssnGmmRt 10105;
BA_ "SPN" SG_ 2566617854 EngnClndr15ExpnsnGmmRt 10106;
BA_ "SPN" SG_ 2566617854 EngnClndr16CmprssnGmmRt 10107;
BA_ "SPN" SG_ 2566617854 EngnClndr16ExpnsnGmmRt 10108;
BA_ "SPN" SG_ 2566618110 EngnClndr17CmprssnGmmRt 10109;
BA_ "SPN" SG_ 2566618110 EngnClndr17ExpnsnGmmRt 10110;
BA_ "SPN" SG_ 2566618110 EngnClndr18CmprssnGmmRt 10111;
BA_ "SPN" SG_ 2566618110 EngnClndr18ExpnsnGmmRt 10112;
BA_ "SPN" SG_ 2566618110 EngnClndr19CmprssnGmmRt 10113;
BA_ "SPN" SG_ 2566618110 EngnClndr19ExpnsnGmmRt 10114;
BA_ "SPN" SG_ 2566618110 EngnClndr20CmprssnGmmRt 10115;
BA_ "SPN" SG_ 2566618110 EngnClndr20ExpnsnGmmRt 10116;
BA_ "SPN" SG_ 2566618622 GnrtrClntPmpEnlStts 9833;
BA_ "SPN" SG_ 2566618622 GnrtrClntPmpCntrllrSttsRsnCd 9834;
BA_ "SPN" SG_ 2566618622 GnrtrClntPmpCntrllrCmmndStts 9835;
BA_ "SPN" SG_ 2566618622 GeneratorCoolantPumpMotorSpeed 9836;
BA_ "SPN" SG_ 2566618622 GnrtrClntPmpCntrlTmprtr 9837;
BA_ "SPN" SG_ 2566618622 GeneratorCoolantPumpPower 9838;
BA_ "SPN" SG_ 2566618622 GnrtrClntPmpSrvIndtr 9839;
BA_ "SPN" SG_ 2566618622 GnrtrClntPmpOprtngStts 9840;
BA_ "SPN" SG_ 2566618878 GeneratorCoolantFanEnableStatus 9820;
BA_ "SPN" SG_ 2566618878 GnrtrClntFnCntrllrSttsRsnCd 9821;
BA_ "SPN" SG_ 2566618878 GnrtrClntFnCntrllrCmmndStts 9822;
BA_ "SPN" SG_ 2566618878 GeneratorCoolantFanMotorSpeed 9823;
BA_ "SPN" SG_ 2566618878 GnrtrClntFnCntrlTmprtr 9824;
BA_ "SPN" SG_ 2566618878 GeneratorCoolantFanPower 9825;
BA_ "SPN" SG_ 2566618878 GnrtrClntFnSrvIndtr 9826;
BA_ "SPN" SG_ 2566618878 GnrtrClntFnOprtngStts 9827;
BA_ "SPN" SG_ 2566619134 WllStmltnPmpOlFltrDffrntlPrssr 9813;
BA_ "SPN" SG_ 2566619134 WllStmltnPmpOlFltrOtltPrssr 9814;
BA_ "SPN" SG_ 2566619134 WllStmltnPmpOlFltrBpssSwthStts 9815;
BA_ "SPN" SG_ 2566619390 PrprgrmmdPTOGvrnrStSpd1 9778;
BA_ "SPN" SG_ 2566619390 PrprgrmmdPTOGvrnrStSpd2 9779;
BA_ "SPN" SG_ 2566619390 PrprgrmmdPTOGvrnrStSpd3 9780;
BA_ "SPN" SG_ 2566619390 PrprgrmmdPTOGvrnrStSpd4 9781;
BA_ "SPN" SG_ 2566619390 PrprgrmmdPTOGvrnrStSpd5 9782;
BA_ "SPN" SG_ 2566619390 PrprgrmmdPTOGvrnrStSpd6 9783;
BA_ "SPN" SG_ 2566619390 PrprgrmmdPTOGvrnrStSpd7 9784;
BA_ "SPN" SG_ 2566619390 PrprgrmmdPTOGvrnrStSpd8 9785;
BA_ "SPN" SG_ 2566619390 MinimumPTOGovernorSetSpeed 9786;
BA_ "SPN" SG_ 2566619390 MaximumPTOGovernorSetSpeed 9787;
BA_ "SPN" SG_ 2566619390 PTOGvrnrAlrtrOvrrdMxmmSpd 9788;
BA_ "SPN" SG_ 2566619646 OnBrdPrgrmmngInttECUAddrss 9776;
BA_ "SPN" SG_ 2566619646 OnBrdPrgrmmngInttRqst 9777;
BA_ "SPN" SG_ 2566619646 OnBrdPrgrmmngInttInht 9761;
BA_ "SPN" SG_ 2566620670 EngineIdleManagementStatus 9677;
BA_ "SPN" SG_ 2566620670 EngnIdlMngmntRstrtRsn 9678;
BA_ "SPN" SG_ 2566620670 EngnIdlMngmntShtdwnRsn 9679;
BA_ "SPN" SG_ 2566620670 IdlMngmntPndngEvntTmRmnng 10149;
BA_ "SPN" SG_ 2566621438 StationThrottlePositionMatch 9665;
BA_ "SPN" SG_ 2566621438 StationGearPositionMatch 9666;
BA_ "SPN" SG_ 2566621438 OprtrSttnAtvBttnStts 9667;
BA_ "SPN" SG_ 2566621438 TrollingModeButtonStatus 9668;
BA_ "SPN" SG_ 2566621438 EngnThrttlLvrSnhrnztnBttnStts 9669;
BA_ "SPN" SG_ 2566621438 GearLockoutButtonStatus 9670;
BA_ "SPN" SG_ 2566621438 SlowVesselModeButtonStatus 9671;
BA_ "SPN" SG_ 2566621438 OperatorStationActiveLampStatus 9672;
BA_ "SPN" SG_ 2566621438 TrollingModeLampStatus 9673;
BA_ "SPN" SG_ 2566621438 EngnThrttlLvrSnhrnztnLmpStts 9674;
BA_ "SPN" SG_ 2566621438 GearLockoutLampStatus 9675;
BA_ "SPN" SG_ 2566621438 SlowVesselModeLampStatus 9690;
BA_ "SPN" SG_ 2566621694 EngineOilPressure2 9653;
BA_ "SPN" SG_ 2365295358 HVES1BsVltgNgtvtChsssGrndVltg 9580;
BA_ "SPN" SG_ 2365295358 HVES1VltgLvlNgtvtChsssGrndVltg 9581;
BA_ "SPN" SG_ 2566622206 EconomyModeTotalHoursInactive 9578;
BA_ "SPN" SG_ 2566622206 EconomyModeTripHoursInactive 9579;
BA_ "SPN" SG_ 2566622462 EnmMdEstmtdInstntnsFlSvngsRt 9576;
BA_ "SPN" SG_ 2566622462 EMdEsttdIsttsFSvsRtPt 9577;
BA_ "SPN" SG_ 2566622718 EconomyModeTotalHoursActive 9574;
BA_ "SPN" SG_ 2566622718 EconomyModeTripHoursActive 9575;
BA_ "SPN" SG_ 2566622974 EconomyModeTotalFuelUsed 9572;
BA_ "SPN" SG_ 2566622974 EconomyModeTripFuelUsed 9573;
BA_ "SPN" SG_ 2566623230 EnmMdTtlEstmtdFlSvd 9570;
BA_ "SPN" SG_ 2566623230 EnmMdTrpEstmtdFlSvd 9571;
